VERSION "dbc-export 1 2025.20.8"

NS_ :

BS_:

BU_: APP BMS CC CMP CMPD CP DAS DI DIF DIR EPBL EPBR EVSE FC GTW HCML HCMR HVP ICR PCS PM PMF PMR PTC SCCM SCM SCS SDCR TAS UMC VC VCFRONT VCLEFT VCRIGHT VCSEC

BO_ 1523 UI_odo: 3 GTW
 SG_ UI_odometer : 0|24@1+ (0.1,0) [0|1677721.4] "km" Vector__XXX

BO_ 948 UI_peripheralPowerRequests: 1 GTW
 SG_ UI_usbFrontHubPowerStateRequest : 0|2@1+ (1,0) [1|3] "" Vector__XXX

BO_ 955 UI_power: 2 GTW
 SG_ UI_powerExpected : 0|8@1+ (1,0) [0|255] "kW" Vector__XXX
 SG_ UI_powerIdeal : 8|8@1+ (1,0) [0|255] "kW" Vector__XXX

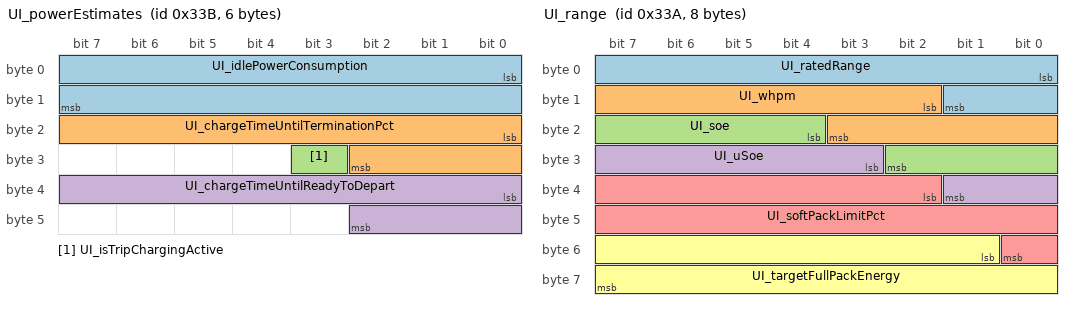
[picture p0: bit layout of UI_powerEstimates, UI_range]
BO_ 827 UI_powerEstimates: 6 GTW
 SG_ UI_idlePowerConsumption : 0|16@1+ (0.001,0) [0|50] "kW" Vector__XXX
 SG_ UI_chargeTimeUntilTerminationPct : 16|11@1+ (1,0) [0|2046] "min" Vector__XXX
 SG_ UI_isTripChargingActive : 27|1@1+ (1,0) [0|1] "" Vector__XXX
 SG_ UI_chargeTimeUntilReadyToDepart : 32|11@1+ (1,0) [0|2046] "min" Vector__XXX

BO_ 661 UI_powerRationalityConfig: 8 GTW
 SG_ UI_powerRationalityConfigIndex M : 56|8@1+ (1,0) [0|255] "" Vector__XXX
 SG_ UI_vcleftCfgRationalityThreshold m0 : 0|4@1+ (1,0) [1|15] "" Vector__XXX
 SG_ UI_vcleftCfgRationalityTime0 m0 : 4|4@1+ (1,0) [1|15] "" Vector__XXX
 SG_ UI_vcleftCfgRationalityThre_0001 m0 : 8|4@1+ (1,0) [1|15] "" Vector__XXX
 SG_ UI_vcleftCfgRationalityTime1 m0 : 12|4@1+ (1,0) [1|15] "" Vector__XXX
 SG_ UI_vcleftCfgRationalityStaticA m1 : 0|16@1+ (50,0) [0|3276700] "-" Vector__XXX
 SG_ UI_vcleftCfgRationalityStaticB m1 : 16|16@1- (1,0) [-32768|32767] "-" Vector__XXX
 SG_ UI_vcleftCfgRationalityStaticC m1 : 32|16@1- (50,0) [-1638400|1638350] "-" Vector__XXX
 SG_ UI_vcleftCfgRationalityDynamicA m2 : 0|16@1+ (50,0) [0|3276700] "-" Vector__XXX
 SG_ UI_vcleftCfgRationalityDynamicB m2 : 16|16@1- (1,0) [-32768|32767] "-" Vector__XXX
 SG_ UI_vcleftCfgRationalityDynamicC m2 : 32|16@1- (50,0) [-1638400|1638350] "-" Vector__XXX
 SG_ UI_vcrightCfgRationalityThreshol m3 : 0|4@1+ (1,0) [1|15] "" Vector__XXX
 SG_ UI_vcrightCfgRationalityTime0 m3 : 4|4@1+ (1,0) [1|15] "" Vector__XXX
 SG_ UI_vcrightCfgRationalityThr_0001 m3 : 8|4@1+ (1,0) [1|15] "" Vector__XXX
 SG_ UI_vcrightCfgRationalityTime1 m3 : 12|4@1+ (1,0) [1|15] "" Vector__XXX
 SG_ UI_vcrightCfgRationalityStaticA m4 : 0|16@1+ (50,0) [0|3276700] "-" Vector__XXX
 SG_ UI_vcrightCfgRationalityStaticB m4 : 16|16@1- (1,0) [-32768|32767] "-" Vector__XXX
 SG_ UI_vcrightCfgRationalityStaticC m4 : 32|16@1- (50,0) [-1638400|1638350] "-" Vector__XXX
 SG_ UI_vcrightCfgRationalityDynamicA m5 : 0|16@1+ (50,0) [0|3276700] "-" Vector__XXX
 SG_ UI_vcrightCfgRationalityDynamicB m5 : 16|16@1- (1,0) [-32768|32767] "-" Vector__XXX
 SG_ UI_vcrightCfgRationalityDynamicC m5 : 32|16@1- (50,0) [-1638400|1638350] "-" Vector__XXX
 SG_ UI_vcleftCfgCutoffThreshold0 m6 : 0|4@1+ (1,0) [1|15] "" Vector__XXX
 SG_ UI_vcleftCfgCutoffTime0 m6 : 4|4@1+ (1,0) [1|15] "" Vector__XXX
 SG_ UI_vcleftCfgCutoffThreshold1 m6 : 8|4@1+ (1,0) [1|15] "" Vector__XXX
 SG_ UI_vcleftCfgCutoffTime1 m6 : 12|4@1+ (1,0) [1|15] "" Vector__XXX
 SG_ UI_vcleftCfgCutoffStaticA m7 : 0|16@1+ (50,0) [0|3276700] "-" Vector__XXX
 SG_ UI_vcleftCfgCutoffStaticB m7 : 16|16@1- (1,0) [-32768|32767] "-" Vector__XXX
 SG_ UI_vcleftCfgCutoffStaticC m7 : 32|16@1- (50,0) [-1638400|1638350] "-" Vector__XXX
 SG_ UI_vcleftCfgCutoffDynamicA m8 : 0|16@1+ (50,0) [0|3276700] "-" Vector__XXX
 SG_ UI_vcleftCfgCutoffDynamicB m8 : 16|16@1- (1,0) [-32768|32767] "-" Vector__XXX
 SG_ UI_vcleftCfgCutoffDynamicC m8 : 32|16@1- (50,0) [-1638400|1638350] "-" Vector__XXX
 SG_ UI_vcrightCfgCutoffThreshold0 m9 : 0|4@1+ (1,0) [1|15] "" Vector__XXX
 SG_ UI_vcrightCfgCutoffTime0 m9 : 4|4@1+ (1,0) [1|15] "" Vector__XXX
 SG_ UI_vcrightCfgCutoffThreshold1 m9 : 8|4@1+ (1,0) [1|15] "" Vector__XXX
 SG_ UI_vcrightCfgCutoffTime1 m9 : 12|4@1+ (1,0) [1|15] "" Vector__XXX
 SG_ UI_vcrightCfgCutoffStaticA m10 : 0|16@1+ (50,0) [0|3276700] "-" Vector__XXX
 SG_ UI_vcrightCfgCutoffStaticB m10 : 16|16@1- (1,0) [-32768|32767] "-" Vector__XXX
 SG_ UI_vcrightCfgCutoffStaticC m10 : 32|16@1- (50,0) [-1638400|1638350] "-" Vector__XXX
 SG_ UI_vcrightCfgCutoffDynamicA m11 : 0|16@1+ (50,0) [0|3276700] "-" Vector__XXX
 SG_ UI_vcrightCfgCutoffDynamicB m11 : 16|16@1- (1,0) [-32768|32767] "-" Vector__XXX
 SG_ UI_vcrightCfgCutoffDynamicC m11 : 32|16@1- (50,0) [-1638400|1638350] "-" Vector__XXX

BO_ 820 UI_powertrainControl: 8 GTW
 SG_ UI_systemPowerLimit : 0|5@1+ (20,20) [20|620] "kW" Vector__XXX
 SG_ UI_pedalMap : 5|2@1+ (1,0) [0|3] "" Vector__XXX
 SG_ UI_enableRegenBackfill : 7|1@1+ (1,0) [0|1] "" Vector__XXX
 SG_ UI_systemTorqueLimit : 8|6@1+ (150,1000) [1000|10300] "Nm" Vector__XXX
 SG_ UI_closureConfirmed : 14|2@1+ (1,0) [0|3] "" Vector__XXX
 SG_ UI_regenTorqueMax : 16|5@1+ (5,0) [0|100] "%" Vector__XXX
 SG_ UI_limitMode : 21|2@1+ (1,0) [0|3] "" Vector__XXX
 SG_ UI_factoryCustomerDrivingModeReq : 23|1@1+ (1,0) [0|1] "" Vector__XXX
 SG_ UI_motorOnMode : 24|2@1+ (1,0) [0|3] "" Vector__XXX
 SG_ UI_wasteMode : 26|2@1+ (1,0) [0|3] "" Vector__XXX
 SG_ UI_wasteModeRegenLimit : 28|2@1+ (1,0) [0|3] "" Vector__XXX
 SG_ UI_stoppingMode : 30|2@1+ (1,0) [0|3] "" Vector__XXX
 SG_ UI_DIAppSliderDebug : 32|2@1+ (1,0) [0|3] "" Vector__XXX
 SG_ UI_speedLimit : 34|12@1+ (0.1,0) [0|335] "kph" Vector__XXX
 SG_ UI_enableSmartShift : 46|2@1+ (1,0) [0|3] "" Vector__XXX
 SG_ UI_navVehParallelToRdCanContinue : 49|2@1+ (1,0) [1|3] "" Vector__XXX
 SG_ UI_powertrainControlCounter : 52|4@1+ (1,0) [0|15] "" Vector__XXX
 SG_ UI_powertrainControlChecksum : 56|8@1+ (1,0) [0|255] "" Vector__XXX

BO_ 826 UI_range: 8 GTW
 SG_ UI_ratedRange : 0|10@1+ (1,0) [0|1023] "mi" Vector__XXX
 SG_ UI_whpm : 10|10@1+ (1,0) [0|1023] "" Vector__XXX
 SG_ UI_soe : 20|7@1+ (1,0) [0|127] "%" Vector__XXX
 SG_ UI_uSoe : 27|7@1+ (1,0) [0|127] "%" Vector__XXX
 SG_ UI_softPackLimitPct : 34|15@1+ (0.003051851,0) [0|100.000001717] "%" Vector__XXX
 SG_ UI_targetFullPackEnergy : 49|15@1+ (0.006103702,0) [0|200.000003434] "kWh" Vector__XXX

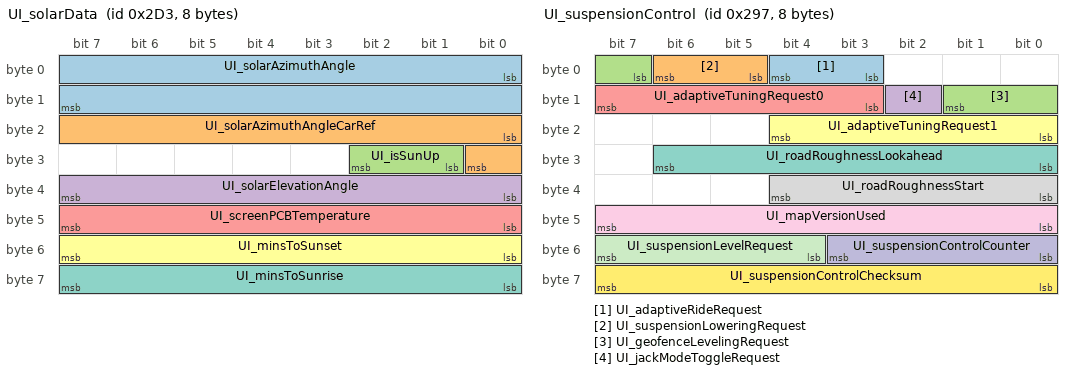
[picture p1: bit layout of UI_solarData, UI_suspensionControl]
BO_ 723 UI_solarData: 8 GTW
 SG_ UI_solarAzimuthAngle : 0|16@1- (1,0) [-32768|32767] "degrees" Vector__XXX
 SG_ UI_solarAzimuthAngleCarRef : 16|9@1- (1,0) [-256|254] "degrees" Vector__XXX
 SG_ UI_isSunUp : 25|2@1+ (1,0) [0|2] "" Vector__XXX
 SG_ UI_solarElevationAngle : 32|8@1- (1,0) [-128|126] "degrees" Vector__XXX
 SG_ UI_screenPCBTemperature : 40|8@1- (0.5,40) [-20|100] "degC" Vector__XXX
 SG_ UI_minsToSunset : 48|8@1+ (10,0) [0|2550] "min" Vector__XXX
 SG_ UI_minsToSunrise : 56|8@1+ (10,0) [0|2550] "min" Vector__XXX

BO_ 851 UI_status: 8 GTW
 SG_ UI_touchActive : 0|1@1+ (1,0) [0|1] "" Vector__XXX
 SG_ UI_audioActive : 1|1@1+ (1,0) [0|1] "" Vector__XXX
 SG_ UI_bluetoothActive : 2|1@1+ (1,0) [0|1] "" Vector__XXX
 SG_ UI_cellActive : 3|1@1+ (1,0) [0|1] "" Vector__XXX
 SG_ UI_displayReady : 4|1@1+ (1,0) [0|1] "" Vector__XXX
 SG_ UI_displayOn : 5|1@1+ (1,0) [0|1] "" Vector__XXX
 SG_ UI_wifiActive : 6|1@1+ (1,0) [0|1] "" Vector__XXX
 SG_ UI_wifiConnected : 7|1@1+ (1,0) [0|1] "" Vector__XXX
 SG_ UI_systemActive : 8|1@1+ (1,0) [0|1] "" Vector__XXX
 SG_ UI_readyForDrive : 9|1@1+ (1,0) [0|1] "" Vector__XXX
 SG_ UI_cellConnected : 10|1@1+ (1,0) [0|1] "" Vector__XXX
 SG_ UI_vpnActive : 11|1@1+ (1,0) [0|1] "" Vector__XXX
 SG_ UI_autopilotTrial : 12|2@1+ (1,0) [0|3] "" Vector__XXX
 SG_ UI_factoryReset : 14|2@1+ (1,0) [1|3] "" Vector__XXX
 SG_ UI_gpsActive : 16|1@1+ (1,0) [0|1] "" Vector__XXX
 SG_ UI_screenshotActive : 17|1@1+ (1,0) [0|1] "" Vector__XXX
 SG_ UI_radioActive : 18|1@1+ (1,0) [0|1] "" Vector__XXX
 SG_ UI_cellNetworkTechnology : 19|4@1+ (1,0) [0|14] "" Vector__XXX
 SG_ UI_cellReceiverPower : 24|8@1+ (1,-128) [-128|127] "dB" Vector__XXX
 SG_ UI_falseTouchCounter : 32|8@1+ (1,0) [0|255] "1" Vector__XXX
 SG_ UI_developmentCar : 40|1@1+ (1,0) [0|1] "" Vector__XXX
 SG_ UI_cameraActive : 41|1@1+ (1,0) [0|1] "" Vector__XXX
 SG_ UI_cellSignalBars : 42|3@1+ (1,0) [0|6] "" Vector__XXX
 SG_ UI_trailerModeTelltale : 45|2@1+ (1,0) [0|3] "" Vector__XXX
 SG_ UI_pcbTemperature : 48|8@1- (1,40) [-20|100] "degC" Vector__XXX
 SG_ UI_cpuTemperature : 56|8@1- (1,40) [-20|100] "degC" Vector__XXX

BO_ 991 UI_status2: 8 GTW
 SG_ UI_mobileAppStepCount : 0|16@1+ (1,0) [0|65535] "" Vector__XXX
 SG_ UI_userRequestSnapshot : 16|1@1+ (1,0) [0|1] "" Vector__XXX
 SG_ UI_touchDetected : 17|1@1+ (1,0) [0|1] "" Vector__XXX
 SG_ UI_validDeviceForEUSummon : 18|1@1+ (1,0) [0|1] "" Vector__XXX
 SG_ UI_locatedAtHome : 19|1@1+ (1,0) [0|1] "" Vector__XXX
 SG_ UI_locatedAtWork : 20|1@1+ (1,0) [0|1] "" Vector__XXX
 SG_ UI_locatedAtFavorite : 21|1@1+ (1,0) [0|1] "" Vector__XXX
 SG_ UI_displayInDarkMode : 22|1@1+ (1,0) [0|1] "" Vector__XXX
 SG_ UI_userActivity : 23|1@1+ (1,0) [0|1] "" Vector__XXX
 SG_ UI_activeTouchPoints : 24|8@1+ (1,0) [0|255] "1" Vector__XXX
 SG_ UI_linkState : 32|2@1+ (1,0) [0|3] "" Vector__XXX
 SG_ UI_sentryModeState : 34|3@1+ (1,0) [0|7] "" Vector__XXX
 SG_ UI_autopilotSentryRequest : 37|1@1+ (1,0) [0|1] "" Vector__XXX
 SG_ UI_mobileAppConnected : 38|1@1+ (1,0) [0|1] "" Vector__XXX
 SG_ UI_autoshiftDRState : 40|3@1+ (1,0) [0|7] "" Vector__XXX
 SG_ UI_wifiBtModuleType : 43|3@1+ (1,0) [0|7] "" Vector__XXX
 SG_ UI_sohHealthStatus : 46|2@1+ (1,0) [0|3] "" Vector__XXX
 SG_ UI_selfParkState : 48|8@1+ (1,0) [0|254] "" Vector__XXX
 SG_ UI_summonDeviceIndex : 56|2@1+ (1,0) [0|3] "" Vector__XXX
 SG_ UI_sentryModeCameraDetection : 58|1@1+ (1,0) [0|1] "" Vector__XXX
 SG_ UI_wakeOnIPActive : 59|1@1+ (1,0) [0|1] "" Vector__XXX

BO_ 663 UI_suspensionControl: 8 GTW
 SG_ UI_adaptiveRideRequest : 3|2@1+ (1,0) [0|3] "" Vector__XXX
 SG_ UI_suspensionLoweringRequest : 5|2@1+ (1,0) [0|2] "" Vector__XXX
 SG_ UI_geofenceLevelingRequest : 7|3@1+ (1,0) [0|7] "" Vector__XXX
 SG_ UI_jackModeToggleRequest : 10|1@1+ (1,0) [0|1] "" Vector__XXX
 SG_ UI_adaptiveTuningRequest0 : 11|5@1- (0.1,0) [-1.6|1.5] "-" Vector__XXX
 SG_ UI_adaptiveTuningRequest1 : 16|5@1- (0.1,0) [-1.6|1.5] "-" Vector__XXX
 SG_ UI_roadRoughnessLookahead : 24|7@1+ (0.01,0) [0|1.26] "%" Vector__XXX
 SG_ UI_roadRoughnessStart : 32|5@1+ (10,0) [0|300] "m" Vector__XXX
 SG_ UI_mapVersionUsed : 40|8@1+ (1,0) [0|254] "-" Vector__XXX
 SG_ UI_suspensionControlCounter : 48|4@1+ (1,0) [0|15] "" Vector__XXX
 SG_ UI_suspensionLevelRequest : 52|4@1+ (1,0) [0|15] "" Vector__XXX
 SG_ UI_suspensionControlChecksum : 56|8@1+ (1,0) [0|255] "" Vector__XXX

BO_ 956 UI_tpmsRCPsetting: 4 GTW
 SG_ UI_setRCPFront : 16|8@1+ (0.025,0) [0|6.375] "bar" Vector__XXX
 SG_ UI_setRCPRear : 24|8@1+ (0.025,0) [0|6.375] "bar" Vector__XXX

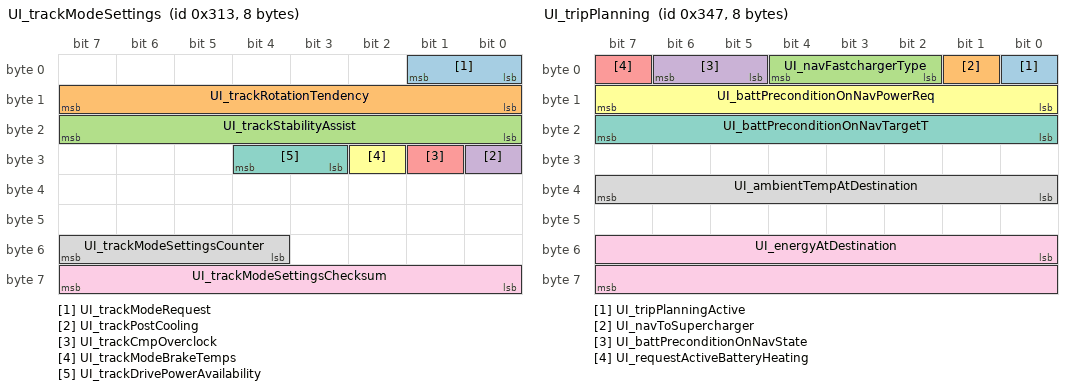
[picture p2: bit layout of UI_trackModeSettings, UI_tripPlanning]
BO_ 787 UI_trackModeSettings: 8 GTW
 SG_ UI_trackModeRequest : 0|2@1+ (1,0) [0|3] "" Vector__XXX
 SG_ UI_trackRotationTendency : 8|8@1+ (0.5,0) [0|127.5] "%" Vector__XXX
 SG_ UI_trackStabilityAssist : 16|8@1+ (0.5,0) [0|127.5] "%" Vector__XXX
 SG_ UI_trackPostCooling : 24|1@1+ (1,0) [0|1] "" Vector__XXX
 SG_ UI_trackCmpOverclock : 25|1@1+ (1,0) [0|1] "" Vector__XXX
 SG_ UI_trackModeBrakeTemps : 26|1@1+ (1,0) [0|1] "" Vector__XXX
 SG_ UI_trackDrivePowerAvailability : 27|2@1+ (1,0) [0|3] "" Vector__XXX
 SG_ UI_trackModeSettingsCounter : 52|4@1+ (1,0) [0|15] "" Vector__XXX
 SG_ UI_trackModeSettingsChecksum : 56|8@1+ (1,0) [0|255] "" Vector__XXX

BO_ 839 UI_tripPlanning: 8 GTW
 SG_ UI_tripPlanningActive : 0|1@1+ (1,0) [0|1] "" Vector__XXX
 SG_ UI_navToSupercharger : 1|1@1+ (1,0) [0|1] "" Vector__XXX
 SG_ UI_navFastchargerType : 2|3@1+ (1,0) [0|7] "" Vector__XXX
 SG_ UI_battPreconditionOnNavState : 5|2@1+ (1,0) [0|3] "" Vector__XXX
 SG_ UI_requestActiveBatteryHeating : 7|1@1+ (1,0) [0|1] "" Vector__XXX
 SG_ UI_battPreconditionOnNavPowerReq : 8|8@1- (125,0) [-16000|15750] "W" Vector__XXX
 SG_ UI_battPreconditionOnNavTargetT : 16|8@1+ (0.25,0) [0|63.5] "degC" Vector__XXX
 SG_ UI_ambientTempAtDestination : 32|8@1- (0.5,0) [-64|63.5] "degC" Vector__XXX
 SG_ UI_energyAtDestination : 48|16@1- (0.01,0) [-327.67|327.67] "kWh" Vector__XXX

BO_ 627 UI_vehicleControl: 8 GTW
 SG_ UI_powerStateRequest : 0|2@1+ (1,0) [0|3] "" Vector__XXX
 SG_ UI_childDoorLockOnRight : 2|1@1+ (1,0) [0|1] "" Vector__XXX
 SG_ UI_frontFogSwitch : 3|1@1+ (1,0) [0|1] "" Vector__XXX
 SG_ UI_summonActive : 4|1@1+ (1,0) [0|1] "" Vector__XXX
 SG_ UI_frunkRequest : 5|1@1+ (1,0) [0|1] "" Vector__XXX
 SG_ UI_wiperMode : 6|2@1+ (1,0) [1|3] "" Vector__XXX
 SG_ UI_steeringBacklightEnabled : 8|1@1+ (1,0) [0|1] "" Vector__XXX
 SG_ UI_steeringButtonMode : 9|3@1+ (1,0) [0|7] "" Vector__XXX
 SG_ UI_walkUpUnlock : 12|1@1+ (1,0) [0|1] "" Vector__XXX
 SG_ UI_walkAwayLock : 13|1@1+ (1,0) [0|1] "" Vector__XXX
 SG_ UI_unlockOnPark : 14|1@1+ (1,0) [0|1] "" Vector__XXX
 SG_ UI_globalUnlockOn : 15|1@1+ (1,0) [0|1] "" Vector__XXX
 SG_ UI_childDoorLockOnLeft : 16|1@1+ (1,0) [0|1] "" Vector__XXX
 SG_ UI_lockRequest : 17|3@1+ (1,0) [0|6] "" Vector__XXX
 SG_ UI_alarmEnabled : 20|1@1+ (1,0) [0|1] "" Vector__XXX
 SG_ UI_intrusionSensorOn : 21|1@1+ (1,0) [0|1] "" Vector__XXX
 SG_ UI_stop12vSupport : 22|1@1+ (1,0) [0|1] "" Vector__XXX
 SG_ UI_rearFogSwitch : 23|1@1+ (1,0) [0|1] "" Vector__XXX
 SG_ UI_mirrorFoldRequest : 24|2@1+ (1,0) [0|2] "" Vector__XXX
 SG_ UI_mirrorHeatRequest : 26|1@1+ (1,0) [0|1] "" Vector__XXX
 SG_ UI_remoteStartRequest : 27|3@1+ (1,0) [0|7] "" Vector__XXX
 SG_ UI_seeYouHomeLightingOn : 30|1@1+ (1,0) [0|1] "" Vector__XXX
 SG_ UI_powerOff : 31|1@1+ (1,0) [0|1] "" Vector__XXX
 SG_ UI_displayBrightnessLevel : 32|8@1+ (0.5,0) [0|127] "%" Vector__XXX
 SG_ UI_ambientLightingEnabled : 40|1@1+ (1,0) [0|1] "" Vector__XXX
 SG_ UI_autoHighBeamEnabled : 41|1@1+ (1,0) [0|1] "" Vector__XXX
 SG_ UI_frontLeftSeatHeatReq : 42|2@1+ (1,0) [0|3] "" Vector__XXX
 SG_ UI_frontRightSeatHeatReq : 44|2@1+ (1,0) [0|3] "" Vector__XXX
 SG_ UI_rearLeftSeatHeatReq : 46|2@1+ (1,0) [0|3] "" Vector__XXX
 SG_ UI_rearCenterSeatHeatReq : 48|2@1+ (1,0) [0|3] "" Vector__XXX
 SG_ UI_rearRightSeatHeatReq : 50|2@1+ (1,0) [0|3] "" Vector__XXX
 SG_ UI_autoFoldMirrorsOn : 52|1@1+ (1,0) [0|1] "" Vector__XXX
 SG_ UI_mirrorDipOnReverse : 53|1@1+ (1,0) [0|1] "" Vector__XXX
 SG_ UI_remoteClosureRequest : 54|2@1+ (1,0) [0|2] "" Vector__XXX
 SG_ UI_wiperRequest : 56|3@1+ (1,0) [1|7] "" Vector__XXX
 SG_ UI_domeLightSwitch : 59|2@1+ (1,0) [0|3] "" Vector__XXX
 SG_ UI_honkHorn : 61|1@1+ (1,0) [0|1] "" Vector__XXX
 SG_ UI_driveStateRequest : 62|1@1+ (1,0) [0|1] "" Vector__XXX
 SG_ UI_rearWindowLockout : 63|1@1+ (1,0) [0|1] "" Vector__XXX

BO_ 947 UI_vehicleControl2: 8 GTW
 SG_ UI_gloveboxRequest : 0|1@1+ (1,0) [0|1] "" Vector__XXX
 SG_ UI_trunkRequest : 1|1@1+ (1,0) [0|1] "" Vector__XXX
 SG_ UI_UMCUpdateInhibit : 2|1@1+ (1,0) [0|1] "" Vector__XXX
 SG_ UI_WCUpdateInhibit : 3|1@1+ (1,0) [0|1] "" Vector__XXX
 SG_ UI_soundHornOnLock : 4|1@1+ (1,0) [0|1] "" Vector__XXX
 SG_ UI_locksPanelActive : 5|1@1+ (1,0) [0|1] "" Vector__XXX
 SG_ UI_PINToDriveEnabled : 6|1@1+ (1,0) [0|1] "" Vector__XXX
 SG_ UI_PINToDrivePassed : 7|1@1+ (1,0) [0|1] "" Vector__XXX
 SG_ UI_disableMirrorAutoDim : 8|1@1+ (1,0) [0|1] "" Vector__XXX
 SG_ UI_lightSwitch : 9|3@1+ (1,0) [0|7] "" Vector__XXX
 SG_ UI_readyToAddKey : 12|1@1+ (1,0) [0|1] "" Vector__XXX
 SG_ UI_alarmTriggerRequest : 13|1@1+ (1,0) [0|1] "" Vector__XXX
 SG_ UI_VCSECFeature1 : 14|1@1+ (1,0) [0|1] "" Vector__XXX
 SG_ UI_VCLEFTFeature1 : 15|1@1+ (1,0) [0|1] "" Vector__XXX
 SG_ UI_summonState : 16|2@1+ (1,0) [1|3] "" Vector__XXX
 SG_ UI_displayOnForUser : 18|1@1+ (1,0) [0|1] "" Vector__XXX
 SG_ UI_freeRollModeRequest : 19|1@1+ (1,0) [0|1] "" Vector__XXX
 SG_ UI_BLEPushNotificationRequest : 20|1@1+ (1,0) [0|1] "" Vector__XXX
 SG_ UI_pairKeyQRCodeDisplaying : 21|1@1+ (1,0) [0|1] "" Vector__XXX
 SG_ UI_keepAutopilotAwake : 22|1@1+ (1,0) [0|1] "" Vector__XXX
 SG_ UI_batteryPreconditioningRequest : 23|1@1+ (1,0) [0|1] "" Vector__XXX
 SG_ UI_coastDownMode : 24|1@1+ (1,0) [0|1] "" Vector__XXX
 SG_ UI_autopilotPowerStateRequest : 25|2@1+ (1,0) [0|3] "" Vector__XXX
 SG_ UI_shorted12VCellTestMode : 27|2@1+ (1,0) [0|3] "" Vector__XXX
 SG_ UI_autoRollWindowsOnLockEnable : 29|1@1+ (1,0) [0|1] "" Vector__XXX
 SG_ UI_virtualPitchSensorOverrideOKF : 30|1@1+ (1,0) [0|1] "" Vector__XXX
 SG_ UI_conditionalLoggingEnabledVCSE : 31|1@1+ (1,0) [0|1] "" Vector__XXX
 SG_ UI_WC3UpdateInhibit : 32|1@1+ (1,0) [0|1] "" Vector__XXX
 SG_ UI_steeringWheelHeatReq : 33|1@1+ (1,0) [0|1] "" Vector__XXX
 SG_ UI_disableHorn : 34|1@1+ (1,0) [0|1] "" Vector__XXX
 SG_ UI_frontLeftSeatFanReq : 37|2@1+ (1,0) [0|3] "" Vector__XXX
 SG_ UI_frontRightSeatAutoClimateReq : 39|1@1+ (1,0) [0|1] "" Vector__XXX
 SG_ UI_frontRightSeatFanReq : 40|2@1+ (1,0) [0|3] "" Vector__XXX
 SG_ UI_sleepFeature1 : 51|1@1+ (1,0) [0|1] "" Vector__XXX
 SG_ UI_dcr12VThreshold : 52|4@1+ (1,0) [0|15] "" Vector__XXX
 SG_ UI_frontLeftSeatAutoClimateReq : 56|1@1+ (1,0) [0|1] "" Vector__XXX
 SG_ UI_wiperHeaterReq : 57|1@1+ (1,0) [0|1] "" Vector__XXX
 SG_ UI_tireSeason : 59|1@1+ (1,0) [0|1] "" Vector__XXX
 SG_ UI_saveTireConfigReq : 60|1@1+ (1,0) [0|1] "" Vector__XXX
 SG_ UI_silentAlarm : 61|1@1+ (1,0) [0|1] "" Vector__XXX
 SG_ UI_sleepFeature2 : 63|1@1+ (1,0) [0|1] "" Vector__XXX

BO_ 660 UI_vehicleControl3: 8 GTW
 SG_ UI_lightFlashRequest : 0|2@1+ (1,0) [0|3] "" Vector__XXX
 SG_ UI_keylessDrivingEnabled : 2|1@1+ (1,0) [0|1] "" Vector__XXX
 SG_ UI_phoneCallActive : 3|1@1+ (1,0) [0|1] "" Vector__XXX
 SG_ UI_drivingSideVEH : 4|2@1+ (1,0) [0|3] "" Vector__XXX
 SG_ UI_keyPairResponse : 6|2@1+ (1,0) [0|3] "" Vector__XXX
 SG_ UI_lightShowClosuresEnabled : 8|1@1+ (1,0) [0|1] "" Vector__XXX
 SG_ UI_steeringWheelHeatAutoReq : 9|1@1+ (1,0) [0|1] "" Vector__XXX
 SG_ UI_steeringWheelHeatLevelReq : 10|2@1+ (1,0) [0|3] "" Vector__XXX
 SG_ UI_headlightPulseRequest : 12|1@1+ (1,0) [0|1] "" Vector__XXX
 SG_ UI_VCSECFeature2 : 13|1@1+ (1,0) [0|1] "" Vector__XXX
 SG_ UI_VCSECFeature3 : 14|1@1+ (1,0) [0|1] "" Vector__XXX
 SG_ UI_VCSECFeature4 : 15|1@1+ (1,0) [0|1] "" Vector__XXX
 SG_ UI_VCSECFeature5 : 16|1@1+ (1,0) [0|1] "" Vector__XXX
 SG_ UI_shortHornRequest : 17|1@1+ (1,0) [0|1] "" Vector__XXX
 SG_ UI_packTempLoggingRequest : 18|1@1+ (1,0) [0|1] "" Vector__XXX
 SG_ UI_UMC3UpdateInhibit : 22|1@1+ (1,0) [0|1] "" Vector__XXX
 SG_ UI_handsFreeTrunk : 23|1@1+ (1,0) [0|1] "" Vector__XXX
 SG_ UI_displayRedShiftActive : 24|1@1+ (1,0) [0|1] "" Vector__XXX
 SG_ UI_handsFreeFrunk : 25|1@1+ (1,0) [0|1] "" Vector__XXX
 SG_ UI_fasciaCameraWashRequest : 26|1@1+ (1,0) [0|1] "" Vector__XXX
 SG_ UI_autoClosuresExcludeHome : 27|1@1+ (1,0) [0|1] "" Vector__XXX
 SG_ UI_leftRearSeatAdjustmentRequest : 28|3@1+ (1,0) [0|7] "" Vector__XXX
 SG_ UI_rightRearSeatAdjustmentReques : 32|3@1+ (1,0) [0|7] "" Vector__XXX
 SG_ UI_blindSpotIndicatorLightReques : 35|1@1+ (1,0) [0|1] "" Vector__XXX
 SG_ UI_etcBluetoothControl : 36|2@1+ (1,0) [0|3] "" Vector__XXX
 SG_ UI_keepOnAccessoryPortsReq : 38|1@1+ (1,0) [0|1] "" Vector__XXX
 SG_ UI_fasciaCameraShown : 39|1@1+ (1,0) [0|1] "" Vector__XXX
 SG_ UI_rearSeatChildLock : 40|2@1+ (1,0) [0|3] "" Vector__XXX
 SG_ UI_windowPercentageRequest : 42|6@1- (5,0) [-100|100] "%" Vector__XXX
 SG_ UI_windowRequestedFL : 48|1@1+ (1,0) [0|1] "" Vector__XXX
 SG_ UI_windowRequestedFR : 49|1@1+ (1,0) [0|1] "" Vector__XXX
 SG_ UI_windowRequestedRL : 50|1@1+ (1,0) [0|1] "" Vector__XXX
 SG_ UI_windowRequestedRR : 51|1@1+ (1,0) [0|1] "" Vector__XXX
 SG_ UI_windowRequest : 52|3@1+ (1,0) [0|7] "" Vector__XXX
 SG_ UI_closeTrunkRequest : 55|1@1+ (1,0) [0|1] "" Vector__XXX
 SG_ UI_childPresenceDetectionDisable : 56|1@1+ (1,0) [0|1] "" Vector__XXX
 SG_ UI_derivedLoadshedFeature : 59|1@1+ (1,0) [0|1] "" Vector__XXX
 SG_ UI_rearSeatFoldConfirmed : 60|1@1+ (1,0) [0|1] "" Vector__XXX
 SG_ UI_leftRearSeatRequestFromRearDi : 61|1@1+ (1,0) [0|1] "" Vector__XXX
 SG_ UI_selfParkStandingBy : 62|1@1+ (1,0) [0|1] "" Vector__XXX
 SG_ UI_rightRearSeatRequestFromRearD : 63|1@1+ (1,0) [0|1] "" Vector__XXX

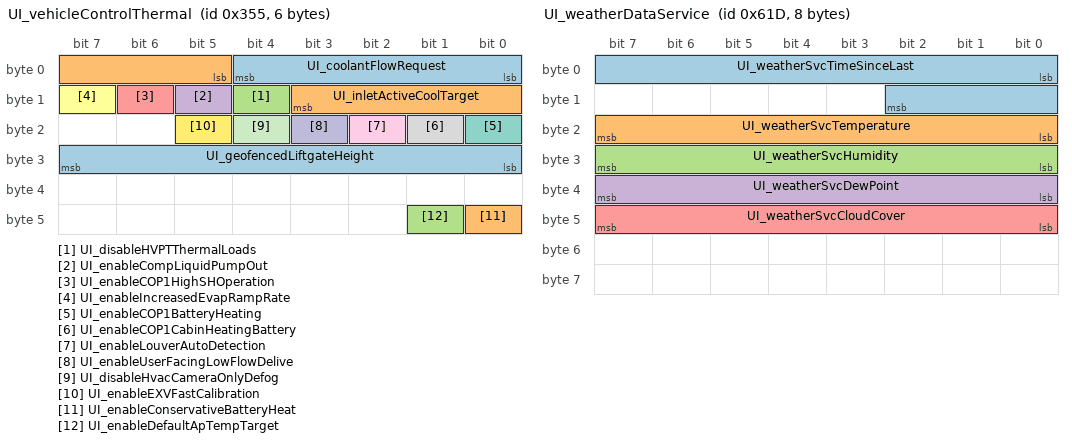
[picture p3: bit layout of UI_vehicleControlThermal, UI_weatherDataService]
BO_ 853 UI_vehicleControlThermal: 6 GTW
 SG_ UI_coolantFlowRequest : 0|5@1+ (1,0) [0|25] "LPM" Vector__XXX
 SG_ UI_inletActiveCoolTarget : 5|7@1+ (1,0) [0|127] "degC" Vector__XXX
 SG_ UI_disableHVPTThermalLoads : 12|1@1+ (1,0) [0|1] "" Vector__XXX
 SG_ UI_enableCompLiquidPumpOut : 13|1@1+ (1,0) [0|1] "" Vector__XXX
 SG_ UI_enableCOP1HighSHOperation : 14|1@1+ (1,0) [0|1] "" Vector__XXX
 SG_ UI_enableIncreasedEvapRampRate : 15|1@1+ (1,0) [0|1] "" Vector__XXX
 SG_ UI_enableCOP1BatteryHeating : 16|1@1+ (1,0) [0|1] "" Vector__XXX
 SG_ UI_enableCOP1CabinHeatingBattery : 17|1@1+ (1,0) [0|1] "" Vector__XXX
 SG_ UI_enableLouverAutoDetection : 18|1@1+ (1,0) [0|1] "" Vector__XXX
 SG_ UI_enableUserFacingLowFlowDelive : 19|1@1+ (1,0) [0|1] "" Vector__XXX
 SG_ UI_disableHvacCameraOnlyDefog : 20|1@1+ (1,0) [0|1] "" Vector__XXX
 SG_ UI_enableEXVFastCalibration : 21|1@1+ (1,0) [0|1] "" Vector__XXX
 SG_ UI_geofencedLiftgateHeight : 24|8@1+ (1,0) [0|254] "cm" Vector__XXX
 SG_ UI_enableConservativeBatteryHeat : 40|1@1+ (1,0) [0|1] "" Vector__XXX
 SG_ UI_enableDefaultApTempTarget : 41|1@1+ (1,0) [0|1] "" Vector__XXX

BO_ 644 UI_vehicleModes: 8 GTW
 SG_ UI_factoryMode : 0|1@1+ (1,0) [0|1] "" Vector__XXX
 SG_ UI_transportMode : 1|1@1+ (1,0) [0|1] "" Vector__XXX
 SG_ UI_showroomMode : 2|1@1+ (1,0) [0|1] "" Vector__XXX
 SG_ UI_serviceMode : 3|1@1+ (1,0) [0|1] "" Vector__XXX
 SG_ UI_isDelivered : 4|1@1+ (1,0) [0|1] "" Vector__XXX
 SG_ UI_hasEverBeenDelivered : 5|1@1+ (1,0) [0|1] "" Vector__XXX
 SG_ UI_homelinkV2Command0 : 8|8@1+ (1,0) [0|255] "" Vector__XXX
 SG_ UI_homelinkV2Command1 : 16|8@1+ (1,0) [0|255] "" Vector__XXX
 SG_ UI_homelinkV2Command2 : 24|8@1+ (1,0) [0|255] "" Vector__XXX
 SG_ UI_carWashMode : 32|1@1+ (1,0) [0|1] "" Vector__XXX
 SG_ UI_valetMode : 33|1@1+ (1,0) [0|1] "" Vector__XXX
 SG_ UI_gameMode : 34|1@1+ (1,0) [0|1] "" Vector__XXX
 SG_ UI_diagnosticsAllowed : 35|1@1+ (1,0) [0|1] "" Vector__XXX
 SG_ UI_serviceModePlus : 36|1@1+ (1,0) [0|1] "" Vector__XXX
 SG_ UI_premiumAmpPowerOff : 37|1@1+ (1,0) [0|1] "" Vector__XXX
 SG_ UI_signedCmdHardLocked : 38|1@1+ (1,0) [0|1] "" Vector__XXX
 SG_ UI_signedCmdServiceMode : 39|1@1+ (1,0) [0|1] "" Vector__XXX
 SG_ UI_closureEasterEggStatus : 40|2@1+ (1,0) [0|3] "" Vector__XXX
 SG_ UI_lightShowType : 42|3@1+ (1,0) [0|7] "" Vector__XXX
 SG_ UI_sohTestRequest : 45|1@1+ (1,0) [0|1] "" Vector__XXX
 SG_ UI_vehicleModesCounter : 52|4@1+ (1,0) [0|15] "" Vector__XXX
 SG_ UI_vehicleModesChecksum : 56|8@1+ (1,0) [0|255] "" Vector__XXX

BO_ 595 UI_ventPanelControlRequest: 8 GTW
 SG_ UI_ventPanelControlRequestIndex M : 0|1@1+ (1,0) [0|1] "" Vector__XXX
 SG_ UI_ventPanelLeftPositionX m0 : 8|8@1+ (0.5,0) [0|100] "%" Vector__XXX
 SG_ UI_ventPanelLeftPositionY m0 : 16|8@1+ (0.5,0) [0|100] "%" Vector__XXX
 SG_ UI_ventPanelLeftLateralSplit m0 : 24|8@1+ (0.5,0) [0|100] "%" Vector__XXX
 SG_ UI_ventPanelRightPositionX m0 : 32|8@1+ (0.5,0) [0|100] "%" Vector__XXX
 SG_ UI_ventPanelRightPositionY m0 : 40|8@1+ (0.5,0) [0|100] "%" Vector__XXX
 SG_ UI_ventPanelRightLateralSplit m0 : 48|8@1+ (0.5,0) [0|100] "%" Vector__XXX
 SG_ UI_ventPanelLeftLateralMode m0 : 56|2@1+ (1,0) [0|3] "" Vector__XXX
 SG_ UI_ventPanelRightLateralMode m0 : 58|2@1+ (1,0) [0|3] "" Vector__XXX
 SG_ UI_hvacReqActiveVents m0 : 60|2@1+ (1,0) [0|3] "" Vector__XXX
 SG_ UI_vent2RLeftPositionX m1 : 8|8@1+ (0.5,0) [0|100] "%" Vector__XXX
 SG_ UI_vent2RLeftPositionY m1 : 16|8@1+ (0.5,0) [0|100] "%" Vector__XXX
 SG_ UI_vent2RRightPositionX m1 : 24|8@1+ (0.5,0) [0|100] "%" Vector__XXX
 SG_ UI_vent2RRightPositionY m1 : 32|8@1+ (0.5,0) [0|100] "%" Vector__XXX

BO_ 1565 UI_weatherDataService: 8 GTW
 SG_ UI_weatherSvcTimeSinceLast : 0|11@1+ (1,0) [0|2046] "minutes" Vector__XXX
 SG_ UI_weatherSvcTemperature : 16|8@1- (0.5,0) [-64|63] "degC" Vector__XXX
 SG_ UI_weatherSvcHumidity : 24|8@1+ (0.5,0) [0|127] "%" Vector__XXX
 SG_ UI_weatherSvcDewPoint : 32|8@1+ (0.5,0) [0|127] "degC" Vector__XXX
 SG_ UI_weatherSvcCloudCover : 40|8@1+ (0.5,0) [0|127] "%" Vector__XXX

BO_ 1533 UMC_alertLog: 8 UMC
 SG_ UMC_alertID M : 0|15@1+ (1,0) [0|32767] "" Vector__XXX
 SG_ UMC_alertType : 15|1@1+ (1,0) [0|1] "" Vector__XXX
 SG_ UMC_a001_groundImpedance m1 : 32|32@1+ (1,0) [0|4294967295] "Ohm" Vector__XXX
 SG_ UMC_a002_ccidRmsCurrent m2 : 16|12@1+ (0.001,0) [0|4.095] "A" Vector__XXX
 SG_ UMC_a002_ccidRmsCurrentAvg m2 : 28|12@1+ (0.001,0) [0|4.095] "A" Vector__XXX
 SG_ UMC_a002_ccidFaultReason m2 : 50|4@1+ (1,0) [1|15] "" Vector__XXX
 SG_ UMC_a002_ccidFaultBucket m2 : 54|4@1+ (1,0) [0|15] "" Vector__XXX
 SG_ UMC_a003_faultType m3 : 16|8@1+ (1,0) [0|255] "" Vector__XXX
 SG_ UMC_a003_ccidSelfTestDuty m3 : 24|16@1+ (0.0001,50) [50|56.5535] "A" Vector__XXX
 SG_ UMC_a003_ccidSelfTestCurrent m3 : 40|16@1+ (0.0001,0) [0|6.5535] "A" Vector__XXX
 SG_ UMC_a004_lineVoltage m4 : 16|16@1+ (1,0) [0|65535] "Vrms" Vector__XXX
 SG_ UMC_a004_inputVoltage m4 : 32|16@1+ (0.01,0) [0|655.35] "V" Vector__XXX
 SG_ UMC_a004_inputNeutralVoltage m4 : 48|16@1+ (0.01,0) [0|655.35] "V" Vector__XXX
 SG_ UMC_a005_lineVoltage m5 : 16|16@1+ (1,0) [0|65535] "Vrms" Vector__XXX
 SG_ UMC_a005_inputVoltage m5 : 32|16@1+ (0.01,0) [0|655.35] "V" Vector__XXX
 SG_ UMC_a005_inputNeutralVoltage m5 : 48|16@1+ (0.01,0) [0|655.35] "V" Vector__XXX
 SG_ UMC_a006_outputVoltage m6 : 16|16@1+ (1,0) [0|65535] "Vrms" Vector__XXX
 SG_ UMC_a006_faultType m6 : 32|4@1+ (1,0) [0|15] "" Vector__XXX
 SG_ UMC_a006_umcReceptacleVoltage m6 : 36|12@1+ (0.1,0) [0|409.5] "V" Vector__XXX
 SG_ UMC_a006_handleVoltage m6 : 48|12@1+ (0.1,0) [0|409.5] "V" Vector__XXX
 SG_ UMC_a006_line1StuckClosed m6 : 60|1@1+ (1,0) [0|1] "" Vector__XXX
 SG_ UMC_a006_line2StuckClosed m6 : 61|1@1+ (1,0) [0|1] "" Vector__XXX
 SG_ UMC_a007_pcbaTemp m7 : 16|16@1+ (1,0) [0|65535] "degC" Vector__XXX
 SG_ UMC_a008_wallPlugTemp m8 : 16|16@1+ (1,0) [0|65535] "degC" Vector__XXX
 SG_ UMC_a008_SA_region m8 : 32|4@1+ (1,0) [0|15] "" Vector__XXX
 SG_ UMC_a008_SA_current m8 : 40|8@1+ (1,0) [0|255] "A" Vector__XXX
 SG_ UMC_a009_vehConnTemp m9 : 16|16@1+ (1,0) [0|65535] "degC" Vector__XXX
 SG_ UMC_a010_inputTerminalsTemp m10 : 16|16@1+ (1,0) [0|65535] "degC" Vector__XXX
 SG_ UMC_a012_pilotHigh m12 : 16|12@1- (0.01,0) [-20.48|20.47] "V" Vector__XXX
 SG_ UMC_a012_pilotLow m12 : 28|12@1- (0.01,0) [-20.48|20.47] "V" Vector__XXX
 SG_ UMC_a013_SA_region m13 : 16|4@1+ (1,0) [0|15] "" Vector__XXX
 SG_ UMC_a013_SA_current m13 : 24|8@1+ (1,0) [0|255] "A" Vector__XXX
 SG_ UMC_a015_SA_region m15 : 16|4@1+ (1,0) [0|15] "" Vector__XXX
 SG_ UMC_a015_SA_current m15 : 24|8@1+ (1,0) [0|255] "A" Vector__XXX
 SG_ UMC_a016_pcbaTemp m16 : 16|16@1+ (1,0) [0|65535] "degC" Vector__XXX
 SG_ UMC_a017_wallPlugTemp m17 : 16|16@1+ (1,0) [0|65535] "degC" Vector__XXX
 SG_ UMC_a017_SA_region m17 : 32|4@1+ (1,0) [0|15] "" Vector__XXX
 SG_ UMC_a017_SA_current m17 : 40|8@1+ (1,0) [0|255] "A" Vector__XXX
 SG_ UMC_a018_vehConnTemp m18 : 16|16@1+ (1,0) [0|65535] "degC" Vector__XXX
 SG_ UMC_a019_inputTerminalsTemp m19 : 16|16@1+ (1,0) [0|65535] "degC" Vector__XXX
 SG_ UMC_a024_groundImpedance m24 : 32|32@1+ (1,0) [0|4294967295] "Ohm" Vector__XXX
 SG_ UMC_a040_groundImpedance m40 : 32|32@1+ (1,0) [0|4294967295] "Ohm" Vector__XXX

BO_ 824 UMC_alertMatrix1: 8 UMC
 SG_ UMC_a001_gndMonIntrptLineSide : 0|1@1+ (1,0) [0|1] "" Vector__XXX
 SG_ UMC_a002_GFCITripped : 1|1@1+ (1,0) [0|1] "" Vector__XXX
 SG_ UMC_a003_GFCISelfTestFault : 2|1@1+ (1,0) [0|1] "" Vector__XXX
 SG_ UMC_a004_inputOverVoltage : 3|1@1+ (1,0) [0|1] "" Vector__XXX
 SG_ UMC_a005_inputUnderVoltage : 4|1@1+ (1,0) [0|1] "" Vector__XXX
 SG_ UMC_a006_contactorWelded : 5|1@1+ (1,0) [0|1] "" Vector__XXX
 SG_ UMC_a007_pcbaOT : 6|1@1+ (1,0) [0|1] "" Vector__XXX
 SG_ UMC_a008_wallPlugOT : 7|1@1+ (1,0) [0|1] "" Vector__XXX
 SG_ UMC_a009_vehConnOT : 8|1@1+ (1,0) [0|1] "" Vector__XXX
 SG_ UMC_a010_inputOT : 9|1@1+ (1,0) [0|1] "" Vector__XXX
 SG_ UMC_a011_proxDisconnected : 10|1@1+ (1,0) [0|1] "" Vector__XXX
 SG_ UMC_a012_pilotFault : 11|1@1+ (1,0) [0|1] "" Vector__XXX
 SG_ UMC_a013_SA_Temperature : 12|1@1+ (1,0) [0|1] "" Vector__XXX
 SG_ UMC_a014_SA_Genealogy : 13|1@1+ (1,0) [0|1] "" Vector__XXX
 SG_ UMC_a015_SA_Connection : 14|1@1+ (1,0) [0|1] "" Vector__XXX
 SG_ UMC_a016_pcbaOTFoldback : 15|1@1+ (1,0) [0|1] "" Vector__XXX
 SG_ UMC_a017_wallPlugOTFoldback : 16|1@1+ (1,0) [0|1] "" Vector__XXX
 SG_ UMC_a018_vehConnOTFoldback : 17|1@1+ (1,0) [0|1] "" Vector__XXX
 SG_ UMC_a019_inputOTFoldback : 18|1@1+ (1,0) [0|1] "" Vector__XXX
 SG_ UMC_a020_applicationCRC : 19|1@1+ (1,0) [0|1] "" Vector__XXX
 SG_ UMC_a021_dataBus : 20|1@1+ (1,0) [0|1] "" Vector__XXX
 SG_ UMC_a022_criticalRAM : 21|1@1+ (1,0) [0|1] "" Vector__XXX
 SG_ UMC_a023_adcSelfTest : 22|1@1+ (1,0) [0|1] "" Vector__XXX
 SG_ UMC_a024_gndResistanceHigh : 23|1@1+ (1,0) [0|1] "" Vector__XXX
 SG_ UMC_a025_cntrOpenExpectedClose : 24|1@1+ (1,0) [0|1] "" Vector__XXX
 SG_ UMC_a026_vRefOutOfRange : 25|1@1+ (1,0) [0|1] "" Vector__XXX
 SG_ UMC_a027_watchdogExpired : 26|1@1+ (1,0) [0|1] "" Vector__XXX
 SG_ UMC_a028_processorBooted : 27|1@1+ (1,0) [0|1] "" Vector__XXX
 SG_ UMC_a029_acPowerLoss : 28|1@1+ (1,0) [0|1] "" Vector__XXX
 SG_ UMC_a030_acLostPllLock : 29|1@1+ (1,0) [0|1] "" Vector__XXX
 SG_ UMC_a031_relayCoilVIrrational : 30|1@1+ (1,0) [0|1] "" Vector__XXX
 SG_ UMC_a032_chcVitalsRequestFailure : 31|1@1+ (1,0) [0|1] "" Vector__XXX
 SG_ UMC_a033_chcUpdateFault : 32|1@1+ (1,0) [0|1] "" Vector__XXX
 SG_ UMC_a034_v2lSAUnsupported : 33|1@1+ (1,0) [0|1] "" Vector__XXX
 SG_ UMC_a035_v2lHVACDetected : 34|1@1+ (1,0) [0|1] "" Vector__XXX
 SG_ UMC_a037_GFCICalibration : 36|1@1+ (1,0) [0|1] "" Vector__XXX
 SG_ UMC_a038_chcVitalsFault : 37|1@1+ (1,0) [0|1] "" Vector__XXX
 SG_ UMC_a039_inputOverCurrent : 38|1@1+ (1,0) [0|1] "" Vector__XXX
 SG_ UMC_a040_gndDisconnected : 39|1@1+ (1,0) [0|1] "" Vector__XXX

BO_ 1285 UMC_smartAdapterInfo: 8 UMC
 SG_ SA_infoIndex M : 0|8@1+ (1,0) [0|255] "" Vector__XXX
 SG_ SA_genealogyVersion m0 : 8|8@1+ (1,0) [0|255] "" Vector__XXX
 SG_ SA_genealogyCrc m0 : 16|32@1+ (1,0) [0|4294967295] "" Vector__XXX
 SG_ SA_region m0 : 48|4@1+ (1,0) [0|15] "" Vector__XXX
 SG_ SA_OverTempThreshold m0 : 56|8@1+ (1,0) [0|255] "" Vector__XXX
 SG_ SA_partNumInt m31 : 8|32@1+ (1,0) [0|4294967295] "" Vector__XXX
 SG_ SA_partNumRev m31 : 40|8@1+ (1,0) [0|255] "" Vector__XXX
 SG_ SA_currentLimit m31 : 48|8@1+ (1,0) [0|255] "" Vector__XXX
 SG_ SA_l1Voltage m31 : 56|8@1+ (1,0) [0|255] "" Vector__XXX

BO_ 609 VCFRONT_12VBatteryStatus: 8 VCFRONT
 SG_ VCFRONT_12VBatteryStatusIndex M : 0|3@1+ (1,0) [0|7] "" Vector__XXX
 SG_ VCFRONT_good12VforUpdate : 46|1@1+ (1,0) [0|1] "" Vector__XXX
 SG_ VCFRONT_LVLoadRequest : 47|1@1+ (1,0) [0|1] "" Vector__XXX
 SG_ VCFRONT_12VBatteryStatusCounter : 52|4@1+ (1,0) [0|15] "" Vector__XXX
 SG_ VCFRONT_12VBatteryStatusChecksum : 56|8@1+ (1,0) [0|255] "" Vector__XXX
 SG_ VCFRONT_batterySupportRequest m1 : 3|1@1+ (1,0) [0|1] "" Vector__XXX
 SG_ VCFRONT_batterySMState m1 : 4|4@1+ (1,0) [0|15] "" Vector__XXX
 SG_ VCFRONT_eFuseRecoveryStateDBG m1 : 8|3@1+ (1,0) [0|7] "" Vector__XXX
 SG_ VCFRONT_batteryLINScheduleDBG m1 : 11|3@1+ (1,0) [0|6] "" Vector__XXX
 SG_ VCFRONT_resistanceEstimationTest m1 : 14|2@1+ (1,0) [0|3] "" Vector__XXX
 SG_ VCFRONT_IBSCurrent m1 : 16|16@1- (0.005,0) [-163.84|163.835] "A" Vector__XXX
 SG_ VCFRONT_IBSVoltage m1 : 32|14@1+ (0.005443676,0) [0|65.535] "V" Vector__XXX
 SG_ VCFRONT_reverseBatteryFault m1 : 48|1@1+ (1,0) [0|1] "" Vector__XXX
 SG_ VCFRONT_LVBatterySupported m1 : 49|1@1+ (1,0) [0|1] "" Vector__XXX
 SG_ VCFRONT_LVBatteryCannotSupportVe m1 : 50|1@1+ (1,0) [0|1] "" Vector__XXX
 SG_ VCFRONT_goodTemp12VforUpdate m1 : 51|1@1+ (1,0) [0|1] "" Vector__XXX
 SG_ VCFRONT_12VBatteryTargetVoltage m2 : 3|13@1+ (0.01,0) [0|65.535] "V" Vector__XXX
 SG_ VCFRONT_IBSTemperature m2 : 16|11@1+ (0.1,-24) [-24|124] "degC" Vector__XXX
 SG_ VCFRONT_currentSensorMismatchLea m2 : 27|7@1+ (2,0) [0|254] "PCT" Vector__XXX
 SG_ VCFRONT_LVBatteryEnergyRemaining m2 : 37|7@1+ (1,0) [0|127] "%" Vector__XXX
 SG_ VCFRONT_LVBatteryStatusForDrive m2 : 44|2@1+ (1,0) [0|3] "" Vector__XXX
 SG_ VCFRONT_LVBatteryType m2 : 48|3@1+ (1,0) [0|7] "" Vector__XXX
 SG_ VCFRONT_resistanceEstimationNeed m2 : 51|1@1+ (1,0) [0|1] "" Vector__XXX
 SG_ VCFRONT_IBSVoltageFiltered m3 : 3|14@1+ (0.005443676,0) [0|65.535] "V" Vector__XXX
 SG_ VCFRONT_LVBMS_LVBusVoltageSource m3 : 17|2@1+ (1,0) [0|3] "" Vector__XXX
 SG_ VCFRONT_LVBMS_LVPackCurrentSourc m3 : 19|2@1+ (1,0) [0|3] "" Vector__XXX
 SG_ VCFRONT_LVBatterySupportRqrdTrig m3 : 24|14@1+ (1,0) [0|16383] "" Vector__XXX
 SG_ VCFRONT_goodForPCSPowerCycleLeak m3 : 40|5@1+ (0.0005,0) [0|0.0155] "Ah" Vector__XXX
 SG_ VCFRONT_LVBusControlsFutile m3 : 45|1@1+ (1,0) [0|1] "" Vector__XXX
 SG_ VCFRONT_resistanceEstimatio_0001 m3 : 48|1@1+ (1,0) [0|1] "" Vector__XXX
 SG_ VCFRONT_resistanceEstimatio_0002 m3 : 49|1@1+ (1,0) [0|1] "" Vector__XXX
 SG_ VCFRONT_goodLVChargeForUpdate m3 : 50|1@1+ (1,0) [0|1] "" Vector__XXX
 SG_ VCFRONT_opportunisticDCRTestNeed m3 : 51|1@1+ (1,0) [0|1] "" Vector__XXX
 SG_ VCFRONT_voltageProfile m4 : 3|2@1+ (1,0) [0|3] "" Vector__XXX
 SG_ VCFRONT_IBSAmpHours m4 : 5|14@1- (0.005,0) [-40.96|40.955] "Ah" Vector__XXX
 SG_ VCFRONT_IBSVoltageRawDBG m4 : 19|14@1+ (0.005443676,0) [0|65.535] "V" Vector__XXX
 SG_ VCFRONT_LVBatteryLINCommsDetecte m4 : 33|1@1+ (1,0) [0|1] "" Vector__XXX
 SG_ VCFRONT_voltageSensorMismatchLea m4 : 34|7@1+ (2,0) [0|254] "PCT" Vector__XXX
 SG_ VCFRONT_LVBatteryFctryLimOverrid m4 : 50|1@1+ (1,0) [0|1] "" Vector__XXX
 SG_ VCFRONT_LVBatterySPICommsDetecte m4 : 51|1@1+ (1,0) [0|1] "" Vector__XXX
 SG_ VCFRONT_targetCurrent m5 : 3|11@1+ (0.125,-127) [0|120] "A" Vector__XXX
 SG_ VCFRONT_PCSMia m5 : 14|1@1+ (1,0) [0|1] "" Vector__XXX
 SG_ VCFRONT_chargeNeeded m5 : 15|1@1+ (1,0) [0|1] "" Vector__XXX
 SG_ VCFRONT_voltageControlLoopIntegr m5 : 16|14@1+ (0.006,0) [0|65.535] "V" Vector__XXX
 SG_ VCFRONT_currentControlLoopIntegr m5 : 30|14@1+ (0.006,0) [0|65.535] "V" Vector__XXX

BO_ 1847 VCFRONT_LVBMS_info: 7 VCFRONT
 SG_ VCFRONT_LVBMS_InfoIndex M : 0|8@1+ (1,0) [0|255] "" Vector__XXX
 SG_ VCFRONT_LVBMS_PcbaId m0 : 8|16@1+ (1,0) [0|65535] "" Vector__XXX
 SG_ VCFRONT_LVBMS_AssemblyId m0 : 24|16@1+ (1,0) [0|65535] "" Vector__XXX
 SG_ VCFRONT_LVBMS_SubUsageId m0 : 40|16@1+ (1,0) [0|65534] "" Vector__XXX
 SG_ VCFRONT_LVBMS_UsageId m1 : 8|16@1+ (1,0) [0|65535] "" Vector__XXX
 SG_ VCFRONT_LVBMS_AppCRC m1 : 24|32@1+ (1,0) [0|4294967295] "" Vector__XXX
 SG_ VCFRONT_LVBMS_FWBuildType m3 : 8|8@1+ (1,0) [0|255] "" Vector__XXX

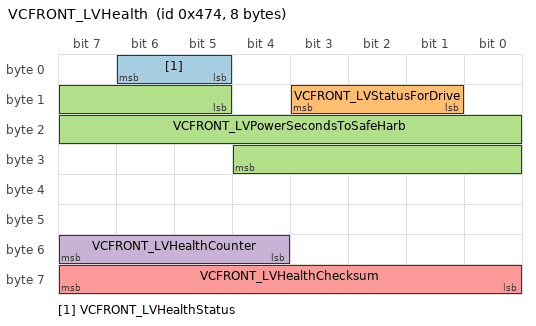
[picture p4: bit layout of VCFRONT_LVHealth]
BO_ 1140 VCFRONT_LVHealth: 8 VCFRONT
 SG_ VCFRONT_LVHealthStatus : 5|2@1+ (1,0) [0|3] "" Vector__XXX
 SG_ VCFRONT_LVStatusForDrive : 9|3@1+ (1,0) [0|7] "" Vector__XXX
 SG_ VCFRONT_LVPowerSecondsToSafeHarb : 13|16@1+ (1,0) [0|65535] "" Vector__XXX
 SG_ VCFRONT_LVHealthCounter : 52|4@1+ (1,0) [0|15] "" Vector__XXX
 SG_ VCFRONT_LVHealthChecksum : 56|8@1+ (1,0) [0|255] "" Vector__XXX

BO_ 1173 VCFRONT_LVHealthDebug: 6 VCFRONT
 SG_ VCFRONT_LVHealthDebugIndex M : 0|4@1+ (1,0) [0|15] "" Vector__XXX
 SG_ VCFRONT_LVHEALTH_placeholder m0 : 8|1@1+ (1,0) [0|1] "" Vector__XXX
 SG_ VCFRONT_LVHEALTH_activeDecelEner m0 : 9|1@1+ (1,0) [0|1] "" Vector__XXX
 SG_ VCFRONT_LVHEALTH_criticalPullove m0 : 10|1@1+ (1,0) [0|1] "" Vector__XXX
 SG_ VCFRONT_LVHEALTH_revBattEFuseOff m0 : 11|1@1+ (1,0) [0|1] "" Vector__XXX
 SG_ VCFRONT_LVHEALTH_LVBMBEFuseOpen m0 : 12|1@1+ (1,0) [0|1] "" Vector__XXX
 SG_ VCFRONT_LVHEALTH_lvBatteryCommsM m0 : 13|1@1+ (1,0) [0|1] "" Vector__XXX
 SG_ VCFRONT_LVHEALTH_pcsEFuseOff m0 : 14|1@1+ (1,0) [0|1] "" Vector__XXX
 SG_ VCFRONT_LVHEALTH_pcsNotActive m0 : 15|1@1+ (1,0) [0|1] "" Vector__XXX
 SG_ VCFRONT_LVHEALTH_pcsMIA m0 : 16|1@1+ (1,0) [0|1] "" Vector__XXX
 SG_ VCFRONT_LVHEALTH_IBSMIA m0 : 17|1@1+ (1,0) [0|1] "" Vector__XXX
 SG_ VCFRONT_LVHEALTH_LVBatteryElecDi m0 : 18|1@1+ (1,0) [0|1] "" Vector__XXX
 SG_ VCFRONT_LVHEALTH_LVBatteryE_0001 m0 : 19|1@1+ (1,0) [0|1] "" Vector__XXX
 SG_ VCFRONT_LVHEALTH_pcsOpenCircuit m0 : 20|1@1+ (1,0) [0|1] "" Vector__XXX
 SG_ VCFRONT_LVHEALTH_activeDecelPowe m0 : 21|1@1+ (1,0) [0|1] "" Vector__XXX
 SG_ VCFRONT_LVHEALTH_lvBatteryCapabi m0 : 22|1@1+ (1,0) [0|1] "" Vector__XXX
 SG_ VCFRONT_LVHEALTH_lvBatteryConfig m0 : 23|1@1+ (1,0) [0|1] "" Vector__XXX
 SG_ VCFRONT_LVHEALTH_lvBatteryImpeda m0 : 24|1@1+ (1,0) [0|1] "" Vector__XXX

BO_ 545 VCFRONT_LVPowerState: 8 VCFRONT
 SG_ VCFRONT_LVPowerStateIndex M : 0|5@1+ (1,0) [0|31] "" Vector__XXX
 SG_ VCFRONT_vehiclePowerState : 5|2@1+ (1,0) [0|3] "" Vector__XXX
 SG_ VCFRONT_inAccessoryPlus : 50|1@1+ (1,0) [0|1] "" Vector__XXX
 SG_ VCFRONT_LVShuttingDown : 51|1@1+ (1,0) [0|1] "" Vector__XXX
 SG_ VCFRONT_LVPowerStateCounter : 52|4@1+ (1,0) [0|15] "" Vector__XXX
 SG_ VCFRONT_LVPowerStateChecksum : 56|8@1+ (1,0) [0|255] "" Vector__XXX
 SG_ VCFRONT_cpLVRequest m1 : 8|2@1+ (1,0) [0|3] "" Vector__XXX
 SG_ VCFRONT_epasLVState m1 : 10|2@1+ (1,0) [0|3] "" Vector__XXX
 SG_ VCFRONT_hvcLVRequest m1 : 12|2@1+ (1,0) [0|3] "" Vector__XXX
 SG_ VCFRONT_tasLVState m1 : 14|2@1+ (1,0) [0|3] "" Vector__XXX
 SG_ VCFRONT_pcsLVState m1 : 16|2@1+ (1,0) [0|3] "" Vector__XXX
 SG_ VCFRONT_CMPDLVState m1 : 18|2@1+ (1,0) [0|3] "" Vector__XXX
 SG_ VCFRONT_hcmlLVState m1 : 20|2@1+ (1,0) [0|3] "" Vector__XXX
 SG_ VCFRONT_hcmrLVState m1 : 22|2@1+ (1,0) [0|3] "" Vector__XXX
 SG_ VCFRONT_MCUAudioLVState m1 : 24|2@1+ (1,0) [0|3] "" Vector__XXX
 SG_ VCFRONT_espValveLVState m1 : 26|2@1+ (1,0) [0|3] "" Vector__XXX
 SG_ VCFRONT_MCUGraphicsLVState m1 : 28|2@1+ (1,0) [0|3] "" Vector__XXX
 SG_ VC_dcdcSupportRequest m1 : 30|1@1+ (1,0) [0|1] "" Vector__XXX
 SG_ VC_hvStateRequest m1 : 31|3@1+ (1,0) [0|7] "" Vector__XXX
 SG_ VC_persistAccPowerRequestOverrid m1 : 39|1@1+ (1,0) [0|1] "" Vector__XXX
 SG_ VC_accPortPowerRequest m1 : 40|1@1+ (1,0) [0|1] "" Vector__XXX
 SG_ VC_persistAccPortPowerState m1 : 41|3@1+ (1,0) [0|7] "" Vector__XXX

BO_ 700 VCFRONT_LVThermalMotors10Hz: 8 VCFRONT
 SG_ VCFRONT_LVThermalMotorsIndex M : 0|4@1+ (1,0) [0|15] "" Vector__XXX
 SG_ VCFRONT_radiatorFanState m0 : 4|3@1+ (1,0) [0|7] "" Vector__XXX
 SG_ VCFRONT_radiatorFanTorque m0 : 8|10@1+ (0.006,-1.5) [-1.5|4.5] "Nm" Vector__XXX
 SG_ VCFRONT_radiatorFanIDc m0 : 24|7@1+ (0.5,0) [0|63] "A" Vector__XXX
 SG_ VCFRONT_mlxLINCurrentSchedule m0 : 32|2@1+ (1,0) [0|3] "" Vector__XXX
 SG_ VCFRONT_pumpPowertrainState m3 : 4|3@1+ (1,0) [0|7] "" Vector__XXX
 SG_ VCFRONT_pumpPowertrainTorque m3 : 8|10@1+ (0.006,-1.5) [-1.5|4.5] "Nm" Vector__XXX
 SG_ VCFRONT_pumpPowertrainIDc m3 : 24|7@1+ (0.5,0) [0|63] "A" Vector__XXX
 SG_ VCFRONT_pumpBatteryState m6 : 4|3@1+ (1,0) [0|7] "" Vector__XXX
 SG_ VCFRONT_pumpBatteryTorque m6 : 8|10@1+ (0.006,-1.5) [-1.5|4.5] "Nm" Vector__XXX
 SG_ VCFRONT_pumpBatteryIDc m6 : 24|7@1+ (0.5,0) [0|63] "A" Vector__XXX

BO_ 1332 VCFRONT_alertLog: 8 VCFRONT
 SG_ VCFRONT_alertID M : 0|10@1+ (1,0) [0|1023] "" Vector__XXX
 SG_ VCFRONT_alertState : 15|1@1+ (1,0) [0|1] "" Vector__XXX
 SG_ VCFRONT_a001_InternalWatchdog m1 : 16|1@1+ (1,0) [0|1] "" Vector__XXX
 SG_ VCFRONT_a002_CPUUndervoltage m2 : 16|1@1+ (1,0) [0|1] "" Vector__XXX
 SG_ VCFRONT_a002_PowerOnReset m2 : 17|1@1+ (1,0) [0|1] "" Vector__XXX
 SG_ VCFRONT_a004_APPWatchdogFaultOrM m4 : 16|1@1+ (1,0) [0|1] "" Vector__XXX
 SG_ VCFRONT_a004_DASHighLowBeamDecis m4 : 17|1@1+ (1,0) [0|1] "" Vector__XXX
 SG_ VCFRONT_a004_DASAdaptiveHighBeam m4 : 18|1@1+ (1,0) [0|1] "" Vector__XXX
 SG_ VCFRONT_a004_DASMatrixColumnMsgM m4 : 19|1@1+ (1,0) [0|1] "" Vector__XXX
 SG_ VCFRONT_a004_DASBendAngleMsgMIA m4 : 20|1@1+ (1,0) [0|1] "" Vector__XXX
 SG_ VCFRONT_a004_EPAS3PNotInSpecOrMI m4 : 21|1@1+ (1,0) [0|1] "" Vector__XXX
 SG_ VCFRONT_a008_APPWatchdogFaultOrM m8 : 16|1@1+ (1,0) [0|1] "" Vector__XXX
 SG_ VCFRONT_a008_DASHighLowBeamDecis m8 : 17|1@1+ (1,0) [0|1] "" Vector__XXX
 SG_ VCFRONT_a008_DASAdaptiveHighBeam m8 : 18|1@1+ (1,0) [0|1] "" Vector__XXX
 SG_ VCFRONT_a008_DASMatrixColumnMsgM m8 : 19|1@1+ (1,0) [0|1] "" Vector__XXX
 SG_ VCFRONT_a008_DASBendAngleMsgMIA m8 : 20|1@1+ (1,0) [0|1] "" Vector__XXX
 SG_ VCFRONT_a008_EPAS3PNotInSpecOrMI m8 : 21|1@1+ (1,0) [0|1] "" Vector__XXX
 SG_ VCFRONT_a010_UnderVoltageDetecte m10 : 16|1@1+ (1,0) [0|1] "" Vector__XXX
 SG_ VCFRONT_a010_UnderVoltageTimeout m10 : 17|1@1+ (1,0) [0|1] "" Vector__XXX
 SG_ VCFRONT_a015_NVMMMemOverflow m15 : 16|1@1+ (1,0) [0|1] "" Vector__XXX
 SG_ VCFRONT_a015_NVMMFilesystemError m15 : 17|1@1+ (1,0) [0|1] "" Vector__XXX
 SG_ VCFRONT_a015_NVMMRecordIDError m15 : 18|1@1+ (1,0) [0|1] "" Vector__XXX
 SG_ VCFRONT_a057_VEH_cpControl m57 : 16|1@1+ (1,0) [0|1] "" Vector__XXX
 SG_ VCFRONT_a059_voltageDrop m59 : 16|12@1+ (0.005443676,0) [0|22.29185322] "V" Vector__XXX
 SG_ VCFRONT_a059_resistanceEstimate m59 : 28|12@1+ (0.00244,0) [0|9.9918] "Ohms" Vector__XXX
 SG_ VCFRONT_a059_current m59 : 40|12@1+ (0.05,0) [0|204.75] "A" Vector__XXX
 SG_ VCFRONT_a063_switchChannel m63 : 16|8@1+ (1,0) [0|255] "" Vector__XXX
 SG_ VCFRONT_a063_switchType m63 : 24|8@1+ (1,0) [0|255] "" Vector__XXX
 SG_ VCFRONT_a063_ADCVoltage m63 : 32|8@1+ (0.025,0) [0|6.375] "V" Vector__XXX
 SG_ VCFRONT_a063_disconnected m63 : 40|1@1+ (1,0) [0|1] "" Vector__XXX
 SG_ VCFRONT_a063_indeterminate m63 : 41|1@1+ (1,0) [0|1] "" Vector__XXX
 SG_ VCFRONT_a063_stuckActive m63 : 42|1@1+ (1,0) [0|1] "" Vector__XXX
 SG_ VCFRONT_a063_faulted m63 : 43|1@1+ (1,0) [0|1] "" Vector__XXX
 SG_ VCFRONT_a082_RIPC_epbPrivateStat m82 : 16|1@1+ (1,0) [0|1] "" Vector__XXX
 SG_ VCFRONT_a082_RIPC_remoteHSD m82 : 17|1@1+ (1,0) [0|1] "" Vector__XXX
 SG_ VCFRONT_a082_RIPC_railStatus m82 : 18|1@1+ (1,0) [0|1] "" Vector__XXX
 SG_ VCFRONT_a082_RIPC_remoteMux m82 : 19|1@1+ (1,0) [0|1] "" Vector__XXX
 SG_ VCFRONT_a083_LIPC_epbPrivateStat m83 : 16|1@1+ (1,0) [0|1] "" Vector__XXX
 SG_ VCFRONT_a083_LIPC_remoteHSD m83 : 17|1@1+ (1,0) [0|1] "" Vector__XXX
 SG_ VCFRONT_a083_LIPC_railStatus m83 : 18|1@1+ (1,0) [0|1] "" Vector__XXX
 SG_ VCFRONT_a083_LIPC_HSDFaults m83 : 19|1@1+ (1,0) [0|1] "" Vector__XXX
 SG_ VCFRONT_a084_CH_StatusC m84 : 16|1@1+ (1,0) [0|1] "" Vector__XXX
 SG_ VCFRONT_a085_PARTY_buttonStatus m85 : 16|1@1+ (1,0) [0|1] "" Vector__XXX
 SG_ VCFRONT_a086_VEH_LVBMS_statusHig m86 : 16|1@1+ (1,0) [0|1] "" Vector__XXX
 SG_ VCFRONT_a086_VEH_LVBMS_statusLow m86 : 17|1@1+ (1,0) [0|1] "" Vector__XXX
 SG_ VCFRONT_a086_VEH_status m86 : 18|1@1+ (1,0) [0|1] "" Vector__XXX
 SG_ VCFRONT_a086_VEH_12VBatteryStatu m86 : 19|1@1+ (1,0) [0|1] "" Vector__XXX
 SG_ VCFRONT_a086_VEH_LVPowerState m86 : 20|1@1+ (1,0) [0|1] "" Vector__XXX
 SG_ VCFRONT_a086_VEH_lightStatus m86 : 21|1@1+ (1,0) [0|1] "" Vector__XXX
 SG_ VCFRONT_a086_VEH_systemStatus m86 : 22|1@1+ (1,0) [0|1] "" Vector__XXX
 SG_ VCFRONT_a086_VEH_thermalStatus m86 : 23|1@1+ (1,0) [0|1] "" Vector__XXX
 SG_ VCFRONT_a086_VEH_vehNm m86 : 24|1@1+ (1,0) [0|1] "" Vector__XXX
 SG_ VCFRONT_a087_VEH_temperature m87 : 16|1@1+ (1,0) [0|1] "" Vector__XXX
 SG_ VCFRONT_a087_VEH_thermalControl m87 : 17|1@1+ (1,0) [0|1] "" Vector__XXX
 SG_ VCFRONT_a087_VEH_torque m87 : 18|1@1+ (1,0) [0|1] "" Vector__XXX
 SG_ VCFRONT_a087_VEH_status m87 : 19|1@1+ (1,0) [0|1] "" Vector__XXX
 SG_ VCFRONT_a087_PARTY_torque m87 : 20|1@1+ (1,0) [0|1] "" Vector__XXX
 SG_ VCFRONT_a087_PARTY_status m87 : 21|1@1+ (1,0) [0|1] "" Vector__XXX
 SG_ VCFRONT_a087_PARTY_temperature m87 : 22|1@1+ (1,0) [0|1] "" Vector__XXX
 SG_ VCFRONT_a087_PARTY_thermalContro m87 : 23|1@1+ (1,0) [0|1] "" Vector__XXX
 SG_ VCFRONT_a088_VEH_temperature m88 : 16|1@1+ (1,0) [0|1] "" Vector__XXX
 SG_ VCFRONT_a088_VEH_thermalControl m88 : 17|1@1+ (1,0) [0|1] "" Vector__XXX
 SG_ VCFRONT_a088_VEH_torque m88 : 18|1@1+ (1,0) [0|1] "" Vector__XXX
 SG_ VCFRONT_a088_VEH_status m88 : 19|1@1+ (1,0) [0|1] "" Vector__XXX
 SG_ VCFRONT_a088_PARTY_torque m88 : 20|1@1+ (1,0) [0|1] "" Vector__XXX
 SG_ VCFRONT_a088_PARTY_status m88 : 21|1@1+ (1,0) [0|1] "" Vector__XXX
 SG_ VCFRONT_a088_PARTY_temperature m88 : 22|1@1+ (1,0) [0|1] "" Vector__XXX
 SG_ VCFRONT_a088_PARTY_thermalContro m88 : 23|1@1+ (1,0) [0|1] "" Vector__XXX
 SG_ VCFRONT_a089_PARTY_party1 m89 : 16|1@1+ (1,0) [0|1] "" Vector__XXX
 SG_ VCFRONT_a089_PARTY_status m89 : 17|1@1+ (1,0) [0|1] "" Vector__XXX
 SG_ VCFRONT_a089_VEH_status m89 : 18|1@1+ (1,0) [0|1] "" Vector__XXX
 SG_ VCFRONT_a089_BDY_party1 m89 : 19|1@1+ (1,0) [0|1] "" Vector__XXX
 SG_ VCFRONT_a089_BDY_status m89 : 20|1@1+ (1,0) [0|1] "" Vector__XXX
 SG_ VCFRONT_a089_CH_status m89 : 21|1@1+ (1,0) [0|1] "" Vector__XXX
 SG_ VCFRONT_a089_CH_party1 m89 : 22|1@1+ (1,0) [0|1] "" Vector__XXX
 SG_ VCFRONT_a089_CH_party3 m89 : 23|1@1+ (1,0) [0|1] "" Vector__XXX
 SG_ VCFRONT_a089_VEH_party1 m89 : 24|1@1+ (1,0) [0|1] "" Vector__XXX
 SG_ VCFRONT_a089_VEH_party3 m89 : 25|1@1+ (1,0) [0|1] "" Vector__XXX
 SG_ VCFRONT_a091_VEH_faultsAndExtras m91 : 16|1@1+ (1,0) [0|1] "" Vector__XXX
 SG_ VCFRONT_a091_VEH_info m91 : 17|1@1+ (1,0) [0|1] "" Vector__XXX
 SG_ VCFRONT_a091_VEH_state m91 : 18|1@1+ (1,0) [0|1] "" Vector__XXX

BO_TX_BU_ 1523 : GTW;
BO_TX_BU_ 948 : GTW;
BO_TX_BU_ 955 : GTW;
BO_TX_BU_ 827 : GTW;
BO_TX_BU_ 661 : GTW;
BO_TX_BU_ 820 : GTW;
BO_TX_BU_ 826 : GTW;
BO_TX_BU_ 723 : GTW;
BO_TX_BU_ 851 : GTW;
BO_TX_BU_ 991 : GTW;
BO_TX_BU_ 663 : GTW;
BO_TX_BU_ 956 : GTW;
BO_TX_BU_ 787 : GTW;
BO_TX_BU_ 839 : GTW;
BO_TX_BU_ 627 : GTW;
BO_TX_BU_ 947 : GTW;
BO_TX_BU_ 660 : GTW;
BO_TX_BU_ 853 : GTW;
BO_TX_BU_ 644 : GTW;
BO_TX_BU_ 595 : GTW;
BO_TX_BU_ 1565 : GTW;
BO_TX_BU_ 1533 : UMC;
BO_TX_BU_ 824 : UMC;
BO_TX_BU_ 1285 : UMC;
BO_TX_BU_ 609 : VCFRONT;
BO_TX_BU_ 1847 : VCFRONT;
BO_TX_BU_ 1140 : VCFRONT;
BO_TX_BU_ 1173 : VCFRONT;
BO_TX_BU_ 545 : VCFRONT;
BO_TX_BU_ 700 : VCFRONT;
BO_TX_BU_ 1332 : VCFRONT;
CM_ BO_ 1523 "Touchscreen user interface computer message: odo; forwarded onto this bus by the gateway";
CM_ SG_ 1523 UI_odometer "Odometer; raw 16777215 = signal not available (SNA)";
CM_ BO_ 948 "Touchscreen user interface computer message: peripheral power requests; forwarded onto this bus by the gateway";
CM_ SG_ 948 UI_usbFrontHubPowerStateRequest "Reports the Universal Serial Bus (USB) Hub power request.; raw 0 = signal not available (SNA)";
CM_ BO_ 955 "Touchscreen user interface computer message: power; forwarded onto this bus by the gateway";
CM_ SG_ 955 UI_powerExpected "Touchscreen user interface computer: power expected";
CM_ SG_ 955 UI_powerIdeal "Touchscreen user interface computer: power ideal";
CM_ BO_ 827 "Touchscreen user interface computer message: power estimates; forwarded onto this bus by the gateway";
CM_ SG_ 827 UI_idlePowerConsumption "Power consumption when idle";
CM_ SG_ 827 UI_chargeTimeUntilTerminationPct "Charge time minutes until reached uSoe target; raw 2047 = signal not available (SNA)";
CM_ SG_ 827 UI_isTripChargingActive "Touchscreen user interface computer: is trip charging active";
CM_ SG_ 827 UI_chargeTimeUntilReadyToDepart "Charge time minutes until enough energy to depart for rest of trip; raw 2047 = signal not available (SNA)";
CM_ BO_ 661 "Touchscreen user interface computer message: power rationality config; forwarded onto this bus by the gateway";
CM_ SG_ 661 UI_powerRationalityConfigIndex "Touchscreen user interface computer: power rationality config index";
CM_ SG_ 661 UI_vcleftCfgRationalityThreshold "Touchscreen user interface computer: vcleft cfg rationality threshold0; raw 0 = signal not available (SNA)";
CM_ SG_ 661 UI_vcleftCfgRationalityTime0 "Touchscreen user interface computer: vcleft cfg rationality time0; raw 0 = signal not available (SNA)";
CM_ SG_ 661 UI_vcleftCfgRationalityThre_0001 "Touchscreen user interface computer: vcleft cfg rationality threshold1; raw 0 = signal not available (SNA)";
CM_ SG_ 661 UI_vcleftCfgRationalityTime1 "Touchscreen user interface computer: vcleft cfg rationality time1; raw 0 = signal not available (SNA)";
CM_ SG_ 661 UI_vcleftCfgRationalityStaticA "Touchscreen user interface computer: vcleft cfg rationality static a; raw 65535 = signal not available (SNA)";
CM_ SG_ 661 UI_vcleftCfgRationalityStaticB "Touchscreen user interface computer: vcleft cfg rationality static b; raw 32768 = signal not available (SNA)";
CM_ SG_ 661 UI_vcleftCfgRationalityStaticC "Touchscreen user interface computer: vcleft cfg rationality static c; raw 32768 = signal not available (SNA)";
CM_ SG_ 661 UI_vcleftCfgRationalityDynamicA "Touchscreen user interface computer: vcleft cfg rationality dynamic a; raw 65535 = signal not available (SNA)";
CM_ SG_ 661 UI_vcleftCfgRationalityDynamicB "Touchscreen user interface computer: vcleft cfg rationality dynamic b; raw 32768 = signal not available (SNA)";
CM_ SG_ 661 UI_vcleftCfgRationalityDynamicC "Touchscreen user interface computer: vcleft cfg rationality dynamic c; raw 32768 = signal not available (SNA)";
CM_ SG_ 661 UI_vcrightCfgRationalityThreshol "Touchscreen user interface computer: vcright cfg rationality threshold0; raw 0 = signal not available (SNA)";
CM_ SG_ 661 UI_vcrightCfgRationalityTime0 "Touchscreen user interface computer: vcright cfg rationality time0; raw 0 = signal not available (SNA)";
CM_ SG_ 661 UI_vcrightCfgRationalityThr_0001 "Touchscreen user interface computer: vcright cfg rationality threshold1; raw 0 = signal not available (SNA)";
CM_ SG_ 661 UI_vcrightCfgRationalityTime1 "Touchscreen user interface computer: vcright cfg rationality time1; raw 0 = signal not available (SNA)";
CM_ SG_ 661 UI_vcrightCfgRationalityStaticA "Touchscreen user interface computer: vcright cfg rationality static a; raw 65535 = signal not available (SNA)";
CM_ SG_ 661 UI_vcrightCfgRationalityStaticB "Touchscreen user interface computer: vcright cfg rationality static b; raw 32768 = signal not available (SNA)";
CM_ SG_ 661 UI_vcrightCfgRationalityStaticC "Touchscreen user interface computer: vcright cfg rationality static c; raw 32768 = signal not available (SNA)";
CM_ SG_ 661 UI_vcrightCfgRationalityDynamicA "Touchscreen user interface computer: vcright cfg rationality dynamic a; raw 65535 = signal not available (SNA)";
CM_ SG_ 661 UI_vcrightCfgRationalityDynamicB "Touchscreen user interface computer: vcright cfg rationality dynamic b; raw 32768 = signal not available (SNA)";
CM_ SG_ 661 UI_vcrightCfgRationalityDynamicC "Touchscreen user interface computer: vcright cfg rationality dynamic c; raw 32768 = signal not available (SNA)";
CM_ SG_ 661 UI_vcleftCfgCutoffThreshold0 "Touchscreen user interface computer: vcleft cfg cutoff threshold0; raw 0 = signal not available (SNA)";
CM_ SG_ 661 UI_vcleftCfgCutoffTime0 "Touchscreen user interface computer: vcleft cfg cutoff time0; raw 0 = signal not available (SNA)";
CM_ SG_ 661 UI_vcleftCfgCutoffThreshold1 "Touchscreen user interface computer: vcleft cfg cutoff threshold1; raw 0 = signal not available (SNA)";
CM_ SG_ 661 UI_vcleftCfgCutoffTime1 "Touchscreen user interface computer: vcleft cfg cutoff time1; raw 0 = signal not available (SNA)";
CM_ SG_ 661 UI_vcleftCfgCutoffStaticA "Touchscreen user interface computer: vcleft cfg cutoff static a; raw 65535 = signal not available (SNA)";
CM_ SG_ 661 UI_vcleftCfgCutoffStaticB "Touchscreen user interface computer: vcleft cfg cutoff static b; raw 32768 = signal not available (SNA)";
CM_ SG_ 661 UI_vcleftCfgCutoffStaticC "Touchscreen user interface computer: vcleft cfg cutoff static c; raw 32768 = signal not available (SNA)";
CM_ SG_ 661 UI_vcleftCfgCutoffDynamicA "Touchscreen user interface computer: vcleft cfg cutoff dynamic a; raw 65535 = signal not available (SNA)";
CM_ SG_ 661 UI_vcleftCfgCutoffDynamicB "Touchscreen user interface computer: vcleft cfg cutoff dynamic b; raw 32768 = signal not available (SNA)";
CM_ SG_ 661 UI_vcleftCfgCutoffDynamicC "Touchscreen user interface computer: vcleft cfg cutoff dynamic c; raw 32768 = signal not available (SNA)";
CM_ SG_ 661 UI_vcrightCfgCutoffThreshold0 "Touchscreen user interface computer: vcright cfg cutoff threshold0; raw 0 = signal not available (SNA)";
CM_ SG_ 661 UI_vcrightCfgCutoffTime0 "Touchscreen user interface computer: vcright cfg cutoff time0; raw 0 = signal not available (SNA)";
CM_ SG_ 661 UI_vcrightCfgCutoffThreshold1 "Touchscreen user interface computer: vcright cfg cutoff threshold1; raw 0 = signal not available (SNA)";
CM_ SG_ 661 UI_vcrightCfgCutoffTime1 "Touchscreen user interface computer: vcright cfg cutoff time1; raw 0 = signal not available (SNA)";
CM_ SG_ 661 UI_vcrightCfgCutoffStaticA "Touchscreen user interface computer: vcright cfg cutoff static a; raw 65535 = signal not available (SNA)";
CM_ SG_ 661 UI_vcrightCfgCutoffStaticB "Touchscreen user interface computer: vcright cfg cutoff static b; raw 32768 = signal not available (SNA)";
CM_ SG_ 661 UI_vcrightCfgCutoffStaticC "Touchscreen user interface computer: vcright cfg cutoff static c; raw 32768 = signal not available (SNA)";
CM_ SG_ 661 UI_vcrightCfgCutoffDynamicA "Touchscreen user interface computer: vcright cfg cutoff dynamic a; raw 65535 = signal not available (SNA)";
CM_ SG_ 661 UI_vcrightCfgCutoffDynamicB "Touchscreen user interface computer: vcright cfg cutoff dynamic b; raw 32768 = signal not available (SNA)";
CM_ SG_ 661 UI_vcrightCfgCutoffDynamicC "Touchscreen user interface computer: vcright cfg cutoff dynamic c; raw 32768 = signal not available (SNA)";
CM_ BO_ 820 "Touchscreen user interface computer message: powertrain control; forwarded onto this bus by the gateway";
CM_ SG_ 820 UI_systemPowerLimit "Touchscreen user interface computer: system power limit; raw 31 = signal not available (SNA)";
CM_ SG_ 820 UI_pedalMap "Switch between various platform specific pedal maps";
CM_ SG_ 820 UI_enableRegenBackfill "Indicates if regenerative braking backfill has been enabled by the driver";
CM_ SG_ 820 UI_systemTorqueLimit "Touchscreen user interface computer: system torque limit; raw 63 = signal not available (SNA)";
CM_ SG_ 820 UI_closureConfirmed "Touchscreen user interface computer: closure confirmed";
CM_ SG_ 820 UI_regenTorqueMax "Maximum regen torque from UI - reports different value when in track mode";
CM_ SG_ 820 UI_limitMode "Commands limited drive inverter capabilities based on special vehicle modes";
CM_ SG_ 820 UI_factoryCustomerDrivingModeReq "Touchscreen user interface computer: factory customer driving mode request";
CM_ SG_ 820 UI_motorOnMode "Request from the UI to selectively enable or disable a drive unit (dev-only)";
CM_ SG_ 820 UI_wasteMode "Touchscreen user interface computer: waste mode";
CM_ SG_ 820 UI_wasteModeRegenLimit "Touchscreen user interface computer: waste mode regen limit";
CM_ SG_ 820 UI_stoppingMode "Low-speed behavior when no pedal is pressed (stopping/rolling/creeping)";
CM_ SG_ 820 UI_DIAppSliderDebug "Touchscreen user interface computer: DI app slider debug";
CM_ SG_ 820 UI_speedLimit "Maximum allowed speed enforced at vehicle level.; raw 511 = signal not available (SNA)";
CM_ SG_ 820 UI_enableSmartShift "Stalkless convenience feature that allows unparking with only a firm press of brake pedal";
CM_ SG_ 820 UI_navVehParallelToRdCanContinue "Whether the vehicle is parallel parked on a public road; raw 0 = signal not available (SNA)";
CM_ SG_ 820 UI_powertrainControlCounter "Touchscreen user interface computer: powertrain control counter";
CM_ SG_ 820 UI_powertrainControlChecksum "Touchscreen user interface computer: powertrain control checksum";
CM_ BO_ 826 "Touchscreen user interface computer message: range; forwarded onto this bus by the gateway";
CM_ SG_ 826 UI_ratedRange "Rated range in miles";
CM_ SG_ 826 UI_whpm "Touchscreen user interface computer: whpm";
CM_ SG_ 826 UI_soe "State of energy";
CM_ SG_ 826 UI_uSoe "Usable state of energy";
CM_ SG_ 826 UI_softPackLimitPct "Touchscreen user interface computer: soft pack limit pct";
CM_ SG_ 826 UI_targetFullPackEnergy "Touchscreen user interface computer: target full pack energy";
CM_ BO_ 723 "Touchscreen user interface computer message: solar data; forwarded onto this bus by the gateway";
CM_ SG_ 723 UI_solarAzimuthAngle "Touchscreen user interface computer: solar azimuth angle; raw 32768 = signal not available (SNA)";
CM_ SG_ 723 UI_solarAzimuthAngleCarRef "Touchscreen user interface computer: solar azimuth angle car ref; raw 255 = signal not available (SNA)";
CM_ SG_ 723 UI_isSunUp "is sun up; raw 3 = signal not available (SNA)";
CM_ SG_ 723 UI_solarElevationAngle "Solar Elevation Angle; raw 127 = signal not available (SNA)";
CM_ SG_ 723 UI_screenPCBTemperature "Temperature of display PCB";
CM_ SG_ 723 UI_minsToSunset "time until to sunset";
CM_ SG_ 723 UI_minsToSunrise "time until to sunrise";
CM_ BO_ 851 "Touchscreen user interface computer message: status; forwarded onto this bus by the gateway";
CM_ SG_ 851 UI_touchActive "No touchscreen errors";
CM_ SG_ 851 UI_audioActive "Audio system is ready.";
CM_ SG_ 851 UI_bluetoothActive "Touchscreen user interface computer: bluetooth active";
CM_ SG_ 851 UI_cellActive "Cell is powered";
CM_ SG_ 851 UI_displayReady "UI is ready (GUI_allReady) and display is ok (GUI_displayHardwareOK)";
CM_ SG_ 851 UI_displayOn "UI display on/off status";
CM_ SG_ 851 UI_wifiActive "WiFi active.";
CM_ SG_ 851 UI_wifiConnected "WiFi Connected.";
CM_ SG_ 851 UI_systemActive "Touchscreen user interface computer: system active";
CM_ SG_ 851 UI_readyForDrive "Ready for drive (UI ready or self park request)";
CM_ SG_ 851 UI_cellConnected "Detects if the cell is connected to a network.";
CM_ SG_ 851 UI_vpnActive "VPN connected.";
CM_ SG_ 851 UI_autopilotTrial "Touchscreen user interface computer: autopilot trial";
CM_ SG_ 851 UI_factoryReset "UI request for factory reset; raw 0 = signal not available (SNA)";
CM_ SG_ 851 UI_gpsActive "GPS has valid fix";
CM_ SG_ 851 UI_screenshotActive "Touchscreen user interface computer: screenshot active";
CM_ SG_ 851 UI_radioActive "Touchscreen user interface computer: radio active";
CM_ SG_ 851 UI_cellNetworkTechnology "Describes the type of cellular network to which the car computer is connected: GPRS_2G(114Kbps) < EGDE_2G(368Kbps) < 3G(3Mbps) < HSDPA_3G(14Mbps) < HSPAplus_4Gg(168Mbps) < 4G_LTE(299Mbps); raw 15 = signal not available (SNA)";
CM_ SG_ 851 UI_cellReceiverPower "Touchscreen user interface computer: cell receiver power";
CM_ SG_ 851 UI_falseTouchCounter "Count false touches after display is off.";
CM_ SG_ 851 UI_developmentCar "Touchscreen user interface computer: development car";
CM_ SG_ 851 UI_cameraActive "Touchscreen user interface computer: camera active";
CM_ SG_ 851 UI_cellSignalBars "Number of cellular signal bars displayed on the UI, derived from cellSignalStrength; raw 7 = signal not available (SNA)";
CM_ SG_ 851 UI_trailerModeTelltale "Color of the trailer mode telltale";
CM_ SG_ 851 UI_pcbTemperature "PCB digital temp sensor reading in DegC";
CM_ SG_ 851 UI_cpuTemperature "Apollo Lake SOC temperature in DegC";
CM_ BO_ 991 "Touchscreen user interface computer message: status2; forwarded onto this bus by the gateway";
CM_ SG_ 991 UI_mobileAppStepCount "Touchscreen user interface computer: mobile app step count";
CM_ SG_ 991 UI_userRequestSnapshot "Touchscreen user interface computer: user request snapshot";
CM_ SG_ 991 UI_touchDetected "Touchscreen user interface computer: touch detected";
CM_ SG_ 991 UI_validDeviceForEUSummon "Touchscreen user interface computer: valid device for EU summon";
CM_ SG_ 991 UI_locatedAtHome "Touchscreen user interface computer: located at home";
CM_ SG_ 991 UI_locatedAtWork "Touchscreen user interface computer: located at work";
CM_ SG_ 991 UI_locatedAtFavorite "Touchscreen user interface computer: located at favorite";
CM_ SG_ 991 UI_displayInDarkMode "Touchscreen user interface computer: display in dark mode";
CM_ SG_ 991 UI_userActivity "Indicates user interaction with the center display";
CM_ SG_ 991 UI_activeTouchPoints "Quantity of active touch points on the Center Display";
CM_ SG_ 991 UI_linkState "Connectivity link state";
CM_ SG_ 991 UI_sentryModeState "Touchscreen user interface computer: sentry mode state; raw 6 = signal not available (SNA)";
CM_ SG_ 991 UI_autopilotSentryRequest "whether AP sentry mode should be enabled";
CM_ SG_ 991 UI_mobileAppConnected "Reports if Web Real-Time Communication (WebRTC) connection is connected while summon screen is open on the mobile app.";
CM_ SG_ 991 UI_autoshiftDRState "Reports the User Interface (UI) autoshift Drive/Reverse state.";
CM_ SG_ 991 UI_wifiBtModuleType "Reports the type of Wi-Fi and Bluetooth (BT) module.";
CM_ SG_ 991 UI_sohHealthStatus "Touchscreen user interface computer: soh health status";
CM_ SG_ 991 UI_selfParkState "Reports the auto park state changes.; raw 255 = signal not available (SNA)";
CM_ SG_ 991 UI_summonDeviceIndex "Reports which device is being used to control summon.";
CM_ SG_ 991 UI_sentryModeCameraDetection "Touchscreen user interface computer: sentry mode camera detection";
CM_ SG_ 991 UI_wakeOnIPActive "Touchscreen user interface computer: wake on IP active";
CM_ BO_ 663 "Touchscreen user interface computer message: suspension control; forwarded onto this bus by the gateway";
CM_ SG_ 663 UI_adaptiveRideRequest "UI customer adaptive ride request for air suspension.";
CM_ SG_ 663 UI_suspensionLoweringRequest "Touchscreen user interface computer: suspension lowering request; raw 3 = signal not available (SNA)";
CM_ SG_ 663 UI_geofenceLevelingRequest "Geofence level request from customer; raw 5 = signal not available (SNA)";
CM_ SG_ 663 UI_jackModeToggleRequest "Touchscreen user interface computer: jack mode toggle request";
CM_ SG_ 663 UI_adaptiveTuningRequest0 "Touchscreen user interface computer: adaptive tuning request0";
CM_ SG_ 663 UI_adaptiveTuningRequest1 "Touchscreen user interface computer: adaptive tuning request1";
CM_ SG_ 663 UI_roadRoughnessLookahead "Touchscreen user interface computer: road roughness lookahead; raw 127 = signal not available (SNA)";
CM_ SG_ 663 UI_roadRoughnessStart "Touchscreen user interface computer: road roughness start; raw 31 = signal not available (SNA)";
CM_ SG_ 663 UI_mapVersionUsed "Touchscreen user interface computer: map version used; raw 255 = signal not available (SNA)";
CM_ SG_ 663 UI_suspensionControlCounter "Touchscreen user interface computer: suspension control counter";
CM_ SG_ 663 UI_suspensionLevelRequest "Touchscreen user interface computer: suspension level request";
CM_ SG_ 663 UI_suspensionControlChecksum "Touchscreen user interface computer: suspension control checksum";
CM_ BO_ 956 "Touchscreen user interface computer message: tpms RC psetting; forwarded onto this bus by the gateway";
CM_ SG_ 956 UI_setRCPFront "Touchscreen user interface computer: set RCP front";
CM_ SG_ 956 UI_setRCPRear "Touchscreen user interface computer: set RCP rear";
CM_ BO_ 787 "Touchscreen user interface computer message: track mode settings; forwarded onto this bus by the gateway";
CM_ SG_ 787 UI_trackModeRequest "User selected track mode";
CM_ SG_ 787 UI_trackRotationTendency "Touchscreen user interface computer: track rotation tendency";
CM_ SG_ 787 UI_trackStabilityAssist "Touchscreen user interface computer: track stability assist";
CM_ SG_ 787 UI_trackPostCooling "Touchscreen user interface computer: track post cooling";
CM_ SG_ 787 UI_trackCmpOverclock "Touchscreen user interface computer: track cmp overclock";
CM_ SG_ 787 UI_trackModeBrakeTemps "Touchscreen user interface computer: track mode brake temps";
CM_ SG_ 787 UI_trackDrivePowerAvailability "Reports power deployment strategy for Track Mode. Ranges from endurance limit to maximum power.";
CM_ SG_ 787 UI_trackModeSettingsCounter "Touchscreen user interface computer: track mode settings counter";
CM_ SG_ 787 UI_trackModeSettingsChecksum "Touchscreen user interface computer: track mode settings checksum";
CM_ BO_ 839 "Touchscreen user interface computer message: trip planning; forwarded onto this bus by the gateway";
CM_ SG_ 839 UI_tripPlanningActive "Indicates that there is active route in navigation with a valid energy at destination prediction.";
CM_ SG_ 839 UI_navToSupercharger "Navigation destination is a supercharger";
CM_ SG_ 839 UI_navFastchargerType "when navigation is turned on, this enum identifies the type of fastcharger the car is navigating to based on the rated power from sc_locations";
CM_ SG_ 839 UI_battPreconditionOnNavState "Indicates to battery and thermal systems whether the battery should be actively heated, passively heated, actively cooled, or passively cooled";
CM_ SG_ 839 UI_requestActiveBatteryHeating "Flag to request BMS enable active battery heating";
CM_ SG_ 839 UI_battPreconditionOnNavPowerReq "The preconditioning power that Trip Planner is requesting from the thermal system to use for battery preconditioning (cooling or heating).; raw 127 = signal not available (SNA)";
CM_ SG_ 839 UI_battPreconditionOnNavTargetT "The pack temperature that Trip Planner is targeting upon arriving to a fast charger.; raw 255 = signal not available (SNA)";
CM_ SG_ 839 UI_ambientTempAtDestination "Touchscreen user interface computer: ambient temp at destination; raw 128 = signal not available (SNA)";
CM_ SG_ 839 UI_energyAtDestination "expected energy at destination in kWh for current navigation route; raw 32768 = signal not available (SNA)";
CM_ BO_ 627 "Touchscreen user interface computer message: vehicle control; forwarded onto this bus by the gateway";
CM_ SG_ 627 UI_powerStateRequest "Request accessory power";
CM_ SG_ 627 UI_childDoorLockOnRight "UI child door lock request status.";
CM_ SG_ 627 UI_frontFogSwitch "Request for front fog lights to be on";
CM_ SG_ 627 UI_summonActive "Summon is active";
CM_ SG_ 627 UI_frunkRequest "Request open frunk";
CM_ SG_ 627 UI_wiperMode "Wiper mode state; raw 0 = signal not available (SNA)";
CM_ SG_ 627 UI_steeringBacklightEnabled "Touchscreen user interface computer: steering backlight enabled";
CM_ SG_ 627 UI_steeringButtonMode "Steering wheel control mode";
CM_ SG_ 627 UI_walkUpUnlock "Walk up unlock request (datavalue defaults to false)";
CM_ SG_ 627 UI_walkAwayLock "Walk away door lock setting.";
CM_ SG_ 627 UI_unlockOnPark "Unlock on park setting";
CM_ SG_ 627 UI_globalUnlockOn "Global Unlock Setting";
CM_ SG_ 627 UI_childDoorLockOnLeft "UI child door lock request status.";
CM_ SG_ 627 UI_lockRequest "Lock or unlock request; raw 7 = signal not available (SNA)";
CM_ SG_ 627 UI_alarmEnabled "UI customer level request to enable alarm.";
CM_ SG_ 627 UI_intrusionSensorOn "Touchscreen user interface computer: intrusion sensor on";
CM_ SG_ 627 UI_stop12vSupport "UI request to stop rails as 12v support";
CM_ SG_ 627 UI_rearFogSwitch "Request for rear fog lights to be on";
CM_ SG_ 627 UI_mirrorFoldRequest "Fold the mirrors; raw 3 = signal not available (SNA)";
CM_ SG_ 627 UI_mirrorHeatRequest "Customer usage of mirror heater and rear defrost";
CM_ SG_ 627 UI_remoteStartRequest "remote start or self park request; raw 4 = signal not available (SNA)";
CM_ SG_ 627 UI_seeYouHomeLightingOn "Headlights after exit";
CM_ SG_ 627 UI_powerOff "power off rails request.";
CM_ SG_ 627 UI_displayBrightnessLevel "UI brightness; raw 255 = signal not available (SNA)";
CM_ SG_ 627 UI_ambientLightingEnabled "Touchscreen user interface computer: ambient lighting enabled";
CM_ SG_ 627 UI_autoHighBeamEnabled "Enable Automatic High/Low Beams";
CM_ SG_ 627 UI_frontLeftSeatHeatReq "Request for front left seat heat";
CM_ SG_ 627 UI_frontRightSeatHeatReq "Request for front left seat heat";
CM_ SG_ 627 UI_rearLeftSeatHeatReq "UI request for second row left seat heater";
CM_ SG_ 627 UI_rearCenterSeatHeatReq "UI request for second row middle seat heater";
CM_ SG_ 627 UI_rearRightSeatHeatReq "UI request for second row right seat heater";
CM_ SG_ 627 UI_autoFoldMirrorsOn "Enable Automatic Mirror Fold/Unfold";
CM_ SG_ 627 UI_mirrorDipOnReverse "Enable Mirror Dip On Reverse";
CM_ SG_ 627 UI_remoteClosureRequest "remote actuate trunk; raw 3 = signal not available (SNA)";
CM_ SG_ 627 UI_wiperRequest "Wiper speed; raw 0 = signal not available (SNA)";
CM_ SG_ 627 UI_domeLightSwitch "Dome light switch";
CM_ SG_ 627 UI_honkHorn "Touchscreen user interface computer: honk horn";
CM_ SG_ 627 UI_driveStateRequest "Touchscreen user interface computer: drive state request";
CM_ SG_ 627 UI_rearWindowLockout "Touchscreen user interface computer: rear window lockout";
CM_ BO_ 947 "Touchscreen user interface computer message: vehicle control2; forwarded onto this bus by the gateway";
CM_ SG_ 947 UI_gloveboxRequest "UI request to open the glovebox";
CM_ SG_ 947 UI_trunkRequest "Rear trunk request";
CM_ SG_ 947 UI_UMCUpdateInhibit "Touchscreen user interface computer: UMC update inhibit";
CM_ SG_ 947 UI_WCUpdateInhibit "Touchscreen user interface computer: WC update inhibit";
CM_ SG_ 947 UI_soundHornOnLock "Touchscreen user interface computer: sound horn on lock";
CM_ SG_ 947 UI_locksPanelActive "Touchscreen user interface computer: locks panel active";
CM_ SG_ 947 UI_PINToDriveEnabled "UI customer level request to pin to drive enabled.";
CM_ SG_ 947 UI_PINToDrivePassed "UI customer level request to enable drive with pin passed.";
CM_ SG_ 947 UI_disableMirrorAutoDim "Request to disable side and rear-view mirror auto dim";
CM_ SG_ 947 UI_lightSwitch "Headlight mode; raw 4 = signal not available (SNA)";
CM_ SG_ 947 UI_readyToAddKey "Ready to add key";
CM_ SG_ 947 UI_alarmTriggerRequest "Alarm activation request from UI";
CM_ SG_ 947 UI_VCSECFeature1 "Touchscreen user interface computer: VCSEC feature1";
CM_ SG_ 947 UI_VCLEFTFeature1 "Touchscreen user interface computer: VCLEFT feature1";
CM_ SG_ 947 UI_summonState "Touchscreen user interface computer: summon state; raw 0 = signal not available (SNA)";
CM_ SG_ 947 UI_displayOnForUser "User is present";
CM_ SG_ 947 UI_freeRollModeRequest "Touchscreen user interface computer: free roll mode request";
CM_ SG_ 947 UI_BLEPushNotificationRequest "Reports that the User Interface (UI) wants to talk to a phone and Vehicle Controller Security (VCSEC) should let all connected phones know.";
CM_ SG_ 947 UI_pairKeyQRCodeDisplaying "Touchscreen user interface computer: pair key QR code displaying";
CM_ SG_ 947 UI_keepAutopilotAwake "Reports the request for Vehicle Controller (VC) to keep autopilot awake.";
CM_ SG_ 947 UI_batteryPreconditioningRequest "Requests battery preconditioning.";
CM_ SG_ 947 UI_coastDownMode "Touchscreen user interface computer: coast down mode";
CM_ SG_ 947 UI_autopilotPowerStateRequest "Requests different power states from autopilot ECU depending on feature usage.";
CM_ SG_ 947 UI_shorted12VCellTestMode "Touchscreen user interface computer: shorted12 v cell test mode";
CM_ SG_ 947 UI_autoRollWindowsOnLockEnable "UI customer level request to enable auto-roll windows on lock";
CM_ SG_ 947 UI_virtualPitchSensorOverrideOKF "Touchscreen user interface computer: virtual pitch sensor override OK for aim";
CM_ SG_ 947 UI_conditionalLoggingEnabledVCSE "Touchscreen user interface computer: conditional logging enabled VCSEC";
CM_ SG_ 947 UI_WC3UpdateInhibit "Touchscreen user interface computer: WC3 update inhibit";
CM_ SG_ 947 UI_steeringWheelHeatReq "Request to enable steering wheel heater";
CM_ SG_ 947 UI_disableHorn "Request to disable horn";
CM_ SG_ 947 UI_frontLeftSeatFanReq "Request for front left seat ventilation";
CM_ SG_ 947 UI_frontRightSeatAutoClimateReq "UI setting to enable auto seat heating and cooling for front right seat";
CM_ SG_ 947 UI_frontRightSeatFanReq "Request for front left seat ventilation";
CM_ SG_ 947 UI_sleepFeature1 "Touchscreen user interface computer: sleep feature1";
CM_ SG_ 947 UI_dcr12VThreshold "Touchscreen user interface computer: dcr12 v threshold";
CM_ SG_ 947 UI_frontLeftSeatAutoClimateReq "UI setting to enable auto seat heating and cooling for front left seat";
CM_ SG_ 947 UI_wiperHeaterReq "UI request to enable the wiper heater";
CM_ SG_ 947 UI_tireSeason "Touchscreen user interface computer: tire season";
CM_ SG_ 947 UI_saveTireConfigReq "Touchscreen user interface computer: save tire config req";
CM_ SG_ 947 UI_silentAlarm "Signal indicating alarms should be silenced";
CM_ SG_ 947 UI_sleepFeature2 "Touchscreen user interface computer: sleep feature2";
CM_ BO_ 660 "Touchscreen user interface computer message: vehicle control3; forwarded onto this bus by the gateway";
CM_ SG_ 660 UI_lightFlashRequest "UI flash lights request";
CM_ SG_ 660 UI_keylessDrivingEnabled "Touchscreen user interface computer: keyless driving enabled";
CM_ SG_ 660 UI_phoneCallActive "On phone call via Bluetooth if active";
CM_ SG_ 660 UI_drivingSideVEH "Touchscreen user interface computer: driving side VEH";
CM_ SG_ 660 UI_keyPairResponse "Touchscreen user interface computer: key pair response";
CM_ SG_ 660 UI_lightShowClosuresEnabled "Closure movements enabled during light show";
CM_ SG_ 660 UI_steeringWheelHeatAutoReq "UI setting to request auto steering wheel heat";
CM_ SG_ 660 UI_steeringWheelHeatLevelReq "Request for steering wheel heat";
CM_ SG_ 660 UI_headlightPulseRequest "Request headlights to pulse";
CM_ SG_ 660 UI_VCSECFeature2 "Touchscreen user interface computer: VCSEC feature2";
CM_ SG_ 660 UI_VCSECFeature3 "Touchscreen user interface computer: VCSEC feature3";
CM_ SG_ 660 UI_VCSECFeature4 "Touchscreen user interface computer: VCSEC feature4";
CM_ SG_ 660 UI_VCSECFeature5 "Touchscreen user interface computer: VCSEC feature5";
CM_ SG_ 660 UI_shortHornRequest "Touchscreen user interface computer: short horn request";
CM_ SG_ 660 UI_packTempLoggingRequest "Touchscreen user interface computer: pack temp logging request";
CM_ SG_ 660 UI_UMC3UpdateInhibit "Touchscreen user interface computer: UMC3 update inhibit";
CM_ SG_ 660 UI_handsFreeTrunk "Touchscreen user interface computer: hands free trunk";
CM_ SG_ 660 UI_displayRedShiftActive "UI's reduce blue light setting is active";
CM_ SG_ 660 UI_handsFreeFrunk "Touchscreen user interface computer: hands free frunk";
CM_ SG_ 660 UI_fasciaCameraWashRequest "User request to activate fascia camera wash";
CM_ SG_ 660 UI_autoClosuresExcludeHome "Touchscreen user interface computer: auto closures exclude home";
CM_ SG_ 660 UI_leftRearSeatAdjustmentRequest "Reports request from UI to actuate the left rear seat";
CM_ SG_ 660 UI_rightRearSeatAdjustmentReques "Reports request from UI to actuate the right rear seat";
CM_ SG_ 660 UI_blindSpotIndicatorLightReques "Request for blind spot indicator light";
CM_ SG_ 660 UI_etcBluetoothControl "Touchscreen user interface computer: etc bluetooth control";
CM_ SG_ 660 UI_keepOnAccessoryPortsReq "User setting to keep 12V outlets, USB ports, and phone chargers powered in CONDITIONING";
CM_ SG_ 660 UI_fasciaCameraShown "Whether the UI is currently showing the fascia camera view";
CM_ SG_ 660 UI_rearSeatChildLock "Reports the state of second row seat fold flat child lock from the UI";
CM_ SG_ 660 UI_windowPercentageRequest "Reports the window percentage value when window request is WINDOW_REQUEST_GOTO_PERCENT.";
CM_ SG_ 660 UI_windowRequestedFL "Reports that the front left window is requested.";
CM_ SG_ 660 UI_windowRequestedFR "Reports that the front right window is requested.";
CM_ SG_ 660 UI_windowRequestedRL "Reports that the rear left window is requested.";
CM_ SG_ 660 UI_windowRequestedRR "Reports that the rear right window is requested.";
CM_ SG_ 660 UI_windowRequest "Window operation request from the mobile app.";
CM_ SG_ 660 UI_closeTrunkRequest "Explicity request for the rear trunk to close";
CM_ SG_ 660 UI_childPresenceDetectionDisable "User request to disable child presence detection behaviors until the next drive cycle";
CM_ SG_ 660 UI_derivedLoadshedFeature "Reports whether vehicle controllers should enable derived loadshed feature.";
CM_ SG_ 660 UI_rearSeatFoldConfirmed "Touchscreen user interface computer: rear seat fold confirmed";
CM_ SG_ 660 UI_leftRearSeatRequestFromRearDi "Touchscreen user interface computer: left rear seat request from rear display";
CM_ SG_ 660 UI_selfParkStandingBy "Reports that summon is in standby.";
CM_ SG_ 660 UI_rightRearSeatRequestFromRearD "Touchscreen user interface computer: right rear seat request from rear display";
CM_ BO_ 853 "Touchscreen user interface computer message: vehicle control thermal; forwarded onto this bus by the gateway";
CM_ SG_ 853 UI_coolantFlowRequest "request for coolant flow to MCU in LPM";
CM_ SG_ 853 UI_inletActiveCoolTarget "request for coolant temperature at Car Computer inlet";
CM_ SG_ 853 UI_disableHVPTThermalLoads "Request thermal system to disable active battery heating";
CM_ SG_ 853 UI_enableCompLiquidPumpOut "Touchscreen user interface computer: enable comp liquid pump out";
CM_ SG_ 853 UI_enableCOP1HighSHOperation "Touchscreen user interface computer: enable COP1 high SH operation";
CM_ SG_ 853 UI_enableIncreasedEvapRampRate "Touchscreen user interface computer: enable increased evap ramp rate";
CM_ SG_ 853 UI_enableCOP1BatteryHeating "Touchscreen user interface computer: enable COP1 battery heating";
CM_ SG_ 853 UI_enableCOP1CabinHeatingBattery "Touchscreen user interface computer: enable COP1 cabin heating battery heating";
CM_ SG_ 853 UI_enableLouverAutoDetection "Touchscreen user interface computer: enable louver auto detection";
CM_ SG_ 853 UI_enableUserFacingLowFlowDelive "Touchscreen user interface computer: enable user facing low flow delivery alert";
CM_ SG_ 853 UI_disableHvacCameraOnlyDefog "Touchscreen user interface computer: disable hvac camera only defog";
CM_ SG_ 853 UI_enableEXVFastCalibration "Touchscreen user interface computer: enable EXV fast calibration";
CM_ SG_ 853 UI_geofencedLiftgateHeight "Touchscreen user interface computer: geofenced liftgate height; raw 255 = signal not available (SNA)";
CM_ SG_ 853 UI_enableConservativeBatteryHeat "Touchscreen user interface computer: enable conservative battery heating";
CM_ SG_ 853 UI_enableDefaultApTempTarget "Touchscreen user interface computer: enable default ap temp target";
CM_ BO_ 644 "Touchscreen user interface computer message: vehicle modes; forwarded onto this bus by the gateway";
CM_ SG_ 644 UI_factoryMode "Touchscreen user interface computer: factory mode";
CM_ SG_ 644 UI_transportMode "Reports UI Transport mode. Distinct from GTW transport mode.";
CM_ SG_ 644 UI_showroomMode "Reports UI showroom mode.";
CM_ SG_ 644 UI_serviceMode "Service diagnostics mode active";
CM_ SG_ 644 UI_isDelivered "Touchscreen user interface computer: is delivered";
CM_ SG_ 644 UI_hasEverBeenDelivered "Touchscreen user interface computer: has ever been delivered";
CM_ SG_ 644 UI_homelinkV2Command0 "Touchscreen user interface computer: homelink V2 command0";
CM_ SG_ 644 UI_homelinkV2Command1 "Touchscreen user interface computer: homelink V2 command1";
CM_ SG_ 644 UI_homelinkV2Command2 "Touchscreen user interface computer: homelink V2 command2";
CM_ SG_ 644 UI_carWashMode "Car Wash Mode";
CM_ SG_ 644 UI_valetMode "Touchscreen user interface computer: valet mode";
CM_ SG_ 644 UI_gameMode "Game mode";
CM_ SG_ 644 UI_diagnosticsAllowed "Touchscreen user interface computer: diagnostics allowed";
CM_ SG_ 644 UI_serviceModePlus "Extended service diagnostics mode active";
CM_ SG_ 644 UI_premiumAmpPowerOff "Premium amplifier power off request";
CM_ SG_ 644 UI_signedCmdHardLocked "Touchscreen user interface computer: signed cmd hard locked";
CM_ SG_ 644 UI_signedCmdServiceMode "Signal reported by Touchscreen user interface computer";
CM_ SG_ 644 UI_closureEasterEggStatus "Touchscreen user interface computer: closure easter egg status";
CM_ SG_ 644 UI_lightShowType "Type of the light show to be run";
CM_ SG_ 644 UI_sohTestRequest "Touchscreen user interface computer: soh test request";
CM_ SG_ 644 UI_vehicleModesCounter "Touchscreen user interface computer: vehicle modes counter";
CM_ SG_ 644 UI_vehicleModesChecksum "Touchscreen user interface computer: vehicle modes checksum";
CM_ BO_ 595 "Touchscreen user interface computer message: vent panel control request; forwarded onto this bus by the gateway";
CM_ SG_ 595 UI_ventPanelControlRequestIndex "Touchscreen user interface computer: vent panel control request index";
CM_ SG_ 595 UI_ventPanelLeftPositionX "Airwave left X position.";
CM_ SG_ 595 UI_ventPanelLeftPositionY "Airwave left Y position.";
CM_ SG_ 595 UI_ventPanelLeftLateralSplit "Airwave left split amount.";
CM_ SG_ 595 UI_ventPanelRightPositionX "Airwave right X position.";
CM_ SG_ 595 UI_ventPanelRightPositionY "Airwave right Y position.";
CM_ SG_ 595 UI_ventPanelRightLateralSplit "Airwave right split amount.";
CM_ SG_ 595 UI_ventPanelLeftLateralMode "Airwave left focus or split.";
CM_ SG_ 595 UI_ventPanelRightLateralMode "Airwave right focus or split.";
CM_ SG_ 595 UI_hvacReqActiveVents "Active airwave sides - left/right/both";
CM_ SG_ 595 UI_vent2RLeftPositionX "Airwave left X position.";
CM_ SG_ 595 UI_vent2RLeftPositionY "Airwave left Y position.";
CM_ SG_ 595 UI_vent2RRightPositionX "Airwave left X position.";
CM_ SG_ 595 UI_vent2RRightPositionY "Airwave left Y position.";
CM_ BO_ 1565 "Touchscreen user interface computer message: weather data service; forwarded onto this bus by the gateway";
CM_ SG_ 1565 UI_weatherSvcTimeSinceLast "Touchscreen user interface computer: weather svc time since last; raw 2047 = signal not available (SNA)";
CM_ SG_ 1565 UI_weatherSvcTemperature "Touchscreen user interface computer: weather svc temperature; raw 127 = signal not available (SNA)";
CM_ SG_ 1565 UI_weatherSvcHumidity "Touchscreen user interface computer: weather svc humidity; raw 255 = signal not available (SNA)";
CM_ SG_ 1565 UI_weatherSvcDewPoint "Touchscreen user interface computer: weather svc dew point; raw 255 = signal not available (SNA)";
CM_ SG_ 1565 UI_weatherSvcCloudCover "Touchscreen user interface computer: weather svc cloud cover; raw 255 = signal not available (SNA)";
CM_ BO_ 1533 "UMC ECU message: alert log";
CM_ SG_ 1533 UMC_alertID "UMC ECU: alert ID";
CM_ SG_ 1533 UMC_alertType "UMC ECU: alert type";
CM_ SG_ 1533 UMC_a001_groundImpedance "UMC ECU: a001 ground impedance";
CM_ SG_ 1533 UMC_a002_ccidRmsCurrent "UMC ECU: a002 ccid rms current";
CM_ SG_ 1533 UMC_a002_ccidRmsCurrentAvg "UMC ECU: a002 ccid rms current avg";
CM_ SG_ 1533 UMC_a002_ccidFaultReason "UMC ECU: a002 ccid fault reason; raw 0 = signal not available (SNA)";
CM_ SG_ 1533 UMC_a002_ccidFaultBucket "UMC ECU: a002 ccid fault bucket";
CM_ SG_ 1533 UMC_a003_faultType "UMC ECU: a003 fault type";
CM_ SG_ 1533 UMC_a003_ccidSelfTestDuty "UMC ECU: a003 ccid self test duty";
CM_ SG_ 1533 UMC_a003_ccidSelfTestCurrent "UMC ECU: a003 ccid self test current";
CM_ SG_ 1533 UMC_a004_lineVoltage "UMC ECU: a004 line voltage";
CM_ SG_ 1533 UMC_a004_inputVoltage "UMC ECU: a004 input voltage";
CM_ SG_ 1533 UMC_a004_inputNeutralVoltage "UMC ECU: a004 input neutral voltage";
CM_ SG_ 1533 UMC_a005_lineVoltage "UMC ECU: a005 line voltage";
CM_ SG_ 1533 UMC_a005_inputVoltage "UMC ECU: a005 input voltage";
CM_ SG_ 1533 UMC_a005_inputNeutralVoltage "UMC ECU: a005 input neutral voltage";
CM_ SG_ 1533 UMC_a006_outputVoltage "UMC ECU: a006 output voltage";
CM_ SG_ 1533 UMC_a006_faultType "UMC ECU: a006 fault type";
CM_ SG_ 1533 UMC_a006_umcReceptacleVoltage "UMC ECU: a006 umc receptacle voltage";
CM_ SG_ 1533 UMC_a006_handleVoltage "UMC ECU: a006 handle voltage";
CM_ SG_ 1533 UMC_a006_line1StuckClosed "UMC ECU: a006 line1 stuck closed";
CM_ SG_ 1533 UMC_a006_line2StuckClosed "UMC ECU: a006 line2 stuck closed";
CM_ SG_ 1533 UMC_a007_pcbaTemp "UMC ECU: a007 pcba temp";
CM_ SG_ 1533 UMC_a008_wallPlugTemp "UMC ECU: a008 wall plug temp";
CM_ SG_ 1533 UMC_a008_SA_region "UMC ECU: a008 SA region";
CM_ SG_ 1533 UMC_a008_SA_current "UMC ECU: a008 SA current";
CM_ SG_ 1533 UMC_a009_vehConnTemp "UMC ECU: a009 veh conn temp";
CM_ SG_ 1533 UMC_a010_inputTerminalsTemp "UMC ECU: a010 input terminals temp";
CM_ SG_ 1533 UMC_a012_pilotHigh "UMC ECU: a012 pilot high";
CM_ SG_ 1533 UMC_a012_pilotLow "UMC ECU: a012 pilot low";
CM_ SG_ 1533 UMC_a013_SA_region "UMC ECU: a013 SA region";
CM_ SG_ 1533 UMC_a013_SA_current "UMC ECU: a013 SA current";
CM_ SG_ 1533 UMC_a015_SA_region "UMC ECU: a015 SA region";
CM_ SG_ 1533 UMC_a015_SA_current "UMC ECU: a015 SA current";
CM_ SG_ 1533 UMC_a016_pcbaTemp "UMC ECU: a016 pcba temp";
CM_ SG_ 1533 UMC_a017_wallPlugTemp "UMC ECU: a017 wall plug temp";
CM_ SG_ 1533 UMC_a017_SA_region "UMC ECU: a017 SA region";
CM_ SG_ 1533 UMC_a017_SA_current "UMC ECU: a017 SA current";
CM_ SG_ 1533 UMC_a018_vehConnTemp "UMC ECU: a018 veh conn temp";
CM_ SG_ 1533 UMC_a019_inputTerminalsTemp "UMC ECU: a019 input terminals temp";
CM_ SG_ 1533 UMC_a024_groundImpedance "UMC ECU: a024 ground impedance";
CM_ SG_ 1533 UMC_a040_groundImpedance "UMC ECU: a040 ground impedance";
CM_ BO_ 824 "UMC ECU message: alert matrix1";
CM_ SG_ 824 UMC_a001_gndMonIntrptLineSide "UMC ECU: a001 gnd mon intrpt line side";
CM_ SG_ 824 UMC_a002_GFCITripped "UMC ECU: a002 GFCI tripped";
CM_ SG_ 824 UMC_a003_GFCISelfTestFault "UMC ECU: a003 GFCI self test fault";
CM_ SG_ 824 UMC_a004_inputOverVoltage "UMC ECU: a004 input over voltage";
CM_ SG_ 824 UMC_a005_inputUnderVoltage "UMC ECU: a005 input under voltage";
CM_ SG_ 824 UMC_a006_contactorWelded "UMC ECU: a006 contactor welded";
CM_ SG_ 824 UMC_a007_pcbaOT "UMC ECU: a007 pcba OT";
CM_ SG_ 824 UMC_a008_wallPlugOT "UMC ECU: a008 wall plug OT";
CM_ SG_ 824 UMC_a009_vehConnOT "UMC ECU: a009 veh conn OT";
CM_ SG_ 824 UMC_a010_inputOT "UMC ECU: a010 input OT";
CM_ SG_ 824 UMC_a011_proxDisconnected "UMC ECU: a011 prox disconnected";
CM_ SG_ 824 UMC_a012_pilotFault "UMC ECU: a012 pilot fault";
CM_ SG_ 824 UMC_a013_SA_Temperature "UMC ECU: a013 SA temperature";
CM_ SG_ 824 UMC_a014_SA_Genealogy "UMC ECU: a014 SA genealogy";
CM_ SG_ 824 UMC_a015_SA_Connection "UMC ECU: a015 SA connection";
CM_ SG_ 824 UMC_a016_pcbaOTFoldback "UMC ECU: a016 pcba OT foldback";
CM_ SG_ 824 UMC_a017_wallPlugOTFoldback "UMC ECU: a017 wall plug OT foldback";
CM_ SG_ 824 UMC_a018_vehConnOTFoldback "UMC ECU: a018 veh conn OT foldback";
CM_ SG_ 824 UMC_a019_inputOTFoldback "UMC ECU: a019 input OT foldback";
CM_ SG_ 824 UMC_a020_applicationCRC "UMC ECU: a020 application CRC";
CM_ SG_ 824 UMC_a021_dataBus "UMC ECU: a021 data bus";
CM_ SG_ 824 UMC_a022_criticalRAM "UMC ECU: a022 critical RAM";
CM_ SG_ 824 UMC_a023_adcSelfTest "UMC ECU: a023 adc self test";
CM_ SG_ 824 UMC_a024_gndResistanceHigh "UMC ECU: a024 gnd resistance high";
CM_ SG_ 824 UMC_a025_cntrOpenExpectedClose "UMC ECU: a025 cntr open expected close";
CM_ SG_ 824 UMC_a026_vRefOutOfRange "UMC ECU: a026 v ref out of range";
CM_ SG_ 824 UMC_a027_watchdogExpired "UMC ECU: a027 watchdog expired";
CM_ SG_ 824 UMC_a028_processorBooted "UMC ECU: a028 processor booted";
CM_ SG_ 824 UMC_a029_acPowerLoss "UMC ECU: a029 ac power loss";
CM_ SG_ 824 UMC_a030_acLostPllLock "UMC ECU: a030 ac lost pll lock";
CM_ SG_ 824 UMC_a031_relayCoilVIrrational "UMC ECU: a031 relay coil v irrational";
CM_ SG_ 824 UMC_a032_chcVitalsRequestFailure "UMC ECU: a032 chc vitals request failure";
CM_ SG_ 824 UMC_a033_chcUpdateFault "UMC ECU: a033 chc update fault";
CM_ SG_ 824 UMC_a034_v2lSAUnsupported "UMC ECU: a034 v2l SA unsupported";
CM_ SG_ 824 UMC_a035_v2lHVACDetected "UMC ECU: a035 v2l HVAC detected";
CM_ SG_ 824 UMC_a037_GFCICalibration "UMC ECU: a037 GFCI calibration";
CM_ SG_ 824 UMC_a038_chcVitalsFault "UMC ECU: a038 chc vitals fault";
CM_ SG_ 824 UMC_a039_inputOverCurrent "UMC ECU: a039 input over current";
CM_ SG_ 824 UMC_a040_gndDisconnected "UMC ECU: a040 gnd disconnected";
CM_ BO_ 1285 "UMC ECU message: smart adapter info";
CM_ SG_ 1285 SA_infoIndex "UMC ECU: info index";
CM_ SG_ 1285 SA_genealogyVersion "UMC ECU: genealogy version";
CM_ SG_ 1285 SA_genealogyCrc "UMC ECU: genealogy crc";
CM_ SG_ 1285 SA_region "Reports the smart adapter region from Electrically Erasable Programmable Read-Only Memory (EEPROM).";
CM_ SG_ 1285 SA_OverTempThreshold "Reports the smart adapter overtemperature threshold from Electrically Erasable Programmable Read-Only Memory (EEPROM).";
CM_ SG_ 1285 SA_partNumInt "Reports the smart adapter part number integer representation.";
CM_ SG_ 1285 SA_partNumRev "Reports the smart adapter part number revision.";
CM_ SG_ 1285 SA_currentLimit "Reports the smart adapter current limit from Electrically Erasable Programmable Read-Only Memory (EEPROM).";
CM_ SG_ 1285 SA_l1Voltage "Reports the smart adapter nominal voltage request from Electrically Erasable Programmable Read-Only Memory (EEPROM).";
CM_ BO_ 609 "Front body controller message: 12 v battery status";
CM_ SG_ 609 VCFRONT_12VBatteryStatusIndex "Front body controller: 12 v battery status index";
CM_ SG_ 609 VCFRONT_good12VforUpdate "Indicates the Low Voltage (LV) battery health as it pertains to permitting an Over-The-Air (OTA) update.";
CM_ SG_ 609 VCFRONT_LVLoadRequest "Controls the loading of the Low Voltage (LV) battery for diagnostic purposes.";
CM_ SG_ 609 VCFRONT_12VBatteryStatusCounter "Front body controller: 12 v battery status counter";
CM_ SG_ 609 VCFRONT_12VBatteryStatusChecksum "Front body controller: 12 v battery status checksum";
CM_ SG_ 609 VCFRONT_batterySupportRequest "Reports the request to the Power Conversion System (PCS) to supply power to the Low Voltage (LV) battery.";
CM_ SG_ 609 VCFRONT_batterySMState "Reports the Low Voltage (LV) battery maintenance state machine state.";
CM_ SG_ 609 VCFRONT_eFuseRecoveryStateDBG "Reports the state of the Low Voltage (LV) battery eFuse recovery state machine.";
CM_ SG_ 609 VCFRONT_batteryLINScheduleDBG "Front body controller: battery LIN schedule DBG; raw 7 = signal not available (SNA)";
CM_ SG_ 609 VCFRONT_resistanceEstimationTest "Front body controller: resistance estimation test counter";
CM_ SG_ 609 VCFRONT_IBSCurrent "Electrical current into the 12V battery";
CM_ SG_ 609 VCFRONT_IBSVoltage "Voltage of the 12V battery; raw 4095 = signal not available (SNA)";
CM_ SG_ 609 VCFRONT_reverseBatteryFault "Indicates a fault on the reverse battery eFuse.";
CM_ SG_ 609 VCFRONT_LVBatterySupported "Indicates whether the Low Voltage (LV) battery is being supported.";
CM_ SG_ 609 VCFRONT_LVBatteryCannotSupportVe "Front body controller: LV battery cannot support vehicle";
CM_ SG_ 609 VCFRONT_goodTemp12VforUpdate "Front body controller: good temp12 vfor update";
CM_ SG_ 609 VCFRONT_12VBatteryTargetVoltage "Reports the target Low Voltage (LV) battery voltage.";
CM_ SG_ 609 VCFRONT_IBSTemperature "Front body controller: IBS temperature; raw 2047 = signal not available (SNA)";
CM_ SG_ 609 VCFRONT_currentSensorMismatchLea "Front body controller: current sensor mismatch leaky bkt pct DBG";
CM_ SG_ 609 VCFRONT_LVBatteryEnergyRemaining "Reports the percentage of energy remaining in the Low Voltage (LV) battery.";
CM_ SG_ 609 VCFRONT_LVBatteryStatusForDrive "Indicates the Low Voltage (LV) battery health status as it pertains to drive readiness. May trigger a Graceful Power Off (GPO) and block drive.";
CM_ SG_ 609 VCFRONT_LVBatteryType "Reports the type of Low Voltage (LV) battery that the firmware is configured for.";
CM_ SG_ 609 VCFRONT_resistanceEstimationNeed "Indication that the conditions which require a resistance estimation test to be performed have been met";
CM_ SG_ 609 VCFRONT_IBSVoltageFiltered "Measures the filtered voltage of the Low Voltage (LV) bus.; raw 16383 = signal not available (SNA)";
CM_ SG_ 609 VCFRONT_LVBMS_LVBusVoltageSource "Reports the source of the Low Voltage (LV) bus voltage used for the Low Voltage Battery Management System (LVBMS).";
CM_ SG_ 609 VCFRONT_LVBMS_LVPackCurrentSourc "Reports the source of the Low Voltage (LV) pack current used for LV battery charge regulation.";
CM_ SG_ 609 VCFRONT_LVBatterySupportRqrdTrig "Reports what caused the Low Voltage (LV) battery support required trigger when the vehicle wakes to charge.";
CM_ SG_ 609 VCFRONT_goodForPCSPowerCycleLeak "Front body controller: good for PCS power cycle leaky bkt DBG";
CM_ SG_ 609 VCFRONT_LVBusControlsFutile "Indicates that a required condition is not met for the Low Voltage (LV) bus controllers to operate properly.";
CM_ SG_ 609 VCFRONT_resistanceEstimatio_0001 "Front body controller: resistance estimation test valid";
CM_ SG_ 609 VCFRONT_resistanceEstimatio_0002 "Front body controller: resistance estimation tests expended";
CM_ SG_ 609 VCFRONT_goodLVChargeForUpdate "Indicates that the Low Voltage (LV) battery charge is sufficient to permit an Over-The-Air (OTA) update.";
CM_ SG_ 609 VCFRONT_opportunisticDCRTestNeed "Front body controller: opportunistic DCR test needed";
CM_ SG_ 609 VCFRONT_voltageProfile "Indicates which voltage profile is used to support the 12V battery";
CM_ SG_ 609 VCFRONT_IBSAmpHours "Measures the energy state of the Low Voltage (LV) battery in amp hours.";
CM_ SG_ 609 VCFRONT_IBSVoltageRawDBG "Front body controller: IBS voltage raw DBG; raw 16383 = signal not available (SNA)";
CM_ SG_ 609 VCFRONT_LVBatteryLINCommsDetecte "Front body controller: LV battery LIN comms detected DBG";
CM_ SG_ 609 VCFRONT_voltageSensorMismatchLea "Front body controller: voltage sensor mismatch leaky bkt pct DBG";
CM_ SG_ 609 VCFRONT_LVBatteryFctryLimOverrid "Front body controller: LV battery fctry lim override ok";
CM_ SG_ 609 VCFRONT_LVBatterySPICommsDetecte "Front body controller: LV battery SPI comms detected DBG";
CM_ SG_ 609 VCFRONT_targetCurrent "Reports the target current set by the Low Voltage Battery Management System (LVBMS).";
CM_ SG_ 609 VCFRONT_PCSMia "Indicates that the Power Conversion System (PCS) is not communicating on CAN.";
CM_ SG_ 609 VCFRONT_chargeNeeded "Indicates that the Low Voltage (LV) battery needs to be charged.";
CM_ SG_ 609 VCFRONT_voltageControlLoopIntegr "Front body controller: voltage control loop integration val";
CM_ SG_ 609 VCFRONT_currentControlLoopIntegr "Front body controller: current control loop integration val";
CM_ BO_ 1847 "Front body controller message: LVBMS info";
CM_ SG_ 1847 VCFRONT_LVBMS_InfoIndex "Front body controller: LVBMS info index";
CM_ SG_ 1847 VCFRONT_LVBMS_PcbaId "Front body controller: LVBMS pcba id";
CM_ SG_ 1847 VCFRONT_LVBMS_AssemblyId "Front body controller: LVBMS assembly id";
CM_ SG_ 1847 VCFRONT_LVBMS_SubUsageId "LVBMS Sub Usage ID; raw 65535 = signal not available (SNA)";
CM_ SG_ 1847 VCFRONT_LVBMS_UsageId "Front body controller: LVBMS usage id";
CM_ SG_ 1847 VCFRONT_LVBMS_AppCRC "LVBMS application cyclic redundancy check";
CM_ SG_ 1847 VCFRONT_LVBMS_FWBuildType "Front body controller: LVBMS FW build type";
CM_ BO_ 1140 "Front body controller message: LV health";
CM_ SG_ 1140 VCFRONT_LVHealthStatus "Health status of the LV system";
CM_ SG_ 1140 VCFRONT_LVStatusForDrive "Front body controller: LV status for drive";
CM_ SG_ 1140 VCFRONT_LVPowerSecondsToSafeHarb "Reports the amount of time (in seconds) the Low Voltage (LV) power system indicates the vehicle has to achieve safe harbor.";
CM_ SG_ 1140 VCFRONT_LVHealthCounter "Front body controller: LV health counter";
CM_ SG_ 1140 VCFRONT_LVHealthChecksum "Front body controller: LV health checksum";
CM_ BO_ 1173 "Front body controller message: LV health debug";
CM_ SG_ 1173 VCFRONT_LVHealthDebugIndex "Front body controller: LV health debug index";
CM_ SG_ 1173 VCFRONT_LVHEALTH_placeholder "Whether the LV health has determined that the <placeholder>";
CM_ SG_ 1173 VCFRONT_LVHEALTH_activeDecelEner "Whether the VCFRONT cannot confirm that the battery has sufficient energy to support an active decel scenario";
CM_ SG_ 1173 VCFRONT_LVHEALTH_criticalPullove "Whether the VCFRONT cannot confirm that the battery has sufficient energy to support a critical pullover scenario";
CM_ SG_ 1173 VCFRONT_LVHEALTH_revBattEFuseOff "Whether the LV health has determined that the LVBMB EFuse has opened";
CM_ SG_ 1173 VCFRONT_LVHEALTH_LVBMBEFuseOpen "Whether the LV health has determined that the LVBMB EFuse has opened";
CM_ SG_ 1173 VCFRONT_LVHEALTH_lvBatteryCommsM "Whether the LV health has determined that LV battery communications are missing";
CM_ SG_ 1173 VCFRONT_LVHEALTH_pcsEFuseOff "Whether VCFRONT has determined that the PCS eFuse is off or faulted when it's needed to be on";
CM_ SG_ 1173 VCFRONT_LVHEALTH_pcsNotActive "Whether the LV health has determined that the PCS is not actively providing LV support";
CM_ SG_ 1173 VCFRONT_LVHEALTH_pcsMIA "Whether the LV health has determined that messages are missing from PCS critical for determining health";
CM_ SG_ 1173 VCFRONT_LVHEALTH_IBSMIA "Whether the LV health has determined that the INA228 LV battery sensor signals are invalid or not yet configured";
CM_ SG_ 1173 VCFRONT_LVHEALTH_LVBatteryElecDi "Whether the VCFRONT has determined that the LV battery is electrically disconnected";
CM_ SG_ 1173 VCFRONT_LVHEALTH_LVBatteryE_0001 "Whether the VCFRONT has determined that the LV battery electrical connection status has been unknown for too long";
CM_ SG_ 1173 VCFRONT_LVHEALTH_pcsOpenCircuit "Whether VCFRONT has determined that the electrical connection between the PCS and VCFRONT is disconnected";
CM_ SG_ 1173 VCFRONT_LVHEALTH_activeDecelPowe "Whether the VCFRONT cannot confirm that the battery has sufficient power to support a active decel scenario";
CM_ SG_ 1173 VCFRONT_LVHEALTH_lvBatteryCapabi "Whether the LV health has determined that LV battery power/energy capability estimation accuracy is too low";
CM_ SG_ 1173 VCFRONT_LVHEALTH_lvBatteryConfig "Whether the LV health has determined that LV battery configuration is incorrect";
CM_ SG_ 1173 VCFRONT_LVHEALTH_lvBatteryImpeda "Whether the LV health has determined that LV battery impedance is too high";
CM_ BO_ 545 "Front body controller message: LV power state";
CM_ SG_ 545 VCFRONT_LVPowerStateIndex "Front body controller: LV power state index";
CM_ SG_ 545 VCFRONT_vehiclePowerState "Front body controller: vehicle power state";
CM_ SG_ 545 VCFRONT_inAccessoryPlus "Front body controller: in accessory plus";
CM_ SG_ 545 VCFRONT_LVShuttingDown "Front body controller: LV shutting down";
CM_ SG_ 545 VCFRONT_LVPowerStateCounter "Front body controller: LV power state counter";
CM_ SG_ 545 VCFRONT_LVPowerStateChecksum "Front body controller: LV power state checksum";
CM_ SG_ 545 VCFRONT_cpLVRequest "Front body controller: cp LV request";
CM_ SG_ 545 VCFRONT_epasLVState "Front body controller: epas LV state";
CM_ SG_ 545 VCFRONT_hvcLVRequest "Front body controller: hvc LV request";
CM_ SG_ 545 VCFRONT_tasLVState "Front body controller: tas LV state";
CM_ SG_ 545 VCFRONT_pcsLVState "Front body controller: pcs LV state";
CM_ SG_ 545 VCFRONT_CMPDLVState "Front body controller: CMPDLV state";
CM_ SG_ 545 VCFRONT_hcmlLVState "Front body controller: hcml LV state";
CM_ SG_ 545 VCFRONT_hcmrLVState "Front body controller: hcmr LV state";
CM_ SG_ 545 VCFRONT_MCUAudioLVState "Front body controller: MCU audio LV state";
CM_ SG_ 545 VCFRONT_espValveLVState "Front body controller: esp valve LV state";
CM_ SG_ 545 VCFRONT_MCUGraphicsLVState "Front body controller: MCU graphics LV state";
CM_ SG_ 545 VC_dcdcSupportRequest "Front body controller: dcdc support request";
CM_ SG_ 545 VC_hvStateRequest "Reports the request for the High Voltage (HV) system state.";
CM_ SG_ 545 VC_persistAccPowerRequestOverrid "Front body controller: persist acc power request overridden";
CM_ SG_ 545 VC_accPortPowerRequest "Front body controller: acc port power request";
CM_ SG_ 545 VC_persistAccPortPowerState "Front body controller: persist acc port power state";
CM_ BO_ 700 "Front body controller message: LV thermal motors10 hz";
CM_ SG_ 700 VCFRONT_LVThermalMotorsIndex "Front body controller: LV thermal motors index";
CM_ SG_ 700 VCFRONT_radiatorFanState "Radiator Fan motor controller state";
CM_ SG_ 700 VCFRONT_radiatorFanTorque "Radiator Fan motor torque; raw 1023 = signal not available (SNA)";
CM_ SG_ 700 VCFRONT_radiatorFanIDc "Radiator Fan DC current; raw 127 = signal not available (SNA)";
CM_ SG_ 700 VCFRONT_mlxLINCurrentSchedule "Currently set schedule for MLX LIN bus";
CM_ SG_ 700 VCFRONT_pumpPowertrainState "Powertrain Pump motor controller state";
CM_ SG_ 700 VCFRONT_pumpPowertrainTorque "Powertrain Pump motor torque; raw 1023 = signal not available (SNA)";
CM_ SG_ 700 VCFRONT_pumpPowertrainIDc "Powertrain Pump DC current; raw 127 = signal not available (SNA)";
CM_ SG_ 700 VCFRONT_pumpBatteryState "Battery Pump motor controller state";
CM_ SG_ 700 VCFRONT_pumpBatteryTorque "Battery Pump motor torque; raw 1023 = signal not available (SNA)";
CM_ SG_ 700 VCFRONT_pumpBatteryIDc "Battery Pump DC current; raw 127 = signal not available (SNA)";
CM_ BO_ 1332 "Front body controller message: alert log";
CM_ SG_ 1332 VCFRONT_alertID "Front body controller: alert ID";
CM_ SG_ 1332 VCFRONT_alertState "Front body controller: alert state";
CM_ SG_ 1332 VCFRONT_a001_InternalWatchdog "Front body controller: a001 internal watchdog";
CM_ SG_ 1332 VCFRONT_a002_CPUUndervoltage "Front body controller: a002 CPU undervoltage";
CM_ SG_ 1332 VCFRONT_a002_PowerOnReset "Front body controller: a002 power on reset";
CM_ SG_ 1332 VCFRONT_a004_APPWatchdogFaultOrM "Front body controller: a004 APP watchdog fault or MIA";
CM_ SG_ 1332 VCFRONT_a004_DASHighLowBeamDecis "Front body controller: a004 DAS high low beam decision SNA";
CM_ SG_ 1332 VCFRONT_a004_DASAdaptiveHighBeam "Front body controller: a004 DAS adaptive high beam fault";
CM_ SG_ 1332 VCFRONT_a004_DASMatrixColumnMsgM "Front body controller: a004 DAS matrix column msg MIA";
CM_ SG_ 1332 VCFRONT_a004_DASBendAngleMsgMIA "Front body controller: a004 DAS bend angle msg MIA";
CM_ SG_ 1332 VCFRONT_a004_EPAS3PNotInSpecOrMI "Front body controller: a004 EPAS3 p not in spec or MIA";
CM_ SG_ 1332 VCFRONT_a008_APPWatchdogFaultOrM "Front body controller: a008 APP watchdog fault or MIA";
CM_ SG_ 1332 VCFRONT_a008_DASHighLowBeamDecis "Front body controller: a008 DAS high low beam decision SNA";
CM_ SG_ 1332 VCFRONT_a008_DASAdaptiveHighBeam "Front body controller: a008 DAS adaptive high beam fault";
CM_ SG_ 1332 VCFRONT_a008_DASMatrixColumnMsgM "Front body controller: a008 DAS matrix column msg MIA";
CM_ SG_ 1332 VCFRONT_a008_DASBendAngleMsgMIA "Front body controller: a008 DAS bend angle msg MIA";
CM_ SG_ 1332 VCFRONT_a008_EPAS3PNotInSpecOrMI "Front body controller: a008 EPAS3 p not in spec or MIA";
CM_ SG_ 1332 VCFRONT_a010_UnderVoltageDetecte "Front body controller: a010 under voltage detected";
CM_ SG_ 1332 VCFRONT_a010_UnderVoltageTimeout "Front body controller: a010 under voltage timeout";
CM_ SG_ 1332 VCFRONT_a015_NVMMMemOverflow "Front body controller: a015 NVMM mem overflow";
CM_ SG_ 1332 VCFRONT_a015_NVMMFilesystemError "Front body controller: a015 NVMM filesystem error";
CM_ SG_ 1332 VCFRONT_a015_NVMMRecordIDError "Front body controller: a015 NVMM record ID error";
CM_ SG_ 1332 VCFRONT_a057_VEH_cpControl "Front body controller: a057 VEH cp control";
CM_ SG_ 1332 VCFRONT_a059_voltageDrop "Front body controller: a059 voltage drop";
CM_ SG_ 1332 VCFRONT_a059_resistanceEstimate "Front body controller: a059 resistance estimate";
CM_ SG_ 1332 VCFRONT_a059_current "Front body controller: a059 current";
CM_ SG_ 1332 VCFRONT_a063_switchChannel "Front body controller: a063 switch channel";
CM_ SG_ 1332 VCFRONT_a063_switchType "Front body controller: a063 switch type";
CM_ SG_ 1332 VCFRONT_a063_ADCVoltage "Front body controller: a063 ADC voltage";
CM_ SG_ 1332 VCFRONT_a063_disconnected "Front body controller: a063 disconnected";
CM_ SG_ 1332 VCFRONT_a063_indeterminate "Front body controller: a063 indeterminate";
CM_ SG_ 1332 VCFRONT_a063_stuckActive "Front body controller: a063 stuck active";
CM_ SG_ 1332 VCFRONT_a063_faulted "Front body controller: a063 faulted";
CM_ SG_ 1332 VCFRONT_a082_RIPC_epbPrivateStat "Front body controller: a082 RIPC epb private state";
CM_ SG_ 1332 VCFRONT_a082_RIPC_remoteHSD "Front body controller: a082 RIPC remote HSD";
CM_ SG_ 1332 VCFRONT_a082_RIPC_railStatus "Front body controller: a082 RIPC rail status";
CM_ SG_ 1332 VCFRONT_a082_RIPC_remoteMux "Front body controller: a082 RIPC remote mux";
CM_ SG_ 1332 VCFRONT_a083_LIPC_epbPrivateStat "Front body controller: a083 LIPC epb private state";
CM_ SG_ 1332 VCFRONT_a083_LIPC_remoteHSD "Front body controller: a083 LIPC remote HSD";
CM_ SG_ 1332 VCFRONT_a083_LIPC_railStatus "Front body controller: a083 LIPC rail status";
CM_ SG_ 1332 VCFRONT_a083_LIPC_HSDFaults "Front body controller: a083 LIPC HSD faults";
CM_ SG_ 1332 VCFRONT_a084_CH_StatusC "Front body controller: a084 CH status c";
CM_ SG_ 1332 VCFRONT_a085_PARTY_buttonStatus "Front body controller: a085 PARTY button status";
CM_ SG_ 1332 VCFRONT_a086_VEH_LVBMS_statusHig "Front body controller: a086 VEH LVBMS status high";
CM_ SG_ 1332 VCFRONT_a086_VEH_LVBMS_statusLow "Front body controller: a086 VEH LVBMS status low";
CM_ SG_ 1332 VCFRONT_a086_VEH_status "Front body controller: a086 VEH status";
CM_ SG_ 1332 VCFRONT_a086_VEH_12VBatteryStatu "Front body controller: a086 VEH 12 v battery status";
CM_ SG_ 1332 VCFRONT_a086_VEH_LVPowerState "Front body controller: a086 VEH LV power state";
CM_ SG_ 1332 VCFRONT_a086_VEH_lightStatus "Front body controller: a086 VEH light status";
CM_ SG_ 1332 VCFRONT_a086_VEH_systemStatus "Front body controller: a086 VEH system status";
CM_ SG_ 1332 VCFRONT_a086_VEH_thermalStatus "Front body controller: a086 VEH thermal status";
CM_ SG_ 1332 VCFRONT_a086_VEH_vehNm "Front body controller: a086 VEH veh nm";
CM_ SG_ 1332 VCFRONT_a087_VEH_temperature "Front body controller: a087 VEH temperature";
CM_ SG_ 1332 VCFRONT_a087_VEH_thermalControl "Front body controller: a087 VEH thermal control";
CM_ SG_ 1332 VCFRONT_a087_VEH_torque "Front body controller: a087 VEH torque";
CM_ SG_ 1332 VCFRONT_a087_VEH_status "Front body controller: a087 VEH status";
CM_ SG_ 1332 VCFRONT_a087_PARTY_torque "Front body controller: a087 PARTY torque";
CM_ SG_ 1332 VCFRONT_a087_PARTY_status "Front body controller: a087 PARTY status";
CM_ SG_ 1332 VCFRONT_a087_PARTY_temperature "Front body controller: a087 PARTY temperature";
CM_ SG_ 1332 VCFRONT_a087_PARTY_thermalContro "Front body controller: a087 PARTY thermal control";
CM_ SG_ 1332 VCFRONT_a088_VEH_temperature "Front body controller: a088 VEH temperature";
CM_ SG_ 1332 VCFRONT_a088_VEH_thermalControl "Front body controller: a088 VEH thermal control";
CM_ SG_ 1332 VCFRONT_a088_VEH_torque "Front body controller: a088 VEH torque";
CM_ SG_ 1332 VCFRONT_a088_VEH_status "Front body controller: a088 VEH status";
CM_ SG_ 1332 VCFRONT_a088_PARTY_torque "Front body controller: a088 PARTY torque";
CM_ SG_ 1332 VCFRONT_a088_PARTY_status "Front body controller: a088 PARTY status";
CM_ SG_ 1332 VCFRONT_a088_PARTY_temperature "Front body controller: a088 PARTY temperature";
CM_ SG_ 1332 VCFRONT_a088_PARTY_thermalContro "Front body controller: a088 PARTY thermal control";
CM_ SG_ 1332 VCFRONT_a089_PARTY_party1 "Front body controller: a089 PARTY party1";
CM_ SG_ 1332 VCFRONT_a089_PARTY_status "Front body controller: a089 PARTY status";
CM_ SG_ 1332 VCFRONT_a089_VEH_status "Front body controller: a089 VEH status";
CM_ SG_ 1332 VCFRONT_a089_BDY_party1 "Front body controller: a089 BDY party1";
CM_ SG_ 1332 VCFRONT_a089_BDY_status "Front body controller: a089 BDY status";
CM_ SG_ 1332 VCFRONT_a089_CH_status "Front body controller: a089 CH status";
CM_ SG_ 1332 VCFRONT_a089_CH_party1 "Front body controller: a089 CH party1";
CM_ SG_ 1332 VCFRONT_a089_CH_party3 "Front body controller: a089 CH party3";
CM_ SG_ 1332 VCFRONT_a089_VEH_party1 "Front body controller: a089 VEH party1";
CM_ SG_ 1332 VCFRONT_a089_VEH_party3 "Front body controller: a089 VEH party3";
CM_ SG_ 1332 VCFRONT_a091_VEH_faultsAndExtras "Front body controller: a091 VEH faults and extras";
CM_ SG_ 1332 VCFRONT_a091_VEH_info "Front body controller: a091 VEH info";
CM_ SG_ 1332 VCFRONT_a091_VEH_state "Front body controller: a091 VEH state";
BA_DEF_ BO_ "GenMsgCycleTime" INT 0 3600000;
BA_DEF_ BO_ "GenMsgSendType" ENUM "Cyclic","NotUsed","NotUsed","NotUsed","NotUsed","NotUsed","NotUsed","IfActive","NoMsgSendType","NotUsed";
BA_DEF_ BO_ "VFrameFormat" ENUM "StandardCAN","ExtendedCAN","reserved","J1939PG","reserved","reserved","reserved","reserved","reserved","reserved","reserved","reserved","reserved","reserved","StandardCAN_FD","ExtendedCAN_FD";
BA_DEF_ BO_ "CANFD_BRS" ENUM "0","1";
BA_DEF_ SG_ "GenSigSNA" STRING;
BA_DEF_ SG_ "SystemSignalLongSymbol" STRING;
BA_DEF_ SG_ "Confidence" ENUM "validated","plausible","layout-only","contradicted";
BA_DEF_DEF_ "GenMsgCycleTime" 0;
BA_DEF_DEF_ "GenMsgSendType" "NoMsgSendType";
BA_DEF_DEF_ "VFrameFormat" "StandardCAN";
BA_DEF_DEF_ "CANFD_BRS" "1";
BA_DEF_DEF_ "GenSigSNA" "";
BA_DEF_DEF_ "SystemSignalLongSymbol" "";
BA_DEF_DEF_ "Confidence" "layout-only";
BA_ "GenMsgCycleTime" BO_ 1523 1000;
BA_ "GenMsgSendType" BO_ 1523 0;
BA_ "GenMsgCycleTime" BO_ 948 500;
BA_ "GenMsgSendType" BO_ 948 0;
BA_ "GenMsgCycleTime" BO_ 955 1000;
BA_ "GenMsgSendType" BO_ 955 0;
BA_ "GenMsgCycleTime" BO_ 827 1000;
BA_ "GenMsgSendType" BO_ 827 0;
BA_ "GenMsgCycleTime" BO_ 661 5000;
BA_ "GenMsgSendType" BO_ 661 0;
BA_ "GenMsgCycleTime" BO_ 820 500;
BA_ "GenMsgSendType" BO_ 820 0;
BA_ "GenMsgCycleTime" BO_ 826 1000;
BA_ "GenMsgSendType" BO_ 826 0;
BA_ "GenMsgCycleTime" BO_ 723 1000;
BA_ "GenMsgSendType" BO_ 723 0;
BA_ "GenMsgCycleTime" BO_ 851 1000;
BA_ "GenMsgSendType" BO_ 851 0;
BA_ "GenMsgCycleTime" BO_ 991 500;
BA_ "GenMsgSendType" BO_ 991 0;
BA_ "GenMsgCycleTime" BO_ 663 500;
BA_ "GenMsgSendType" BO_ 663 0;
BA_ "GenMsgCycleTime" BO_ 956 1000;
BA_ "GenMsgSendType" BO_ 956 0;
BA_ "GenMsgCycleTime" BO_ 787 500;
BA_ "GenMsgSendType" BO_ 787 0;
BA_ "GenMsgCycleTime" BO_ 839 1000;
BA_ "GenMsgSendType" BO_ 839 0;
BA_ "GenMsgCycleTime" BO_ 627 500;
BA_ "GenMsgSendType" BO_ 627 0;
BA_ "GenMsgCycleTime" BO_ 947 500;
BA_ "GenMsgSendType" BO_ 947 0;
BA_ "GenMsgCycleTime" BO_ 660 500;
BA_ "GenMsgSendType" BO_ 660 0;
BA_ "GenMsgCycleTime" BO_ 853 1000;
BA_ "GenMsgSendType" BO_ 853 0;
BA_ "GenMsgCycleTime" BO_ 644 500;
BA_ "GenMsgSendType" BO_ 644 0;
BA_ "GenMsgCycleTime" BO_ 595 500;
BA_ "GenMsgSendType" BO_ 595 0;
BA_ "GenMsgCycleTime" BO_ 1565 500;
BA_ "GenMsgSendType" BO_ 1565 0;
BA_ "GenMsgCycleTime" BO_ 824 1000;
BA_ "GenMsgSendType" BO_ 824 0;
BA_ "GenMsgCycleTime" BO_ 1285 100;
BA_ "GenMsgSendType" BO_ 1285 0;
BA_ "GenMsgCycleTime" BO_ 609 16;
BA_ "GenMsgSendType" BO_ 609 0;
BA_ "GenMsgCycleTime" BO_ 1847 1000;
BA_ "GenMsgSendType" BO_ 1847 0;
BA_ "GenMsgCycleTime" BO_ 1140 100;
BA_ "GenMsgSendType" BO_ 1140 0;
BA_ "GenMsgCycleTime" BO_ 1173 1000;
BA_ "GenMsgSendType" BO_ 1173 0;
BA_ "GenMsgCycleTime" BO_ 545 50;
BA_ "GenMsgSendType" BO_ 545 0;
BA_ "GenMsgCycleTime" BO_ 700 8;
BA_ "GenMsgSendType" BO_ 700 0;
BA_ "Confidence" SG_ 1523 UI_odometer 0;
BA_ "GenSigSNA" SG_ 1523 UI_odometer "16777215";
BA_ "Confidence" SG_ 948 UI_usbFrontHubPowerStateRequest 0;
BA_ "GenSigSNA" SG_ 948 UI_usbFrontHubPowerStateRequest "0";
BA_ "Confidence" SG_ 955 UI_powerExpected 1;
BA_ "Confidence" SG_ 955 UI_powerIdeal 1;
BA_ "Confidence" SG_ 827 UI_idlePowerConsumption 0;
BA_ "Confidence" SG_ 827 UI_chargeTimeUntilTerminationPct 0;
BA_ "GenSigSNA" SG_ 827 UI_chargeTimeUntilTerminationPct "2047";
BA_ "Confidence" SG_ 827 UI_chargeTimeUntilReadyToDepart 0;
BA_ "GenSigSNA" SG_ 827 UI_chargeTimeUntilReadyToDepart "2047";
BA_ "Confidence" SG_ 661 UI_powerRationalityConfigIndex 1;
BA_ "Confidence" SG_ 661 UI_vcleftCfgRationalityThreshold 1;
BA_ "GenSigSNA" SG_ 661 UI_vcleftCfgRationalityThreshold "0";
BA_ "SystemSignalLongSymbol" SG_ 661 UI_vcleftCfgRationalityThreshold "UI_vcleftCfgRationalityThreshold0";
BA_ "Confidence" SG_ 661 UI_vcleftCfgRationalityTime0 1;
BA_ "GenSigSNA" SG_ 661 UI_vcleftCfgRationalityTime0 "0";
BA_ "Confidence" SG_ 661 UI_vcleftCfgRationalityThre_0001 1;
BA_ "GenSigSNA" SG_ 661 UI_vcleftCfgRationalityThre_0001 "0";
BA_ "SystemSignalLongSymbol" SG_ 661 UI_vcleftCfgRationalityThre_0001 "UI_vcleftCfgRationalityThreshold1";
BA_ "Confidence" SG_ 661 UI_vcleftCfgRationalityTime1 1;
BA_ "GenSigSNA" SG_ 661 UI_vcleftCfgRationalityTime1 "0";
BA_ "Confidence" SG_ 661 UI_vcleftCfgRationalityStaticA 1;
BA_ "GenSigSNA" SG_ 661 UI_vcleftCfgRationalityStaticA "65535";
BA_ "Confidence" SG_ 661 UI_vcleftCfgRationalityStaticB 1;
BA_ "GenSigSNA" SG_ 661 UI_vcleftCfgRationalityStaticB "32768";
BA_ "Confidence" SG_ 661 UI_vcleftCfgRationalityStaticC 1;
BA_ "GenSigSNA" SG_ 661 UI_vcleftCfgRationalityStaticC "32768";
BA_ "Confidence" SG_ 661 UI_vcleftCfgRationalityDynamicA 1;
BA_ "GenSigSNA" SG_ 661 UI_vcleftCfgRationalityDynamicA "65535";
BA_ "Confidence" SG_ 661 UI_vcleftCfgRationalityDynamicB 1;
BA_ "GenSigSNA" SG_ 661 UI_vcleftCfgRationalityDynamicB "32768";
BA_ "Confidence" SG_ 661 UI_vcleftCfgRationalityDynamicC 1;
BA_ "GenSigSNA" SG_ 661 UI_vcleftCfgRationalityDynamicC "32768";
BA_ "Confidence" SG_ 661 UI_vcrightCfgRationalityThreshol 1;
BA_ "GenSigSNA" SG_ 661 UI_vcrightCfgRationalityThreshol "0";
BA_ "SystemSignalLongSymbol" SG_ 661 UI_vcrightCfgRationalityThreshol "UI_vcrightCfgRationalityThreshold0";
BA_ "Confidence" SG_ 661 UI_vcrightCfgRationalityTime0 1;
BA_ "GenSigSNA" SG_ 661 UI_vcrightCfgRationalityTime0 "0";
BA_ "Confidence" SG_ 661 UI_vcrightCfgRationalityThr_0001 1;
BA_ "GenSigSNA" SG_ 661 UI_vcrightCfgRationalityThr_0001 "0";
BA_ "SystemSignalLongSymbol" SG_ 661 UI_vcrightCfgRationalityThr_0001 "UI_vcrightCfgRationalityThreshold1";
BA_ "Confidence" SG_ 661 UI_vcrightCfgRationalityTime1 1;
BA_ "GenSigSNA" SG_ 661 UI_vcrightCfgRationalityTime1 "0";
BA_ "Confidence" SG_ 661 UI_vcrightCfgRationalityStaticA 1;
BA_ "GenSigSNA" SG_ 661 UI_vcrightCfgRationalityStaticA "65535";
BA_ "Confidence" SG_ 661 UI_vcrightCfgRationalityStaticB 1;
BA_ "GenSigSNA" SG_ 661 UI_vcrightCfgRationalityStaticB "32768";
BA_ "Confidence" SG_ 661 UI_vcrightCfgRationalityStaticC 1;
BA_ "GenSigSNA" SG_ 661 UI_vcrightCfgRationalityStaticC "32768";
BA_ "Confidence" SG_ 661 UI_vcrightCfgRationalityDynamicA 1;
BA_ "GenSigSNA" SG_ 661 UI_vcrightCfgRationalityDynamicA "65535";
BA_ "Confidence" SG_ 661 UI_vcrightCfgRationalityDynamicB 1;
BA_ "GenSigSNA" SG_ 661 UI_vcrightCfgRationalityDynamicB "32768";
BA_ "Confidence" SG_ 661 UI_vcrightCfgRationalityDynamicC 1;
BA_ "GenSigSNA" SG_ 661 UI_vcrightCfgRationalityDynamicC "32768";
BA_ "Confidence" SG_ 661 UI_vcleftCfgCutoffThreshold0 1;
BA_ "GenSigSNA" SG_ 661 UI_vcleftCfgCutoffThreshold0 "0";
BA_ "Confidence" SG_ 661 UI_vcleftCfgCutoffTime0 1;
BA_ "GenSigSNA" SG_ 661 UI_vcleftCfgCutoffTime0 "0";
BA_ "Confidence" SG_ 661 UI_vcleftCfgCutoffThreshold1 1;
BA_ "GenSigSNA" SG_ 661 UI_vcleftCfgCutoffThreshold1 "0";
BA_ "Confidence" SG_ 661 UI_vcleftCfgCutoffTime1 1;
BA_ "GenSigSNA" SG_ 661 UI_vcleftCfgCutoffTime1 "0";
BA_ "Confidence" SG_ 661 UI_vcleftCfgCutoffStaticA 1;
BA_ "GenSigSNA" SG_ 661 UI_vcleftCfgCutoffStaticA "65535";
BA_ "Confidence" SG_ 661 UI_vcleftCfgCutoffStaticB 1;
BA_ "GenSigSNA" SG_ 661 UI_vcleftCfgCutoffStaticB "32768";
BA_ "Confidence" SG_ 661 UI_vcleftCfgCutoffStaticC 1;
BA_ "GenSigSNA" SG_ 661 UI_vcleftCfgCutoffStaticC "32768";
BA_ "Confidence" SG_ 661 UI_vcleftCfgCutoffDynamicA 1;
BA_ "GenSigSNA" SG_ 661 UI_vcleftCfgCutoffDynamicA "65535";
BA_ "Confidence" SG_ 661 UI_vcleftCfgCutoffDynamicB 1;
BA_ "GenSigSNA" SG_ 661 UI_vcleftCfgCutoffDynamicB "32768";
BA_ "Confidence" SG_ 661 UI_vcleftCfgCutoffDynamicC 1;
BA_ "GenSigSNA" SG_ 661 UI_vcleftCfgCutoffDynamicC "32768";
BA_ "Confidence" SG_ 661 UI_vcrightCfgCutoffThreshold0 1;
BA_ "GenSigSNA" SG_ 661 UI_vcrightCfgCutoffThreshold0 "0";
BA_ "Confidence" SG_ 661 UI_vcrightCfgCutoffTime0 1;
BA_ "GenSigSNA" SG_ 661 UI_vcrightCfgCutoffTime0 "0";
BA_ "Confidence" SG_ 661 UI_vcrightCfgCutoffThreshold1 1;
BA_ "GenSigSNA" SG_ 661 UI_vcrightCfgCutoffThreshold1 "0";
BA_ "Confidence" SG_ 661 UI_vcrightCfgCutoffTime1 1;
BA_ "GenSigSNA" SG_ 661 UI_vcrightCfgCutoffTime1 "0";
BA_ "Confidence" SG_ 661 UI_vcrightCfgCutoffStaticA 1;
BA_ "GenSigSNA" SG_ 661 UI_vcrightCfgCutoffStaticA "65535";
BA_ "Confidence" SG_ 661 UI_vcrightCfgCutoffStaticB 1;
BA_ "GenSigSNA" SG_ 661 UI_vcrightCfgCutoffStaticB "32768";
BA_ "Confidence" SG_ 661 UI_vcrightCfgCutoffStaticC 1;
BA_ "GenSigSNA" SG_ 661 UI_vcrightCfgCutoffStaticC "32768";
BA_ "Confidence" SG_ 661 UI_vcrightCfgCutoffDynamicA 1;
BA_ "GenSigSNA" SG_ 661 UI_vcrightCfgCutoffDynamicA "65535";
BA_ "Confidence" SG_ 661 UI_vcrightCfgCutoffDynamicB 1;
BA_ "GenSigSNA" SG_ 661 UI_vcrightCfgCutoffDynamicB "32768";
BA_ "Confidence" SG_ 661 UI_vcrightCfgCutoffDynamicC 1;
BA_ "GenSigSNA" SG_ 661 UI_vcrightCfgCutoffDynamicC "32768";
BA_ "Confidence" SG_ 820 UI_systemPowerLimit 1;
BA_ "GenSigSNA" SG_ 820 UI_systemPowerLimit "31";
BA_ "Confidence" SG_ 820 UI_pedalMap 0;
BA_ "Confidence" SG_ 820 UI_enableRegenBackfill 0;
BA_ "Confidence" SG_ 820 UI_systemTorqueLimit 1;
BA_ "GenSigSNA" SG_ 820 UI_systemTorqueLimit "63";
BA_ "Confidence" SG_ 820 UI_closureConfirmed 1;
BA_ "Confidence" SG_ 820 UI_regenTorqueMax 0;
BA_ "Confidence" SG_ 820 UI_limitMode 0;
BA_ "SystemSignalLongSymbol" SG_ 820 UI_factoryCustomerDrivingModeReq "UI_factoryCustomerDrivingModeRequest";
BA_ "Confidence" SG_ 820 UI_motorOnMode 0;
BA_ "Confidence" SG_ 820 UI_wasteMode 1;
BA_ "Confidence" SG_ 820 UI_wasteModeRegenLimit 1;
BA_ "Confidence" SG_ 820 UI_stoppingMode 1;
BA_ "Confidence" SG_ 820 UI_speedLimit 1;
BA_ "GenSigSNA" SG_ 820 UI_speedLimit "511";
BA_ "Confidence" SG_ 820 UI_enableSmartShift 1;
BA_ "Confidence" SG_ 820 UI_navVehParallelToRdCanContinue 1;
BA_ "GenSigSNA" SG_ 820 UI_navVehParallelToRdCanContinue "0";
BA_ "Confidence" SG_ 826 UI_ratedRange 0;
BA_ "Confidence" SG_ 826 UI_soe 0;
BA_ "Confidence" SG_ 826 UI_uSoe 0;
BA_ "Confidence" SG_ 826 UI_softPackLimitPct 1;
BA_ "Confidence" SG_ 826 UI_targetFullPackEnergy 1;
BA_ "Confidence" SG_ 723 UI_solarAzimuthAngle 1;
BA_ "GenSigSNA" SG_ 723 UI_solarAzimuthAngle "32768";
BA_ "Confidence" SG_ 723 UI_solarAzimuthAngleCarRef 1;
BA_ "GenSigSNA" SG_ 723 UI_solarAzimuthAngleCarRef "255";
BA_ "Confidence" SG_ 723 UI_isSunUp 0;
BA_ "GenSigSNA" SG_ 723 UI_isSunUp "3";
BA_ "Confidence" SG_ 723 UI_solarElevationAngle 0;
BA_ "GenSigSNA" SG_ 723 UI_solarElevationAngle "127";
BA_ "Confidence" SG_ 723 UI_screenPCBTemperature 0;
BA_ "Confidence" SG_ 723 UI_minsToSunset 0;
BA_ "Confidence" SG_ 723 UI_minsToSunrise 0;
BA_ "Confidence" SG_ 851 UI_touchActive 0;
BA_ "Confidence" SG_ 851 UI_audioActive 0;
BA_ "Confidence" SG_ 851 UI_cellActive 0;
BA_ "Confidence" SG_ 851 UI_displayReady 0;
BA_ "Confidence" SG_ 851 UI_displayOn 0;
BA_ "Confidence" SG_ 851 UI_wifiActive 0;
BA_ "Confidence" SG_ 851 UI_wifiConnected 0;
BA_ "Confidence" SG_ 851 UI_readyForDrive 0;
BA_ "Confidence" SG_ 851 UI_cellConnected 0;
BA_ "Confidence" SG_ 851 UI_vpnActive 0;
BA_ "Confidence" SG_ 851 UI_autopilotTrial 1;
BA_ "Confidence" SG_ 851 UI_factoryReset 0;
BA_ "GenSigSNA" SG_ 851 UI_factoryReset "0";
BA_ "Confidence" SG_ 851 UI_gpsActive 0;
BA_ "Confidence" SG_ 851 UI_cellNetworkTechnology 0;
BA_ "GenSigSNA" SG_ 851 UI_cellNetworkTechnology "15";
BA_ "Confidence" SG_ 851 UI_cellReceiverPower 1;
BA_ "Confidence" SG_ 851 UI_falseTouchCounter 0;
BA_ "Confidence" SG_ 851 UI_cellSignalBars 0;
BA_ "GenSigSNA" SG_ 851 UI_cellSignalBars "7";
BA_ "Confidence" SG_ 851 UI_trailerModeTelltale 0;
BA_ "Confidence" SG_ 851 UI_pcbTemperature 0;
BA_ "Confidence" SG_ 851 UI_cpuTemperature 0;
BA_ "Confidence" SG_ 991 UI_userActivity 0;
BA_ "Confidence" SG_ 991 UI_activeTouchPoints 0;
BA_ "Confidence" SG_ 991 UI_linkState 0;
BA_ "Confidence" SG_ 991 UI_sentryModeState 1;
BA_ "GenSigSNA" SG_ 991 UI_sentryModeState "6";
BA_ "Confidence" SG_ 991 UI_autopilotSentryRequest 0;
BA_ "Confidence" SG_ 991 UI_mobileAppConnected 0;
BA_ "Confidence" SG_ 991 UI_autoshiftDRState 0;
BA_ "Confidence" SG_ 991 UI_wifiBtModuleType 0;
BA_ "Confidence" SG_ 991 UI_sohHealthStatus 1;
BA_ "Confidence" SG_ 991 UI_selfParkState 0;
BA_ "GenSigSNA" SG_ 991 UI_selfParkState "255";
BA_ "Confidence" SG_ 991 UI_summonDeviceIndex 0;
BA_ "Confidence" SG_ 663 UI_adaptiveRideRequest 0;
BA_ "Confidence" SG_ 663 UI_suspensionLoweringRequest 1;
BA_ "GenSigSNA" SG_ 663 UI_suspensionLoweringRequest "3";
BA_ "Confidence" SG_ 663 UI_geofenceLevelingRequest 0;
BA_ "GenSigSNA" SG_ 663 UI_geofenceLevelingRequest "5";
BA_ "Confidence" SG_ 663 UI_jackModeToggleRequest 1;
BA_ "Confidence" SG_ 663 UI_adaptiveTuningRequest0 1;
BA_ "Confidence" SG_ 663 UI_adaptiveTuningRequest1 1;
BA_ "Confidence" SG_ 663 UI_roadRoughnessLookahead 1;
BA_ "GenSigSNA" SG_ 663 UI_roadRoughnessLookahead "127";
BA_ "Confidence" SG_ 663 UI_roadRoughnessStart 1;
BA_ "GenSigSNA" SG_ 663 UI_roadRoughnessStart "31";
BA_ "Confidence" SG_ 663 UI_mapVersionUsed 1;
BA_ "GenSigSNA" SG_ 663 UI_mapVersionUsed "255";
BA_ "Confidence" SG_ 663 UI_suspensionLevelRequest 1;
BA_ "Confidence" SG_ 956 UI_setRCPFront 1;
BA_ "Confidence" SG_ 956 UI_setRCPRear 1;
BA_ "Confidence" SG_ 787 UI_trackModeRequest 0;
BA_ "Confidence" SG_ 787 UI_trackRotationTendency 1;
BA_ "Confidence" SG_ 787 UI_trackStabilityAssist 1;
BA_ "Confidence" SG_ 787 UI_trackPostCooling 1;
BA_ "Confidence" SG_ 787 UI_trackCmpOverclock 1;
BA_ "Confidence" SG_ 787 UI_trackModeBrakeTemps 1;
BA_ "Confidence" SG_ 787 UI_trackDrivePowerAvailability 0;
BA_ "Confidence" SG_ 839 UI_tripPlanningActive 0;
BA_ "Confidence" SG_ 839 UI_navToSupercharger 0;
BA_ "Confidence" SG_ 839 UI_navFastchargerType 0;
BA_ "Confidence" SG_ 839 UI_battPreconditionOnNavState 0;
BA_ "Confidence" SG_ 839 UI_requestActiveBatteryHeating 0;
BA_ "Confidence" SG_ 839 UI_battPreconditionOnNavPowerReq 0;
BA_ "GenSigSNA" SG_ 839 UI_battPreconditionOnNavPowerReq "127";
BA_ "Confidence" SG_ 839 UI_battPreconditionOnNavTargetT 0;
BA_ "GenSigSNA" SG_ 839 UI_battPreconditionOnNavTargetT "255";
BA_ "Confidence" SG_ 839 UI_ambientTempAtDestination 1;
BA_ "GenSigSNA" SG_ 839 UI_ambientTempAtDestination "128";
BA_ "Confidence" SG_ 839 UI_energyAtDestination 0;
BA_ "GenSigSNA" SG_ 839 UI_energyAtDestination "32768";
BA_ "Confidence" SG_ 627 UI_powerStateRequest 0;
BA_ "Confidence" SG_ 627 UI_childDoorLockOnRight 0;
BA_ "Confidence" SG_ 627 UI_frontFogSwitch 0;
BA_ "Confidence" SG_ 627 UI_summonActive 0;
BA_ "Confidence" SG_ 627 UI_frunkRequest 0;
BA_ "Confidence" SG_ 627 UI_wiperMode 0;
BA_ "GenSigSNA" SG_ 627 UI_wiperMode "0";
BA_ "Confidence" SG_ 627 UI_steeringBacklightEnabled 1;
BA_ "Confidence" SG_ 627 UI_steeringButtonMode 0;
BA_ "Confidence" SG_ 627 UI_walkUpUnlock 0;
BA_ "Confidence" SG_ 627 UI_walkAwayLock 0;
BA_ "Confidence" SG_ 627 UI_unlockOnPark 0;
BA_ "Confidence" SG_ 627 UI_globalUnlockOn 0;
BA_ "Confidence" SG_ 627 UI_childDoorLockOnLeft 0;
BA_ "Confidence" SG_ 627 UI_lockRequest 0;
BA_ "GenSigSNA" SG_ 627 UI_lockRequest "7";
BA_ "Confidence" SG_ 627 UI_alarmEnabled 0;
BA_ "Confidence" SG_ 627 UI_stop12vSupport 0;
BA_ "Confidence" SG_ 627 UI_rearFogSwitch 0;
BA_ "Confidence" SG_ 627 UI_mirrorFoldRequest 0;
BA_ "GenSigSNA" SG_ 627 UI_mirrorFoldRequest "3";
BA_ "Confidence" SG_ 627 UI_mirrorHeatRequest 0;
BA_ "Confidence" SG_ 627 UI_remoteStartRequest 0;
BA_ "GenSigSNA" SG_ 627 UI_remoteStartRequest "4";
BA_ "Confidence" SG_ 627 UI_seeYouHomeLightingOn 0;
BA_ "Confidence" SG_ 627 UI_powerOff 0;
BA_ "Confidence" SG_ 627 UI_displayBrightnessLevel 0;
BA_ "GenSigSNA" SG_ 627 UI_displayBrightnessLevel "255";
BA_ "Confidence" SG_ 627 UI_autoHighBeamEnabled 0;
BA_ "Confidence" SG_ 627 UI_frontLeftSeatHeatReq 0;
BA_ "Confidence" SG_ 627 UI_frontRightSeatHeatReq 0;
BA_ "Confidence" SG_ 627 UI_rearLeftSeatHeatReq 0;
BA_ "Confidence" SG_ 627 UI_rearCenterSeatHeatReq 0;
BA_ "Confidence" SG_ 627 UI_rearRightSeatHeatReq 0;
BA_ "Confidence" SG_ 627 UI_autoFoldMirrorsOn 0;
BA_ "Confidence" SG_ 627 UI_mirrorDipOnReverse 0;
BA_ "Confidence" SG_ 627 UI_remoteClosureRequest 0;
BA_ "GenSigSNA" SG_ 627 UI_remoteClosureRequest "3";
BA_ "Confidence" SG_ 627 UI_wiperRequest 0;
BA_ "GenSigSNA" SG_ 627 UI_wiperRequest "0";
BA_ "Confidence" SG_ 627 UI_domeLightSwitch 0;
BA_ "Confidence" SG_ 627 UI_driveStateRequest 1;
BA_ "Confidence" SG_ 947 UI_gloveboxRequest 0;
BA_ "Confidence" SG_ 947 UI_trunkRequest 0;
BA_ "Confidence" SG_ 947 UI_PINToDriveEnabled 0;
BA_ "Confidence" SG_ 947 UI_PINToDrivePassed 0;
BA_ "Confidence" SG_ 947 UI_disableMirrorAutoDim 0;
BA_ "Confidence" SG_ 947 UI_lightSwitch 0;
BA_ "GenSigSNA" SG_ 947 UI_lightSwitch "4";
BA_ "Confidence" SG_ 947 UI_readyToAddKey 0;
BA_ "Confidence" SG_ 947 UI_alarmTriggerRequest 0;
BA_ "Confidence" SG_ 947 UI_summonState 1;
BA_ "GenSigSNA" SG_ 947 UI_summonState "0";
BA_ "Confidence" SG_ 947 UI_displayOnForUser 0;
BA_ "Confidence" SG_ 947 UI_BLEPushNotificationRequest 0;
BA_ "Confidence" SG_ 947 UI_keepAutopilotAwake 0;
BA_ "Confidence" SG_ 947 UI_batteryPreconditioningRequest 0;
BA_ "Confidence" SG_ 947 UI_autopilotPowerStateRequest 0;
BA_ "Confidence" SG_ 947 UI_shorted12VCellTestMode 1;
BA_ "Confidence" SG_ 947 UI_autoRollWindowsOnLockEnable 0;
BA_ "SystemSignalLongSymbol" SG_ 947 UI_virtualPitchSensorOverrideOKF "UI_virtualPitchSensorOverrideOKForAim";
BA_ "SystemSignalLongSymbol" SG_ 947 UI_conditionalLoggingEnabledVCSE "UI_conditionalLoggingEnabledVCSEC";
BA_ "Confidence" SG_ 947 UI_steeringWheelHeatReq 0;
BA_ "Confidence" SG_ 947 UI_disableHorn 0;
BA_ "Confidence" SG_ 947 UI_frontLeftSeatFanReq 0;
BA_ "Confidence" SG_ 947 UI_frontRightSeatAutoClimateReq 0;
BA_ "Confidence" SG_ 947 UI_frontRightSeatFanReq 0;
BA_ "Confidence" SG_ 947 UI_dcr12VThreshold 1;
BA_ "Confidence" SG_ 947 UI_frontLeftSeatAutoClimateReq 0;
BA_ "Confidence" SG_ 947 UI_wiperHeaterReq 0;
BA_ "Confidence" SG_ 947 UI_tireSeason 1;
BA_ "Confidence" SG_ 947 UI_saveTireConfigReq 1;
BA_ "Confidence" SG_ 947 UI_silentAlarm 0;
BA_ "Confidence" SG_ 660 UI_lightFlashRequest 0;
BA_ "Confidence" SG_ 660 UI_phoneCallActive 0;
BA_ "Confidence" SG_ 660 UI_drivingSideVEH 1;
BA_ "Confidence" SG_ 660 UI_keyPairResponse 1;
BA_ "Confidence" SG_ 660 UI_lightShowClosuresEnabled 0;
BA_ "Confidence" SG_ 660 UI_steeringWheelHeatAutoReq 0;
BA_ "Confidence" SG_ 660 UI_steeringWheelHeatLevelReq 0;
BA_ "Confidence" SG_ 660 UI_headlightPulseRequest 0;
BA_ "Confidence" SG_ 660 UI_packTempLoggingRequest 1;
BA_ "Confidence" SG_ 660 UI_displayRedShiftActive 0;
BA_ "Confidence" SG_ 660 UI_fasciaCameraWashRequest 0;
BA_ "Confidence" SG_ 660 UI_leftRearSeatAdjustmentRequest 0;
BA_ "Confidence" SG_ 660 UI_rightRearSeatAdjustmentReques 0;
BA_ "SystemSignalLongSymbol" SG_ 660 UI_rightRearSeatAdjustmentReques "UI_rightRearSeatAdjustmentRequest";
BA_ "Confidence" SG_ 660 UI_blindSpotIndicatorLightReques 0;
BA_ "SystemSignalLongSymbol" SG_ 660 UI_blindSpotIndicatorLightReques "UI_blindSpotIndicatorLightRequest";
BA_ "Confidence" SG_ 660 UI_etcBluetoothControl 1;
BA_ "Confidence" SG_ 660 UI_keepOnAccessoryPortsReq 0;
BA_ "Confidence" SG_ 660 UI_fasciaCameraShown 0;
BA_ "Confidence" SG_ 660 UI_rearSeatChildLock 0;
BA_ "Confidence" SG_ 660 UI_windowPercentageRequest 0;
BA_ "Confidence" SG_ 660 UI_windowRequestedFL 0;
BA_ "Confidence" SG_ 660 UI_windowRequestedFR 0;
BA_ "Confidence" SG_ 660 UI_windowRequestedRL 0;
BA_ "Confidence" SG_ 660 UI_windowRequestedRR 0;
BA_ "Confidence" SG_ 660 UI_windowRequest 0;
BA_ "Confidence" SG_ 660 UI_closeTrunkRequest 0;
BA_ "Confidence" SG_ 660 UI_childPresenceDetectionDisable 0;
BA_ "SystemSignalLongSymbol" SG_ 660 UI_childPresenceDetectionDisable "UI_childPresenceDetectionDisableRequest";
BA_ "Confidence" SG_ 660 UI_derivedLoadshedFeature 0;
BA_ "SystemSignalLongSymbol" SG_ 660 UI_leftRearSeatRequestFromRearDi "UI_leftRearSeatRequestFromRearDisplay";
BA_ "Confidence" SG_ 660 UI_selfParkStandingBy 0;
BA_ "SystemSignalLongSymbol" SG_ 660 UI_rightRearSeatRequestFromRearD "UI_rightRearSeatRequestFromRearDisplay";
BA_ "Confidence" SG_ 853 UI_coolantFlowRequest 0;
BA_ "Confidence" SG_ 853 UI_inletActiveCoolTarget 0;
BA_ "Confidence" SG_ 853 UI_disableHVPTThermalLoads 0;
BA_ "SystemSignalLongSymbol" SG_ 853 UI_enableCOP1CabinHeatingBattery "UI_enableCOP1CabinHeatingBatteryHeating";
BA_ "SystemSignalLongSymbol" SG_ 853 UI_enableUserFacingLowFlowDelive "UI_enableUserFacingLowFlowDeliveryAlert";
BA_ "Confidence" SG_ 853 UI_geofencedLiftgateHeight 1;
BA_ "GenSigSNA" SG_ 853 UI_geofencedLiftgateHeight "255";
BA_ "SystemSignalLongSymbol" SG_ 853 UI_enableConservativeBatteryHeat "UI_enableConservativeBatteryHeating";
BA_ "Confidence" SG_ 644 UI_factoryMode 1;
BA_ "Confidence" SG_ 644 UI_transportMode 0;
BA_ "Confidence" SG_ 644 UI_showroomMode 0;
BA_ "Confidence" SG_ 644 UI_serviceMode 0;
BA_ "Confidence" SG_ 644 UI_carWashMode 0;
BA_ "Confidence" SG_ 644 UI_gameMode 0;
BA_ "Confidence" SG_ 644 UI_diagnosticsAllowed 1;
BA_ "Confidence" SG_ 644 UI_serviceModePlus 0;
BA_ "Confidence" SG_ 644 UI_premiumAmpPowerOff 0;
BA_ "Confidence" SG_ 644 UI_signedCmdHardLocked 1;
BA_ "Confidence" SG_ 644 UI_signedCmdServiceMode 1;
BA_ "Confidence" SG_ 644 UI_closureEasterEggStatus 1;
BA_ "Confidence" SG_ 644 UI_lightShowType 0;
BA_ "Confidence" SG_ 595 UI_ventPanelControlRequestIndex 1;
BA_ "Confidence" SG_ 595 UI_ventPanelLeftPositionX 0;
BA_ "Confidence" SG_ 595 UI_ventPanelLeftPositionY 0;
BA_ "Confidence" SG_ 595 UI_ventPanelLeftLateralSplit 0;
BA_ "Confidence" SG_ 595 UI_ventPanelRightPositionX 0;
BA_ "Confidence" SG_ 595 UI_ventPanelRightPositionY 0;
BA_ "Confidence" SG_ 595 UI_ventPanelRightLateralSplit 0;
BA_ "Confidence" SG_ 595 UI_ventPanelLeftLateralMode 0;
BA_ "Confidence" SG_ 595 UI_ventPanelRightLateralMode 0;
BA_ "Confidence" SG_ 595 UI_hvacReqActiveVents 0;
BA_ "Confidence" SG_ 595 UI_vent2RLeftPositionX 0;
BA_ "Confidence" SG_ 595 UI_vent2RLeftPositionY 0;
BA_ "Confidence" SG_ 595 UI_vent2RRightPositionX 0;
BA_ "Confidence" SG_ 595 UI_vent2RRightPositionY 0;
BA_ "Confidence" SG_ 1565 UI_weatherSvcTimeSinceLast 1;
BA_ "GenSigSNA" SG_ 1565 UI_weatherSvcTimeSinceLast "2047";
BA_ "Confidence" SG_ 1565 UI_weatherSvcTemperature 1;
BA_ "GenSigSNA" SG_ 1565 UI_weatherSvcTemperature "127";
BA_ "Confidence" SG_ 1565 UI_weatherSvcHumidity 1;
BA_ "GenSigSNA" SG_ 1565 UI_weatherSvcHumidity "255";
BA_ "Confidence" SG_ 1565 UI_weatherSvcDewPoint 1;
BA_ "GenSigSNA" SG_ 1565 UI_weatherSvcDewPoint "255";
BA_ "Confidence" SG_ 1565 UI_weatherSvcCloudCover 1;
BA_ "GenSigSNA" SG_ 1565 UI_weatherSvcCloudCover "255";
BA_ "Confidence" SG_ 1533 UMC_alertID 1;
BA_ "Confidence" SG_ 1533 UMC_alertType 1;
BA_ "Confidence" SG_ 1533 UMC_a001_groundImpedance 1;
BA_ "Confidence" SG_ 1533 UMC_a002_ccidRmsCurrent 1;
BA_ "Confidence" SG_ 1533 UMC_a002_ccidRmsCurrentAvg 1;
BA_ "Confidence" SG_ 1533 UMC_a002_ccidFaultReason 1;
BA_ "GenSigSNA" SG_ 1533 UMC_a002_ccidFaultReason "0";
BA_ "Confidence" SG_ 1533 UMC_a003_faultType 1;
BA_ "Confidence" SG_ 1533 UMC_a003_ccidSelfTestDuty 1;
BA_ "Confidence" SG_ 1533 UMC_a003_ccidSelfTestCurrent 1;
BA_ "Confidence" SG_ 1533 UMC_a004_lineVoltage 1;
BA_ "Confidence" SG_ 1533 UMC_a004_inputVoltage 1;
BA_ "Confidence" SG_ 1533 UMC_a004_inputNeutralVoltage 1;
BA_ "Confidence" SG_ 1533 UMC_a005_lineVoltage 1;
BA_ "Confidence" SG_ 1533 UMC_a005_inputVoltage 1;
BA_ "Confidence" SG_ 1533 UMC_a005_inputNeutralVoltage 1;
BA_ "Confidence" SG_ 1533 UMC_a006_outputVoltage 1;
BA_ "Confidence" SG_ 1533 UMC_a006_faultType 1;
BA_ "Confidence" SG_ 1533 UMC_a006_umcReceptacleVoltage 1;
BA_ "Confidence" SG_ 1533 UMC_a006_handleVoltage 1;
BA_ "Confidence" SG_ 1533 UMC_a007_pcbaTemp 1;
BA_ "Confidence" SG_ 1533 UMC_a008_wallPlugTemp 1;
BA_ "Confidence" SG_ 1533 UMC_a008_SA_current 1;
BA_ "Confidence" SG_ 1533 UMC_a009_vehConnTemp 1;
BA_ "Confidence" SG_ 1533 UMC_a010_inputTerminalsTemp 1;
BA_ "Confidence" SG_ 1533 UMC_a012_pilotHigh 1;
BA_ "Confidence" SG_ 1533 UMC_a012_pilotLow 1;
BA_ "Confidence" SG_ 1533 UMC_a013_SA_current 1;
BA_ "Confidence" SG_ 1533 UMC_a015_SA_current 1;
BA_ "Confidence" SG_ 1533 UMC_a016_pcbaTemp 1;
BA_ "Confidence" SG_ 1533 UMC_a017_wallPlugTemp 1;
BA_ "Confidence" SG_ 1533 UMC_a017_SA_current 1;
BA_ "Confidence" SG_ 1533 UMC_a018_vehConnTemp 1;
BA_ "Confidence" SG_ 1533 UMC_a019_inputTerminalsTemp 1;
BA_ "Confidence" SG_ 1533 UMC_a024_groundImpedance 1;
BA_ "Confidence" SG_ 1533 UMC_a040_groundImpedance 1;
BA_ "Confidence" SG_ 1285 SA_infoIndex 1;
BA_ "Confidence" SG_ 1285 SA_genealogyVersion 0;
BA_ "Confidence" SG_ 1285 SA_genealogyCrc 0;
BA_ "Confidence" SG_ 1285 SA_region 0;
BA_ "Confidence" SG_ 1285 SA_OverTempThreshold 0;
BA_ "Confidence" SG_ 1285 SA_partNumInt 0;
BA_ "Confidence" SG_ 1285 SA_partNumRev 0;
BA_ "Confidence" SG_ 1285 SA_currentLimit 0;
BA_ "Confidence" SG_ 1285 SA_l1Voltage 0;
BA_ "Confidence" SG_ 609 VCFRONT_12VBatteryStatusIndex 1;
BA_ "Confidence" SG_ 609 VCFRONT_good12VforUpdate 0;
BA_ "Confidence" SG_ 609 VCFRONT_LVLoadRequest 0;
BA_ "Confidence" SG_ 609 VCFRONT_12VBatteryStatusCounter 0;
BA_ "Confidence" SG_ 609 VCFRONT_12VBatteryStatusChecksum 0;
BA_ "Confidence" SG_ 609 VCFRONT_batterySupportRequest 0;
BA_ "Confidence" SG_ 609 VCFRONT_batterySMState 0;
BA_ "Confidence" SG_ 609 VCFRONT_eFuseRecoveryStateDBG 0;
BA_ "Confidence" SG_ 609 VCFRONT_batteryLINScheduleDBG 0;
BA_ "GenSigSNA" SG_ 609 VCFRONT_batteryLINScheduleDBG "7";
BA_ "Confidence" SG_ 609 VCFRONT_resistanceEstimationTest 0;
BA_ "SystemSignalLongSymbol" SG_ 609 VCFRONT_resistanceEstimationTest "VCFRONT_resistanceEstimationTestCounter";
BA_ "Confidence" SG_ 609 VCFRONT_IBSCurrent 0;
BA_ "Confidence" SG_ 609 VCFRONT_IBSVoltage 0;
BA_ "GenSigSNA" SG_ 609 VCFRONT_IBSVoltage "4095";
BA_ "Confidence" SG_ 609 VCFRONT_reverseBatteryFault 0;
BA_ "Confidence" SG_ 609 VCFRONT_LVBatterySupported 0;
BA_ "Confidence" SG_ 609 VCFRONT_LVBatteryCannotSupportVe 0;
BA_ "SystemSignalLongSymbol" SG_ 609 VCFRONT_LVBatteryCannotSupportVe "VCFRONT_LVBatteryCannotSupportVehicle";
BA_ "Confidence" SG_ 609 VCFRONT_goodTemp12VforUpdate 0;
BA_ "Confidence" SG_ 609 VCFRONT_12VBatteryTargetVoltage 0;
BA_ "Confidence" SG_ 609 VCFRONT_IBSTemperature 0;
BA_ "GenSigSNA" SG_ 609 VCFRONT_IBSTemperature "2047";
BA_ "Confidence" SG_ 609 VCFRONT_currentSensorMismatchLea 0;
BA_ "SystemSignalLongSymbol" SG_ 609 VCFRONT_currentSensorMismatchLea "VCFRONT_currentSensorMismatchLeakyBktPctDBG";
BA_ "Confidence" SG_ 609 VCFRONT_LVBatteryEnergyRemaining 0;
BA_ "SystemSignalLongSymbol" SG_ 609 VCFRONT_LVBatteryEnergyRemaining "VCFRONT_LVBatteryEnergyRemainingPCT";
BA_ "Confidence" SG_ 609 VCFRONT_LVBatteryStatusForDrive 0;
BA_ "Confidence" SG_ 609 VCFRONT_LVBatteryType 0;
BA_ "Confidence" SG_ 609 VCFRONT_resistanceEstimationNeed 0;
BA_ "SystemSignalLongSymbol" SG_ 609 VCFRONT_resistanceEstimationNeed "VCFRONT_resistanceEstimationNeeded";
BA_ "Confidence" SG_ 609 VCFRONT_IBSVoltageFiltered 0;
BA_ "GenSigSNA" SG_ 609 VCFRONT_IBSVoltageFiltered "16383";
BA_ "Confidence" SG_ 609 VCFRONT_LVBMS_LVBusVoltageSource 0;
BA_ "SystemSignalLongSymbol" SG_ 609 VCFRONT_LVBMS_LVBusVoltageSource "VCFRONT_LVBMS_LVBusVoltageSourceDBG";
BA_ "Confidence" SG_ 609 VCFRONT_LVBMS_LVPackCurrentSourc 0;
BA_ "SystemSignalLongSymbol" SG_ 609 VCFRONT_LVBMS_LVPackCurrentSourc "VCFRONT_LVBMS_LVPackCurrentSourceDBG";
BA_ "Confidence" SG_ 609 VCFRONT_LVBatterySupportRqrdTrig 0;
BA_ "SystemSignalLongSymbol" SG_ 609 VCFRONT_LVBatterySupportRqrdTrig "VCFRONT_LVBatterySupportRqrdTrigger";
BA_ "Confidence" SG_ 609 VCFRONT_goodForPCSPowerCycleLeak 0;
BA_ "SystemSignalLongSymbol" SG_ 609 VCFRONT_goodForPCSPowerCycleLeak "VCFRONT_goodForPCSPowerCycleLeakyBktDBG";
BA_ "Confidence" SG_ 609 VCFRONT_LVBusControlsFutile 0;
BA_ "Confidence" SG_ 609 VCFRONT_resistanceEstimatio_0001 0;
BA_ "SystemSignalLongSymbol" SG_ 609 VCFRONT_resistanceEstimatio_0001 "VCFRONT_resistanceEstimationTestValid";
BA_ "Confidence" SG_ 609 VCFRONT_resistanceEstimatio_0002 0;
BA_ "SystemSignalLongSymbol" SG_ 609 VCFRONT_resistanceEstimatio_0002 "VCFRONT_resistanceEstimationTestsExpended";
BA_ "Confidence" SG_ 609 VCFRONT_goodLVChargeForUpdate 0;
BA_ "Confidence" SG_ 609 VCFRONT_opportunisticDCRTestNeed 0;
BA_ "SystemSignalLongSymbol" SG_ 609 VCFRONT_opportunisticDCRTestNeed "VCFRONT_opportunisticDCRTestNeeded";
BA_ "Confidence" SG_ 609 VCFRONT_voltageProfile 0;
BA_ "Confidence" SG_ 609 VCFRONT_IBSAmpHours 0;
BA_ "Confidence" SG_ 609 VCFRONT_IBSVoltageRawDBG 0;
BA_ "GenSigSNA" SG_ 609 VCFRONT_IBSVoltageRawDBG "16383";
BA_ "Confidence" SG_ 609 VCFRONT_LVBatteryLINCommsDetecte 0;
BA_ "SystemSignalLongSymbol" SG_ 609 VCFRONT_LVBatteryLINCommsDetecte "VCFRONT_LVBatteryLINCommsDetectedDBG";
BA_ "Confidence" SG_ 609 VCFRONT_voltageSensorMismatchLea 0;
BA_ "SystemSignalLongSymbol" SG_ 609 VCFRONT_voltageSensorMismatchLea "VCFRONT_voltageSensorMismatchLeakyBktPctDBG";
BA_ "Confidence" SG_ 609 VCFRONT_LVBatteryFctryLimOverrid 0;
BA_ "SystemSignalLongSymbol" SG_ 609 VCFRONT_LVBatteryFctryLimOverrid "VCFRONT_LVBatteryFctryLimOverrideOk";
BA_ "Confidence" SG_ 609 VCFRONT_LVBatterySPICommsDetecte 0;
BA_ "SystemSignalLongSymbol" SG_ 609 VCFRONT_LVBatterySPICommsDetecte "VCFRONT_LVBatterySPICommsDetectedDBG";
BA_ "Confidence" SG_ 609 VCFRONT_targetCurrent 0;
BA_ "Confidence" SG_ 609 VCFRONT_PCSMia 0;
BA_ "Confidence" SG_ 609 VCFRONT_chargeNeeded 0;
BA_ "Confidence" SG_ 609 VCFRONT_voltageControlLoopIntegr 0;
BA_ "SystemSignalLongSymbol" SG_ 609 VCFRONT_voltageControlLoopIntegr "VCFRONT_voltageControlLoopIntegrationVal";
BA_ "Confidence" SG_ 609 VCFRONT_currentControlLoopIntegr 0;
BA_ "SystemSignalLongSymbol" SG_ 609 VCFRONT_currentControlLoopIntegr "VCFRONT_currentControlLoopIntegrationVal";
BA_ "Confidence" SG_ 1847 VCFRONT_LVBMS_InfoIndex 1;
BA_ "Confidence" SG_ 1847 VCFRONT_LVBMS_PcbaId 0;
BA_ "Confidence" SG_ 1847 VCFRONT_LVBMS_AssemblyId 0;
BA_ "Confidence" SG_ 1847 VCFRONT_LVBMS_SubUsageId 0;
BA_ "GenSigSNA" SG_ 1847 VCFRONT_LVBMS_SubUsageId "65535";
BA_ "Confidence" SG_ 1847 VCFRONT_LVBMS_UsageId 0;
BA_ "Confidence" SG_ 1847 VCFRONT_LVBMS_AppCRC 0;
BA_ "Confidence" SG_ 1847 VCFRONT_LVBMS_FWBuildType 0;
BA_ "Confidence" SG_ 1140 VCFRONT_LVHealthStatus 1;
BA_ "Confidence" SG_ 1140 VCFRONT_LVStatusForDrive 1;
BA_ "Confidence" SG_ 1140 VCFRONT_LVPowerSecondsToSafeHarb 1;
BA_ "SystemSignalLongSymbol" SG_ 1140 VCFRONT_LVPowerSecondsToSafeHarb "VCFRONT_LVPowerSecondsToSafeHarbor";
BA_ "Confidence" SG_ 1173 VCFRONT_LVHealthDebugIndex 1;
BA_ "Confidence" SG_ 1173 VCFRONT_LVHEALTH_placeholder 0;
BA_ "Confidence" SG_ 1173 VCFRONT_LVHEALTH_activeDecelEner 0;
BA_ "SystemSignalLongSymbol" SG_ 1173 VCFRONT_LVHEALTH_activeDecelEner "VCFRONT_LVHEALTH_activeDecelEnergyWarning";
BA_ "Confidence" SG_ 1173 VCFRONT_LVHEALTH_criticalPullove 0;
BA_ "SystemSignalLongSymbol" SG_ 1173 VCFRONT_LVHEALTH_criticalPullove "VCFRONT_LVHEALTH_criticalPulloverEnergyWarning";
BA_ "Confidence" SG_ 1173 VCFRONT_LVHEALTH_revBattEFuseOff 0;
BA_ "Confidence" SG_ 1173 VCFRONT_LVHEALTH_LVBMBEFuseOpen 0;
BA_ "Confidence" SG_ 1173 VCFRONT_LVHEALTH_lvBatteryCommsM 0;
BA_ "SystemSignalLongSymbol" SG_ 1173 VCFRONT_LVHEALTH_lvBatteryCommsM "VCFRONT_LVHEALTH_lvBatteryCommsMia";
BA_ "Confidence" SG_ 1173 VCFRONT_LVHEALTH_pcsEFuseOff 0;
BA_ "Confidence" SG_ 1173 VCFRONT_LVHEALTH_pcsNotActive 0;
BA_ "Confidence" SG_ 1173 VCFRONT_LVHEALTH_pcsMIA 0;
BA_ "Confidence" SG_ 1173 VCFRONT_LVHEALTH_IBSMIA 0;
BA_ "Confidence" SG_ 1173 VCFRONT_LVHEALTH_LVBatteryElecDi 0;
BA_ "SystemSignalLongSymbol" SG_ 1173 VCFRONT_LVHEALTH_LVBatteryElecDi "VCFRONT_LVHEALTH_LVBatteryElecDisc";
BA_ "Confidence" SG_ 1173 VCFRONT_LVHEALTH_LVBatteryE_0001 0;
BA_ "SystemSignalLongSymbol" SG_ 1173 VCFRONT_LVHEALTH_LVBatteryE_0001 "VCFRONT_LVHEALTH_LVBatteryElecDiscUnknown";
BA_ "Confidence" SG_ 1173 VCFRONT_LVHEALTH_pcsOpenCircuit 0;
BA_ "Confidence" SG_ 1173 VCFRONT_LVHEALTH_activeDecelPowe 0;
BA_ "SystemSignalLongSymbol" SG_ 1173 VCFRONT_LVHEALTH_activeDecelPowe "VCFRONT_LVHEALTH_activeDecelPowerWarning";
BA_ "Confidence" SG_ 1173 VCFRONT_LVHEALTH_lvBatteryCapabi 0;
BA_ "SystemSignalLongSymbol" SG_ 1173 VCFRONT_LVHEALTH_lvBatteryCapabi "VCFRONT_LVHEALTH_lvBatteryCapabilityLowAccuracy";
BA_ "Confidence" SG_ 1173 VCFRONT_LVHEALTH_lvBatteryConfig 0;
BA_ "SystemSignalLongSymbol" SG_ 1173 VCFRONT_LVHEALTH_lvBatteryConfig "VCFRONT_LVHEALTH_lvBatteryConfiguration";
BA_ "Confidence" SG_ 1173 VCFRONT_LVHEALTH_lvBatteryImpeda 0;
BA_ "SystemSignalLongSymbol" SG_ 1173 VCFRONT_LVHEALTH_lvBatteryImpeda "VCFRONT_LVHEALTH_lvBatteryImpedance";
BA_ "Confidence" SG_ 545 VCFRONT_LVPowerStateIndex 1;
BA_ "Confidence" SG_ 545 VCFRONT_vehiclePowerState 0;
BA_ "Confidence" SG_ 545 VCFRONT_inAccessoryPlus 0;
BA_ "Confidence" SG_ 545 VCFRONT_LVShuttingDown 0;
BA_ "Confidence" SG_ 545 VCFRONT_LVPowerStateCounter 0;
BA_ "Confidence" SG_ 545 VCFRONT_LVPowerStateChecksum 0;
BA_ "Confidence" SG_ 545 VCFRONT_cpLVRequest 0;
BA_ "Confidence" SG_ 545 VCFRONT_epasLVState 0;
BA_ "Confidence" SG_ 545 VCFRONT_hvcLVRequest 0;
BA_ "Confidence" SG_ 545 VCFRONT_tasLVState 0;
BA_ "Confidence" SG_ 545 VCFRONT_pcsLVState 0;
BA_ "Confidence" SG_ 545 VCFRONT_CMPDLVState 0;
BA_ "Confidence" SG_ 545 VCFRONT_hcmlLVState 0;
BA_ "Confidence" SG_ 545 VCFRONT_hcmrLVState 0;
BA_ "Confidence" SG_ 545 VCFRONT_MCUAudioLVState 0;
BA_ "Confidence" SG_ 545 VCFRONT_espValveLVState 0;
BA_ "Confidence" SG_ 545 VCFRONT_MCUGraphicsLVState 0;
BA_ "Confidence" SG_ 545 VC_dcdcSupportRequest 0;
BA_ "Confidence" SG_ 545 VC_hvStateRequest 0;
BA_ "Confidence" SG_ 545 VC_persistAccPowerRequestOverrid 0;
BA_ "SystemSignalLongSymbol" SG_ 545 VC_persistAccPowerRequestOverrid "VC_persistAccPowerRequestOverridden";
BA_ "Confidence" SG_ 545 VC_accPortPowerRequest 0;
BA_ "Confidence" SG_ 545 VC_persistAccPortPowerState 0;
BA_ "Confidence" SG_ 700 VCFRONT_LVThermalMotorsIndex 1;
BA_ "Confidence" SG_ 700 VCFRONT_radiatorFanState 0;
BA_ "Confidence" SG_ 700 VCFRONT_radiatorFanTorque 0;
BA_ "GenSigSNA" SG_ 700 VCFRONT_radiatorFanTorque "1023";
BA_ "Confidence" SG_ 700 VCFRONT_radiatorFanIDc 0;
BA_ "GenSigSNA" SG_ 700 VCFRONT_radiatorFanIDc "127";
BA_ "Confidence" SG_ 700 VCFRONT_mlxLINCurrentSchedule 0;
BA_ "Confidence" SG_ 700 VCFRONT_pumpPowertrainState 0;
BA_ "Confidence" SG_ 700 VCFRONT_pumpPowertrainTorque 0;
BA_ "GenSigSNA" SG_ 700 VCFRONT_pumpPowertrainTorque "1023";
BA_ "Confidence" SG_ 700 VCFRONT_pumpPowertrainIDc 0;
BA_ "GenSigSNA" SG_ 700 VCFRONT_pumpPowertrainIDc "127";
BA_ "Confidence" SG_ 700 VCFRONT_pumpBatteryState 0;
BA_ "Confidence" SG_ 700 VCFRONT_pumpBatteryTorque 0;
BA_ "GenSigSNA" SG_ 700 VCFRONT_pumpBatteryTorque "1023";
BA_ "Confidence" SG_ 700 VCFRONT_pumpBatteryIDc 0;
BA_ "GenSigSNA" SG_ 700 VCFRONT_pumpBatteryIDc "127";
BA_ "Confidence" SG_ 1332 VCFRONT_alertID 1;
BA_ "Confidence" SG_ 1332 VCFRONT_alertState 1;
BA_ "SystemSignalLongSymbol" SG_ 1332 VCFRONT_a004_APPWatchdogFaultOrM "VCFRONT_a004_APPWatchdogFaultOrMIA";
BA_ "SystemSignalLongSymbol" SG_ 1332 VCFRONT_a004_DASHighLowBeamDecis "VCFRONT_a004_DASHighLowBeamDecisionSNA";
BA_ "SystemSignalLongSymbol" SG_ 1332 VCFRONT_a004_DASAdaptiveHighBeam "VCFRONT_a004_DASAdaptiveHighBeamFault";
BA_ "SystemSignalLongSymbol" SG_ 1332 VCFRONT_a004_DASMatrixColumnMsgM "VCFRONT_a004_DASMatrixColumnMsgMIA";
BA_ "SystemSignalLongSymbol" SG_ 1332 VCFRONT_a004_EPAS3PNotInSpecOrMI "VCFRONT_a004_EPAS3PNotInSpecOrMIA";
BA_ "SystemSignalLongSymbol" SG_ 1332 VCFRONT_a008_APPWatchdogFaultOrM "VCFRONT_a008_APPWatchdogFaultOrMIA";
BA_ "SystemSignalLongSymbol" SG_ 1332 VCFRONT_a008_DASHighLowBeamDecis "VCFRONT_a008_DASHighLowBeamDecisionSNA";
BA_ "SystemSignalLongSymbol" SG_ 1332 VCFRONT_a008_DASAdaptiveHighBeam "VCFRONT_a008_DASAdaptiveHighBeamFault";
BA_ "SystemSignalLongSymbol" SG_ 1332 VCFRONT_a008_DASMatrixColumnMsgM "VCFRONT_a008_DASMatrixColumnMsgMIA";
BA_ "SystemSignalLongSymbol" SG_ 1332 VCFRONT_a008_EPAS3PNotInSpecOrMI "VCFRONT_a008_EPAS3PNotInSpecOrMIA";
BA_ "SystemSignalLongSymbol" SG_ 1332 VCFRONT_a010_UnderVoltageDetecte "VCFRONT_a010_UnderVoltageDetected";
BA_ "Confidence" SG_ 1332 VCFRONT_a059_voltageDrop 1;
BA_ "Confidence" SG_ 1332 VCFRONT_a059_resistanceEstimate 1;
BA_ "Confidence" SG_ 1332 VCFRONT_a059_current 1;
BA_ "Confidence" SG_ 1332 VCFRONT_a063_ADCVoltage 1;
BA_ "SystemSignalLongSymbol" SG_ 1332 VCFRONT_a082_RIPC_epbPrivateStat "VCFRONT_a082_RIPC_epbPrivateState";
BA_ "SystemSignalLongSymbol" SG_ 1332 VCFRONT_a083_LIPC_epbPrivateStat "VCFRONT_a083_LIPC_epbPrivateState";
BA_ "SystemSignalLongSymbol" SG_ 1332 VCFRONT_a086_VEH_LVBMS_statusHig "VCFRONT_a086_VEH_LVBMS_statusHigh";
BA_ "SystemSignalLongSymbol" SG_ 1332 VCFRONT_a086_VEH_12VBatteryStatu "VCFRONT_a086_VEH_12VBatteryStatus";
BA_ "SystemSignalLongSymbol" SG_ 1332 VCFRONT_a087_PARTY_thermalContro "VCFRONT_a087_PARTY_thermalControl";
BA_ "SystemSignalLongSymbol" SG_ 1332 VCFRONT_a088_PARTY_thermalContro "VCFRONT_a088_PARTY_thermalControl";
VAL_ 1523 UI_odometer 16777215 "SNA" ;
VAL_ 948 UI_usbFrontHubPowerStateRequest 2 "POWER_ON" 1 "POWER_NO_PREFERENCE" 0 "POWER_REQUEST_SNA" ;
VAL_ 827 UI_chargeTimeUntilTerminationPct 2047 "SNA" 1440 "MAXVAL" ;
VAL_ 827 UI_chargeTimeUntilReadyToDepart 2047 "SNA" 1440 "MAXVAL" ;
VAL_ 661 UI_powerRationalityConfigIndex 255 "INVALID" 11 "VCRIGHT_DYNAMIC_CURVE_CUTOFF_CONFIG" 10 "VCRIGHT_STATIC_CURVE_CUTOFF_CONFIG" 9 "VCRIGHT_FAST_BLOW_CUTOFF_CONFIG" 8 "VCLEFT_DYNAMIC_CURVE_CUTOFF_CONFIG" 7 "VCLEFT_STATIC_CURVE_CUTOFF_CONFIG" 6 "VCLEFT_FAST_BLOW_CUTOFF_CONFIG" 5 "VCRIGHT_DYNAMIC_CURVE_CONFIG" 4 "VCRIGHT_STATIC_CURVE_CONFIG" 3 "VCRIGHT_FAST_BLOW_CONFIG" 2 "VCLEFT_DYNAMIC_CURVE_CONFIG" 1 "VCLEFT_STATIC_CURVE_CONFIG" 0 "VCLEFT_FAST_BLOW_CONFIG" ;
VAL_ 661 UI_vcleftCfgRationalityThreshold 15 "VC_THRESHOLD_CONFIG_15" 14 "VC_THRESHOLD_CONFIG_14" 13 "VC_THRESHOLD_CONFIG_13" 12 "VC_THRESHOLD_CONFIG_12" 11 "VC_THRESHOLD_CONFIG_11" 10 "VC_THRESHOLD_CONFIG_10" 9 "VC_THRESHOLD_CONFIG_9" 8 "VC_THRESHOLD_CONFIG_8" 7 "VC_THRESHOLD_CONFIG_7" 6 "VC_THRESHOLD_CONFIG_6" 5 "VC_THRESHOLD_CONFIG_5" 4 "VC_THRESHOLD_CONFIG_4" 3 "VC_THRESHOLD_CONFIG_3" 2 "VC_THRESHOLD_CONFIG_2" 1 "VC_THRESHOLD_CONFIG_1" 0 "SNA" ;
VAL_ 661 UI_vcleftCfgRationalityTime0 15 "VC_THRESHOLD_CONFIG_15" 14 "VC_THRESHOLD_CONFIG_14" 13 "VC_THRESHOLD_CONFIG_13" 12 "VC_THRESHOLD_CONFIG_12" 11 "VC_THRESHOLD_CONFIG_11" 10 "VC_THRESHOLD_CONFIG_10" 9 "VC_THRESHOLD_CONFIG_9" 8 "VC_THRESHOLD_CONFIG_8" 7 "VC_THRESHOLD_CONFIG_7" 6 "VC_THRESHOLD_CONFIG_6" 5 "VC_THRESHOLD_CONFIG_5" 4 "VC_THRESHOLD_CONFIG_4" 3 "VC_THRESHOLD_CONFIG_3" 2 "VC_THRESHOLD_CONFIG_2" 1 "VC_THRESHOLD_CONFIG_1" 0 "SNA" ;
VAL_ 661 UI_vcleftCfgRationalityThre_0001 15 "VC_THRESHOLD_CONFIG_15" 14 "VC_THRESHOLD_CONFIG_14" 13 "VC_THRESHOLD_CONFIG_13" 12 "VC_THRESHOLD_CONFIG_12" 11 "VC_THRESHOLD_CONFIG_11" 10 "VC_THRESHOLD_CONFIG_10" 9 "VC_THRESHOLD_CONFIG_9" 8 "VC_THRESHOLD_CONFIG_8" 7 "VC_THRESHOLD_CONFIG_7" 6 "VC_THRESHOLD_CONFIG_6" 5 "VC_THRESHOLD_CONFIG_5" 4 "VC_THRESHOLD_CONFIG_4" 3 "VC_THRESHOLD_CONFIG_3" 2 "VC_THRESHOLD_CONFIG_2" 1 "VC_THRESHOLD_CONFIG_1" 0 "SNA" ;
VAL_ 661 UI_vcleftCfgRationalityTime1 15 "VC_THRESHOLD_CONFIG_15" 14 "VC_THRESHOLD_CONFIG_14" 13 "VC_THRESHOLD_CONFIG_13" 12 "VC_THRESHOLD_CONFIG_12" 11 "VC_THRESHOLD_CONFIG_11" 10 "VC_THRESHOLD_CONFIG_10" 9 "VC_THRESHOLD_CONFIG_9" 8 "VC_THRESHOLD_CONFIG_8" 7 "VC_THRESHOLD_CONFIG_7" 6 "VC_THRESHOLD_CONFIG_6" 5 "VC_THRESHOLD_CONFIG_5" 4 "VC_THRESHOLD_CONFIG_4" 3 "VC_THRESHOLD_CONFIG_3" 2 "VC_THRESHOLD_CONFIG_2" 1 "VC_THRESHOLD_CONFIG_1" 0 "SNA" ;
VAL_ 661 UI_vcleftCfgRationalityStaticA 65535 "SNA" ;
VAL_ 661 UI_vcleftCfgRationalityStaticB -32768 "SNA" ;
VAL_ 661 UI_vcleftCfgRationalityStaticC -32768 "SNA" ;
VAL_ 661 UI_vcleftCfgRationalityDynamicA 65535 "SNA" ;
VAL_ 661 UI_vcleftCfgRationalityDynamicB -32768 "SNA" ;
VAL_ 661 UI_vcleftCfgRationalityDynamicC -32768 "SNA" ;
VAL_ 661 UI_vcrightCfgRationalityThreshol 15 "VC_THRESHOLD_CONFIG_15" 14 "VC_THRESHOLD_CONFIG_14" 13 "VC_THRESHOLD_CONFIG_13" 12 "VC_THRESHOLD_CONFIG_12" 11 "VC_THRESHOLD_CONFIG_11" 10 "VC_THRESHOLD_CONFIG_10" 9 "VC_THRESHOLD_CONFIG_9" 8 "VC_THRESHOLD_CONFIG_8" 7 "VC_THRESHOLD_CONFIG_7" 6 "VC_THRESHOLD_CONFIG_6" 5 "VC_THRESHOLD_CONFIG_5" 4 "VC_THRESHOLD_CONFIG_4" 3 "VC_THRESHOLD_CONFIG_3" 2 "VC_THRESHOLD_CONFIG_2" 1 "VC_THRESHOLD_CONFIG_1" 0 "SNA" ;
VAL_ 661 UI_vcrightCfgRationalityTime0 15 "VC_THRESHOLD_CONFIG_15" 14 "VC_THRESHOLD_CONFIG_14" 13 "VC_THRESHOLD_CONFIG_13" 12 "VC_THRESHOLD_CONFIG_12" 11 "VC_THRESHOLD_CONFIG_11" 10 "VC_THRESHOLD_CONFIG_10" 9 "VC_THRESHOLD_CONFIG_9" 8 "VC_THRESHOLD_CONFIG_8" 7 "VC_THRESHOLD_CONFIG_7" 6 "VC_THRESHOLD_CONFIG_6" 5 "VC_THRESHOLD_CONFIG_5" 4 "VC_THRESHOLD_CONFIG_4" 3 "VC_THRESHOLD_CONFIG_3" 2 "VC_THRESHOLD_CONFIG_2" 1 "VC_THRESHOLD_CONFIG_1" 0 "SNA" ;
VAL_ 661 UI_vcrightCfgRationalityThr_0001 15 "VC_THRESHOLD_CONFIG_15" 14 "VC_THRESHOLD_CONFIG_14" 13 "VC_THRESHOLD_CONFIG_13" 12 "VC_THRESHOLD_CONFIG_12" 11 "VC_THRESHOLD_CONFIG_11" 10 "VC_THRESHOLD_CONFIG_10" 9 "VC_THRESHOLD_CONFIG_9" 8 "VC_THRESHOLD_CONFIG_8" 7 "VC_THRESHOLD_CONFIG_7" 6 "VC_THRESHOLD_CONFIG_6" 5 "VC_THRESHOLD_CONFIG_5" 4 "VC_THRESHOLD_CONFIG_4" 3 "VC_THRESHOLD_CONFIG_3" 2 "VC_THRESHOLD_CONFIG_2" 1 "VC_THRESHOLD_CONFIG_1" 0 "SNA" ;
VAL_ 661 UI_vcrightCfgRationalityTime1 15 "VC_THRESHOLD_CONFIG_15" 14 "VC_THRESHOLD_CONFIG_14" 13 "VC_THRESHOLD_CONFIG_13" 12 "VC_THRESHOLD_CONFIG_12" 11 "VC_THRESHOLD_CONFIG_11" 10 "VC_THRESHOLD_CONFIG_10" 9 "VC_THRESHOLD_CONFIG_9" 8 "VC_THRESHOLD_CONFIG_8" 7 "VC_THRESHOLD_CONFIG_7" 6 "VC_THRESHOLD_CONFIG_6" 5 "VC_THRESHOLD_CONFIG_5" 4 "VC_THRESHOLD_CONFIG_4" 3 "VC_THRESHOLD_CONFIG_3" 2 "VC_THRESHOLD_CONFIG_2" 1 "VC_THRESHOLD_CONFIG_1" 0 "SNA" ;
VAL_ 661 UI_vcrightCfgRationalityStaticA 65535 "SNA" ;
VAL_ 661 UI_vcrightCfgRationalityStaticB -32768 "SNA" ;
VAL_ 661 UI_vcrightCfgRationalityStaticC -32768 "SNA" ;
VAL_ 661 UI_vcrightCfgRationalityDynamicA 65535 "SNA" ;
VAL_ 661 UI_vcrightCfgRationalityDynamicB -32768 "SNA" ;
VAL_ 661 UI_vcrightCfgRationalityDynamicC -32768 "SNA" ;
VAL_ 661 UI_vcleftCfgCutoffThreshold0 15 "VC_THRESHOLD_CONFIG_15" 14 "VC_THRESHOLD_CONFIG_14" 13 "VC_THRESHOLD_CONFIG_13" 12 "VC_THRESHOLD_CONFIG_12" 11 "VC_THRESHOLD_CONFIG_11" 10 "VC_THRESHOLD_CONFIG_10" 9 "VC_THRESHOLD_CONFIG_9" 8 "VC_THRESHOLD_CONFIG_8" 7 "VC_THRESHOLD_CONFIG_7" 6 "VC_THRESHOLD_CONFIG_6" 5 "VC_THRESHOLD_CONFIG_5" 4 "VC_THRESHOLD_CONFIG_4" 3 "VC_THRESHOLD_CONFIG_3" 2 "VC_THRESHOLD_CONFIG_2" 1 "VC_THRESHOLD_CONFIG_1" 0 "SNA" ;
VAL_ 661 UI_vcleftCfgCutoffTime0 15 "VC_THRESHOLD_CONFIG_15" 14 "VC_THRESHOLD_CONFIG_14" 13 "VC_THRESHOLD_CONFIG_13" 12 "VC_THRESHOLD_CONFIG_12" 11 "VC_THRESHOLD_CONFIG_11" 10 "VC_THRESHOLD_CONFIG_10" 9 "VC_THRESHOLD_CONFIG_9" 8 "VC_THRESHOLD_CONFIG_8" 7 "VC_THRESHOLD_CONFIG_7" 6 "VC_THRESHOLD_CONFIG_6" 5 "VC_THRESHOLD_CONFIG_5" 4 "VC_THRESHOLD_CONFIG_4" 3 "VC_THRESHOLD_CONFIG_3" 2 "VC_THRESHOLD_CONFIG_2" 1 "VC_THRESHOLD_CONFIG_1" 0 "SNA" ;
VAL_ 661 UI_vcleftCfgCutoffThreshold1 15 "VC_THRESHOLD_CONFIG_15" 14 "VC_THRESHOLD_CONFIG_14" 13 "VC_THRESHOLD_CONFIG_13" 12 "VC_THRESHOLD_CONFIG_12" 11 "VC_THRESHOLD_CONFIG_11" 10 "VC_THRESHOLD_CONFIG_10" 9 "VC_THRESHOLD_CONFIG_9" 8 "VC_THRESHOLD_CONFIG_8" 7 "VC_THRESHOLD_CONFIG_7" 6 "VC_THRESHOLD_CONFIG_6" 5 "VC_THRESHOLD_CONFIG_5" 4 "VC_THRESHOLD_CONFIG_4" 3 "VC_THRESHOLD_CONFIG_3" 2 "VC_THRESHOLD_CONFIG_2" 1 "VC_THRESHOLD_CONFIG_1" 0 "SNA" ;
VAL_ 661 UI_vcleftCfgCutoffTime1 15 "VC_THRESHOLD_CONFIG_15" 14 "VC_THRESHOLD_CONFIG_14" 13 "VC_THRESHOLD_CONFIG_13" 12 "VC_THRESHOLD_CONFIG_12" 11 "VC_THRESHOLD_CONFIG_11" 10 "VC_THRESHOLD_CONFIG_10" 9 "VC_THRESHOLD_CONFIG_9" 8 "VC_THRESHOLD_CONFIG_8" 7 "VC_THRESHOLD_CONFIG_7" 6 "VC_THRESHOLD_CONFIG_6" 5 "VC_THRESHOLD_CONFIG_5" 4 "VC_THRESHOLD_CONFIG_4" 3 "VC_THRESHOLD_CONFIG_3" 2 "VC_THRESHOLD_CONFIG_2" 1 "VC_THRESHOLD_CONFIG_1" 0 "SNA" ;
VAL_ 661 UI_vcleftCfgCutoffStaticA 65535 "SNA" ;
VAL_ 661 UI_vcleftCfgCutoffStaticB -32768 "SNA" ;
VAL_ 661 UI_vcleftCfgCutoffStaticC -32768 "SNA" ;
VAL_ 661 UI_vcleftCfgCutoffDynamicA 65535 "SNA" ;
VAL_ 661 UI_vcleftCfgCutoffDynamicB -32768 "SNA" ;
VAL_ 661 UI_vcleftCfgCutoffDynamicC -32768 "SNA" ;
VAL_ 661 UI_vcrightCfgCutoffThreshold0 15 "VC_THRESHOLD_CONFIG_15" 14 "VC_THRESHOLD_CONFIG_14" 13 "VC_THRESHOLD_CONFIG_13" 12 "VC_THRESHOLD_CONFIG_12" 11 "VC_THRESHOLD_CONFIG_11" 10 "VC_THRESHOLD_CONFIG_10" 9 "VC_THRESHOLD_CONFIG_9" 8 "VC_THRESHOLD_CONFIG_8" 7 "VC_THRESHOLD_CONFIG_7" 6 "VC_THRESHOLD_CONFIG_6" 5 "VC_THRESHOLD_CONFIG_5" 4 "VC_THRESHOLD_CONFIG_4" 3 "VC_THRESHOLD_CONFIG_3" 2 "VC_THRESHOLD_CONFIG_2" 1 "VC_THRESHOLD_CONFIG_1" 0 "SNA" ;
VAL_ 661 UI_vcrightCfgCutoffTime0 15 "VC_THRESHOLD_CONFIG_15" 14 "VC_THRESHOLD_CONFIG_14" 13 "VC_THRESHOLD_CONFIG_13" 12 "VC_THRESHOLD_CONFIG_12" 11 "VC_THRESHOLD_CONFIG_11" 10 "VC_THRESHOLD_CONFIG_10" 9 "VC_THRESHOLD_CONFIG_9" 8 "VC_THRESHOLD_CONFIG_8" 7 "VC_THRESHOLD_CONFIG_7" 6 "VC_THRESHOLD_CONFIG_6" 5 "VC_THRESHOLD_CONFIG_5" 4 "VC_THRESHOLD_CONFIG_4" 3 "VC_THRESHOLD_CONFIG_3" 2 "VC_THRESHOLD_CONFIG_2" 1 "VC_THRESHOLD_CONFIG_1" 0 "SNA" ;
VAL_ 661 UI_vcrightCfgCutoffThreshold1 15 "VC_THRESHOLD_CONFIG_15" 14 "VC_THRESHOLD_CONFIG_14" 13 "VC_THRESHOLD_CONFIG_13" 12 "VC_THRESHOLD_CONFIG_12" 11 "VC_THRESHOLD_CONFIG_11" 10 "VC_THRESHOLD_CONFIG_10" 9 "VC_THRESHOLD_CONFIG_9" 8 "VC_THRESHOLD_CONFIG_8" 7 "VC_THRESHOLD_CONFIG_7" 6 "VC_THRESHOLD_CONFIG_6" 5 "VC_THRESHOLD_CONFIG_5" 4 "VC_THRESHOLD_CONFIG_4" 3 "VC_THRESHOLD_CONFIG_3" 2 "VC_THRESHOLD_CONFIG_2" 1 "VC_THRESHOLD_CONFIG_1" 0 "SNA" ;
VAL_ 661 UI_vcrightCfgCutoffTime1 15 "VC_THRESHOLD_CONFIG_15" 14 "VC_THRESHOLD_CONFIG_14" 13 "VC_THRESHOLD_CONFIG_13" 12 "VC_THRESHOLD_CONFIG_12" 11 "VC_THRESHOLD_CONFIG_11" 10 "VC_THRESHOLD_CONFIG_10" 9 "VC_THRESHOLD_CONFIG_9" 8 "VC_THRESHOLD_CONFIG_8" 7 "VC_THRESHOLD_CONFIG_7" 6 "VC_THRESHOLD_CONFIG_6" 5 "VC_THRESHOLD_CONFIG_5" 4 "VC_THRESHOLD_CONFIG_4" 3 "VC_THRESHOLD_CONFIG_3" 2 "VC_THRESHOLD_CONFIG_2" 1 "VC_THRESHOLD_CONFIG_1" 0 "SNA" ;
VAL_ 661 UI_vcrightCfgCutoffStaticA 65535 "SNA" ;
VAL_ 661 UI_vcrightCfgCutoffStaticB -32768 "SNA" ;
VAL_ 661 UI_vcrightCfgCutoffStaticC -32768 "SNA" ;
VAL_ 661 UI_vcrightCfgCutoffDynamicA 65535 "SNA" ;
VAL_ 661 UI_vcrightCfgCutoffDynamicB -32768 "SNA" ;
VAL_ 661 UI_vcrightCfgCutoffDynamicC -32768 "SNA" ;
VAL_ 820 UI_systemPowerLimit 31 "SNA" ;
VAL_ 820 UI_pedalMap 2 "PERFORMANCE" 1 "SPORT" 0 "CHILL" ;
VAL_ 820 UI_systemTorqueLimit 63 "SNA" ;
VAL_ 820 UI_closureConfirmed 3 "TRUNK" 2 "PROX" 1 "FRUNK" 0 "NONE" ;
VAL_ 820 UI_limitMode 3 "LIMIT_SERVICE" 2 "LIMIT_FACTORY" 1 "LIMIT_VALET" 0 "LIMIT_NORMAL" ;
VAL_ 820 UI_motorOnMode 2 "MOTORONMODE_REAR_ONLY" 1 "MOTORONMODE_FRONT_ONLY" 0 "MOTORONMODE_NORMAL" ;
VAL_ 820 UI_wasteMode 3 "BURN_IN" 2 "FULL" 1 "PARTIAL" 0 "NONE" ;
VAL_ 820 UI_wasteModeRegenLimit 3 "0A" 2 "10A" 1 "30A" 0 "MAX" ;
VAL_ 820 UI_stoppingMode 2 "HOLD" 1 "CREEP" 0 "STANDARD" ;
VAL_ 820 UI_speedLimit 511 "SNA" ;
VAL_ 820 UI_enableSmartShift 2 "ENABLED_P_R_D" 1 "ENABLED_P" 0 "OFF" ;
VAL_ 820 UI_navVehParallelToRdCanContinue 2 "TRUE" 1 "FALSE" 0 "SNA" ;
VAL_ 723 UI_solarAzimuthAngle -32768 "SNA" ;
VAL_ 723 UI_solarAzimuthAngleCarRef 255 "SNA" ;
VAL_ 723 UI_isSunUp 3 "SUN_SNA" 1 "SUN_UP" 0 "SUN_DOWN" ;
VAL_ 723 UI_solarElevationAngle 127 "SNA" ;
VAL_ 851 UI_autopilotTrial 3 "ACTIVE" 2 "STOP" 1 "START" 0 "NONE" ;
VAL_ 851 UI_factoryReset 3 "CUSTOMER" 2 "DIAGNOSTIC" 1 "DEVELOPER" 0 "NONE_SNA" ;
VAL_ 851 UI_cellNetworkTechnology 15 "CELL_NETWORK_SNA" 14 "CELL_NETWORK_NGRAN" 13 "CELL_NETWORK_5GSA" 12 "CELL_NETWORK_5GNSA" 11 "CELL_NETWORK_LTE5GCN" 10 "CELL_NETWORK_WCDMA" 9 "CELL_NETWORK_CDMA" 8 "CELL_NETWORK_GSM" 7 "CELL_NETWORK_LTE" 6 "CELL_NETWORK_HSPA" 5 "CELL_NETWORK_HSUPA" 4 "CELL_NETWORK_HSDPA" 3 "CELL_NETWORK_UMTS" 2 "CELL_NETWORK_EDGE" 1 "CELL_NETWORK_GPRS" 0 "CELL_NETWORK_NONE" ;
VAL_ 851 UI_cellSignalBars 7 "SNA" 5 "FIVE" 4 "FOUR" 3 "THREE" 2 "TWO" 1 "ONE" 0 "ZERO" ;
VAL_ 851 UI_trailerModeTelltale 3 "TRAILER_MODE_TELLTALE_RED" 2 "TRAILER_MODE_TELLTALE_YELLOW" 1 "TRAILER_MODE_TELLTALE_BLUE" 0 "TRAILER_MODE_TELLTALE_OFF" ;
VAL_ 991 UI_userActivity 1 "USER_ACTIVE" 0 "USER_IDLE" ;
VAL_ 991 UI_linkState 2 "LINK_STATE_WIFI" 1 "LINK_STATE_CELL" 0 "LINK_STATE_NONE" ;
VAL_ 991 UI_sentryModeState 6 "SNA" 5 "QUIET" 4 "PANIC" 3 "AWARE" 2 "ARMED" 1 "IDLE" 0 "OFF" ;
VAL_ 991 UI_mobileAppConnected 1 "CONNECTED" 0 "NOT_CONNECTED" ;
VAL_ 991 UI_autoshiftDRState 6 "AUTOSHIFT_DR_STATE_BRAKE_GEAR_SHIFT_CONFIRMED_D" 5 "AUTOSHIFT_DR_STATE_BRAKE_GEAR_SHIFT_CONFIRMED_R" 4 "AUTOSHIFT_DR_STATE_BRAKE_STEERING_AND_BRAKE_CONFIRMED" 3 "AUTOSHIFT_DR_STATE_ONLY_STEERING_CONFIRMED" 2 "AUTOSHIFT_DR_STATE_ONLY_BRAKE_CONFIRMED" 1 "AUTOSHIFT_DR_STATE_PROMPT_SHOWING_UNCONFIRMED" 0 "AUTOSHIFT_DR_STATE_INACTIVE" ;
VAL_ 991 UI_wifiBtModuleType 4 "ELEKTRA" 3 "TCU4G" 2 "BCM4359" 1 "QCA6595" 0 "UNKNOWN" ;
VAL_ 991 UI_sohHealthStatus 3 "OK" 2 "REDUCED" 1 "NO_INTERNET" 0 "UNKNOWN" ;
VAL_ 991 UI_selfParkState 255 "SNA" 52 "SELF_PARK_USER_PAUSED" 51 "SELF_PARK_REMOTE_PRE_ABORT" 50 "SELF_PARK_RESUME" 49 "SELF_PARK_PAUSE" 48 "SELF_PARK_DV_MISMATCH" 47 "SELF_PARK_DI_PANIC" 46 "SELF_PARK_POST_ACTIVE_FAILURE" 45 "SELF_PARK_POST_ACTIVE_SUCCESS" 44 "SELF_PARK_CANCEL_AUTO_SUMMON" 43 "SELF_PARK_REMOTE_ABORT" 42 "SELF_PARK_OBSTACLE_NOT_CLEARED" 41 "SELF_PARK_OBSTACLE_CLEARED" 40 "SELF_PARK_OPEN_GATE" 39 "SELF_PARK_ACTIVE" 38 "SELF_PARK_STARTED_REVERSE" 37 "SELF_PARK_STARTED_FORWARD" 36 "SELF_PARK_NOT_STARTED_TIMEOUT" 35 "SELF_PARK_PRIMED" 34 "SELF_PARK_PREPRIMED" 33 "SELF_PARK_TURN_ON_DRIVE_RAIL" 32 "SELF_PARK_DETECT_KEY_FOB" 31 "SELF_PARK_WAKE_UP_BUSES" 30 "SELF_PARK_CONNECTING_BLUETOOTH" 29 "SELF_PARK_UNAVAILABLE_CAR_WASH_MODE" 28 "SELF_PARK_UNAVAILABLE_CAR_ALARM" 27 "SELF_PARK_UNAVAILABLE_CRASH_STATE" 26 "SELF_PARK_UNAVAILABLE_DRAG_STRIP_MODE" 25 "SELF_PARK_UNAVAILABLE_TRACK_MODE" 24 "SELF_PARK_UNAVAILABLE_SERVICE_MODE" 23 "SELF_PARK_UNAVAILABLE_DOG_MODE" 22 "SELF_PARK_UNAVAILABLE_GAME_MODE" 21 "SELF_PARK_UNAVAILABLE_BLUETOOTH_CONNECT_TIMEOUT" 20 "SELF_PARK_UNAVAILABLE_WAKEUP_TIMEOUT" 19 "SELF_PARK_UNAVAILABLE_NO_BLUETOOTH_DEVICES_PAIRED" 18 "SELF_PARK_UNAVAILABLE_BRAKE_PRESSED" 17 "SELF_PARK_UNAVAILABLE_ROAD_GRADE" 16 "SELF_PARK_UNAVAILABLE_TRAILER_MODE" 15 "SELF_PARK_UNAVAILABLE_KEY_FOB_BATTERY_LOW" 14 "SELF_PARK_UNAVAILABLE_KEY_FOB_NOT_DETECTED" 13 "SELF_PARK_UNAVAILABLE_PARK_SENSOR_ISSUE" 12 "SELF_PARK_UNAVAILABLE_AUTOSTEER_NOT_ENABLED" 11 "SELF_PARK_UNAVAILABLE_LV_BUS_SUPPORT_ISSUE" 10 "SELF_PARK_UNAVAILABLE_ON_PUBLIC_ROAD" 9 "SELF_PARK_UNAVAILABLE_PARKED_TOO_LONG" 8 "SELF_PARK_UNAVAILABLE_DOOR_OPEN" 7 "SELF_PARK_UNAVAILABLE_TRUNK_OPEN" 6 "SELF_PARK_UNAVAILABLE_FRUNK_OPEN" 5 "SELF_PARK_UNAVAILABLE_PLUGGED_IN" 4 "SELF_PARK_UNAVAILABLE_NOT_PARKED" 3 "SELF_PARK_UNAVAILABLE" 2 "SELF_PARK_IDLE" 1 "SELF_PARK_DRIVING" 0 "SELF_PARK_DISABLED" ;
VAL_ 991 UI_summonDeviceIndex 3 "UNKNOWN" 2 "DEVICE_2" 1 "DEVICE_1" 0 "DEVICE_0" ;
VAL_ 663 UI_adaptiveRideRequest 3 "ADAPTIVE_RIDE_REQUEST_ADVANCED" 2 "ADAPTIVE_RIDE_REQUEST_SPORT" 1 "ADAPTIVE_RIDE_REQUEST_AUTO" 0 "ADAPTIVE_RIDE_REQUEST_COMFORT" ;
VAL_ 663 UI_suspensionLoweringRequest 3 "SNA" 2 "AUTO" 1 "ALWAYS" 0 "NEVER" ;
VAL_ 663 UI_geofenceLevelingRequest 5 "GEOFENCE_LEVELING_REQUEST_SNA" 4 "GEOFENCE_LEVELING_REQUEST_VERY_HIGH_PERSIST" 3 "GEOFENCE_LEVELING_REQUEST_HIGH_PERSIST" 2 "GEOFENCE_LEVELING_REQUEST_VERY_HIGH_TEMPORARY" 1 "GEOFENCE_LEVELING_REQUEST_HIGH_TEMPORARY" 0 "GEOFENCE_LEVELING_REQUEST_NONE" ;
VAL_ 663 UI_jackModeToggleRequest 1 "ACTIVE" 0 "NONE" ;
VAL_ 663 UI_roadRoughnessLookahead 127 "SNA" ;
VAL_ 663 UI_roadRoughnessStart 31 "SNA" ;
VAL_ 663 UI_mapVersionUsed 255 "SNA" ;
VAL_ 663 UI_suspensionLevelRequest 7 "VERY_HIGH_LEVEL_PERSIST" 6 "HIGH_LEVEL_PERSIST" 5 "VERY_HIGH_LEVEL_TEMPORARY" 4 "HIGH_LEVEL_TEMPORARY" 3 "STANDARD_LEVEL" 2 "LOW_LEVEL" 1 "VERY_LOW_LEVEL" 0 "NONE" ;
VAL_ 787 UI_trackModeRequest 2 "TRACK_MODE_REQUEST_OFF" 1 "TRACK_MODE_REQUEST_ON" 0 "TRACK_MODE_REQUEST_IDLE" ;
VAL_ 787 UI_trackPostCooling 1 "ON" 0 "OFF" ;
VAL_ 787 UI_trackCmpOverclock 1 "ON" 0 "OFF" ;
VAL_ 787 UI_trackModeBrakeTemps 1 "ON" 0 "OFF" ;
VAL_ 787 UI_trackDrivePowerAvailability 2 "TRACK_MODE_POWER_MAX" 1 "TRACK_MODE_POWER_MIDDLE" 0 "TRACK_MODE_POWER_ENDURANCE" ;
VAL_ 839 UI_navFastchargerType 4 "V4" 3 "V3" 2 "V2" 1 "LOW_POWER" 0 "NONE" ;
VAL_ 839 UI_battPreconditionOnNavState 3 "ACTIVE_COOL" 2 "PASSIVE_COOL" 1 "ACTIVE_HEAT" 0 "PASSIVE_HEAT" ;
VAL_ 839 UI_battPreconditionOnNavPowerReq 127 "SNA" 126 "MAX" -126 "MIN" ;
VAL_ 839 UI_battPreconditionOnNavTargetT 255 "SNA" 254 "MAX" 0 "MIN" ;
VAL_ 839 UI_ambientTempAtDestination -128 "SNA" ;
VAL_ 839 UI_energyAtDestination -32767 "TRIP_TOO_LONG" -32768 "SNA" ;
VAL_ 627 UI_powerStateRequest 3 "DRIVE_SUMMON" 2 "ACCESSORY_PLUS" 1 "ACCESSORY" 0 "IDLE" ;
VAL_ 627 UI_wiperMode 3 "WIPER_MODE_PARK" 2 "WIPER_MODE_NORMAL" 1 "WIPER_MODE_SERVICE" 0 "WIPER_MODE_SNA" ;
VAL_ 627 UI_steeringBacklightEnabled 1 "ENABLED" 0 "DISABLED" ;
VAL_ 627 UI_steeringButtonMode 7 "STEERING_BUTTON_MODE_SEATS" 6 "STEERING_BUTTON_MODE_WIPERS" 5 "STEERING_BUTTON_MODE_HEADLIGHT_RIGHT" 4 "STEERING_BUTTON_MODE_HEADLIGHT_LEFT" 3 "STEERING_BUTTON_MODE_MIRROR_RIGHT" 2 "STEERING_BUTTON_MODE_MIRROR_LEFT" 1 "STEERING_BUTTON_MODE_STEERING_COLUMN_ADJ" 0 "STEERING_BUTTON_MODE_OFF" ;
VAL_ 627 UI_lockRequest 7 "UI_LOCK_REQUEST_SNA" 4 "UI_LOCK_REQUEST_REMOTE_LOCK" 3 "UI_LOCK_REQUEST_REMOTE_UNLOCK" 2 "UI_LOCK_REQUEST_UNLOCK" 1 "UI_LOCK_REQUEST_LOCK" 0 "UI_LOCK_REQUEST_IDLE" ;
VAL_ 627 UI_mirrorFoldRequest 3 "MIRROR_FOLD_REQUEST_SNA" 2 "MIRROR_FOLD_REQUEST_PRESENT" 1 "MIRROR_FOLD_REQUEST_RETRACT" 0 "MIRROR_FOLD_REQUEST_IDLE" ;
VAL_ 627 UI_remoteStartRequest 4 "UI_REMOTE_START_REQUEST_SNA" 1 "UI_REMOTE_START_REQUEST_START" 0 "UI_REMOTE_START_REQUEST_IDLE" ;
VAL_ 627 UI_displayBrightnessLevel 255 "SNA" ;
VAL_ 627 UI_frontLeftSeatHeatReq 3 "HEATER_REQUEST_LEVEL3" 2 "HEATER_REQUEST_LEVEL2" 1 "HEATER_REQUEST_LEVEL1" 0 "HEATER_REQUEST_OFF" ;
VAL_ 627 UI_frontRightSeatHeatReq 3 "HEATER_REQUEST_LEVEL3" 2 "HEATER_REQUEST_LEVEL2" 1 "HEATER_REQUEST_LEVEL1" 0 "HEATER_REQUEST_OFF" ;
VAL_ 627 UI_rearLeftSeatHeatReq 3 "HEATER_REQUEST_LEVEL3" 2 "HEATER_REQUEST_LEVEL2" 1 "HEATER_REQUEST_LEVEL1" 0 "HEATER_REQUEST_OFF" ;
VAL_ 627 UI_rearCenterSeatHeatReq 3 "HEATER_REQUEST_LEVEL3" 2 "HEATER_REQUEST_LEVEL2" 1 "HEATER_REQUEST_LEVEL1" 0 "HEATER_REQUEST_OFF" ;
VAL_ 627 UI_rearRightSeatHeatReq 3 "HEATER_REQUEST_LEVEL3" 2 "HEATER_REQUEST_LEVEL2" 1 "HEATER_REQUEST_LEVEL1" 0 "HEATER_REQUEST_OFF" ;
VAL_ 627 UI_remoteClosureRequest 3 "UI_REMOTE_CLOSURE_REQUEST_SNA" 2 "UI_REMOTE_CLOSURE_REQUEST_FRONT_TRUNK_MOVE" 1 "UI_REMOTE_CLOSURE_REQUEST_REAR_TRUNK_MOVE" 0 "UI_REMOTE_CLOSURE_REQUEST_IDLE" ;
VAL_ 627 UI_wiperRequest 6 "WIPER_REQUEST_FAST_CONTINUOUS" 5 "WIPER_REQUEST_SLOW_CONTINUOUS" 4 "WIPER_REQUEST_FAST_INTERMITTENT" 3 "WIPER_REQUEST_SLOW_INTERMITTENT" 2 "WIPER_REQUEST_AUTO" 1 "WIPER_REQUEST_OFF" 0 "WIPER_REQUEST_SNA" ;
VAL_ 627 UI_domeLightSwitch 2 "DOME_LIGHT_SWITCH_AUTO" 1 "DOME_LIGHT_SWITCH_ON" 0 "DOME_LIGHT_SWITCH_OFF" ;
VAL_ 627 UI_driveStateRequest 1 "START" 0 "IDLE" ;
VAL_ 947 UI_lightSwitch 4 "LIGHT_SWITCH_SNA" 3 "LIGHT_SWITCH_OFF" 2 "LIGHT_SWITCH_PARKING" 1 "LIGHT_SWITCH_ON" 0 "LIGHT_SWITCH_AUTO" ;
VAL_ 947 UI_summonState 3 "ACTIVE" 2 "PRE_PRIMED" 1 "IDLE" 0 "SNA" ;
VAL_ 947 UI_autopilotPowerStateRequest 2 "AUTOPILOT_SUSPEND" 1 "AUTOPILOT_SENTRY" 0 "AUTOPILOT_NOMINAL" ;
VAL_ 947 UI_shorted12VCellTestMode 2 "ACTIVE" 1 "SHADOW" 0 "DISABLED" ;
VAL_ 947 UI_frontLeftSeatFanReq 3 "FAN_REQUEST_LEVEL3" 2 "FAN_REQUEST_LEVEL2" 1 "FAN_REQUEST_LEVEL1" 0 "FAN_REQUEST_OFF" ;
VAL_ 947 UI_frontRightSeatFanReq 3 "FAN_REQUEST_LEVEL3" 2 "FAN_REQUEST_LEVEL2" 1 "FAN_REQUEST_LEVEL1" 0 "FAN_REQUEST_OFF" ;
VAL_ 947 UI_dcr12VThreshold 12 "15_MILLIOHMS" 11 "16_MILLIOHMS" 10 "17_MILLIOHMS" 9 "18_MILLIOHMS" 8 "19_MILLIOHMS" 7 "20_MILLIOHMS" 6 "22_MILLIOHMS" 5 "24_MILLIOHMS" 4 "27_MILLIOHMS" 3 "30_MILLIOHMS" 2 "35_MILLIOHMS" 1 "40_MILLIOHMS" 0 "OFF" ;
VAL_ 947 UI_tireSeason 1 "WINTER" 0 "NON_WINTER" ;
VAL_ 947 UI_saveTireConfigReq 1 "TRUE" 0 "FALSE" ;
VAL_ 660 UI_lightFlashRequest 3 "LIGHT_FLASH_SENTRY" 2 "LIGHT_FLASH_MOBILE_APP" 1 "LIGHT_FLASH_HOMELINK" 0 "LIGHT_FLASH_INACTIVE" ;
VAL_ 660 UI_drivingSideVEH 2 "UNKNOWN" 1 "RIGHT" 0 "LEFT" ;
VAL_ 660 UI_keyPairResponse 2 "DENIED" 1 "CONFIRMED" 0 "NONE" ;
VAL_ 660 UI_steeringWheelHeatLevelReq 3 "STEERING_WHEEL_HEAT_LEVEL3" 2 "STEERING_WHEEL_HEAT_LEVEL2" 1 "STEERING_WHEEL_HEAT_LEVEL1" 0 "STEERING_WHEEL_HEAT_OFF" ;
VAL_ 660 UI_packTempLoggingRequest 1 "TRUE" 0 "FALSE" ;
VAL_ 660 UI_leftRearSeatAdjustmentRequest 6 "UI_ADJUSTABLE_FOLD_FLAT_REQUEST_STOP" 5 "UI_ADJUSTABLE_FOLD_FLAT_REQUEST_TOGGLE_FOLD" 4 "UI_ADJUSTABLE_FOLD_FLAT_REQUEST_REARWARD_FAST" 3 "UI_ADJUSTABLE_FOLD_FLAT_REQUEST_REARWARD_COMFORT" 2 "UI_ADJUSTABLE_FOLD_FLAT_REQUEST_FORWARD_FAST" 1 "UI_ADJUSTABLE_FOLD_FLAT_REQUEST_FORWARD_COMFORT" 0 "UI_ADJUSTABLE_FOLD_FLAT_REQUEST_NONE" ;
VAL_ 660 UI_rightRearSeatAdjustmentReques 6 "UI_ADJUSTABLE_FOLD_FLAT_REQUEST_STOP" 5 "UI_ADJUSTABLE_FOLD_FLAT_REQUEST_TOGGLE_FOLD" 4 "UI_ADJUSTABLE_FOLD_FLAT_REQUEST_REARWARD_FAST" 3 "UI_ADJUSTABLE_FOLD_FLAT_REQUEST_REARWARD_COMFORT" 2 "UI_ADJUSTABLE_FOLD_FLAT_REQUEST_FORWARD_FAST" 1 "UI_ADJUSTABLE_FOLD_FLAT_REQUEST_FORWARD_COMFORT" 0 "UI_ADJUSTABLE_FOLD_FLAT_REQUEST_NONE" ;
VAL_ 660 UI_etcBluetoothControl 3 "RESERVED" 2 "ON" 1 "OFF" 0 "INACTIVE" ;
VAL_ 660 UI_rearSeatChildLock 3 "UI_ADJUSTABLE_FOLD_FLAT_CHILD_LOCK_BOTH" 2 "UI_ADJUSTABLE_FOLD_FLAT_CHILD_LOCK_RIGHT" 1 "UI_ADJUSTABLE_FOLD_FLAT_CHILD_LOCK_LEFT" 0 "UI_ADJUSTABLE_FOLD_FLAT_CHILD_LOCK_NONE" ;
VAL_ 660 UI_windowRequest 6 "WINDOW_REQUEST_GOTO_RELATIVE_PERCENT" 5 "WINDOW_REQUEST_GOTO_CLOSED_CARWASH" 4 "WINDOW_REQUEST_GOTO_OPEN" 3 "WINDOW_REQUEST_GOTO_CLOSED" 2 "WINDOW_REQUEST_GOTO_VENT" 1 "WINDOW_REQUEST_GOTO_PERCENT" 0 "WINDOW_REQUEST_IDLE" ;
VAL_ 853 UI_geofencedLiftgateHeight 255 "INVALID_SNA" 1 "USE_DEFAULT" 0 "PENDING_SAVE" ;
VAL_ 644 UI_factoryMode 1 "ENABLED" 0 "DISABLED" ;
VAL_ 644 UI_transportMode 1 "TRANSPORT_MODE_ENABLED" 0 "TRANSPORT_MODE_DISABLED" ;
VAL_ 644 UI_showroomMode 1 "SHOWROOM_MODE_ENABLED" 0 "SHOWROOM_MODE_DISABLED" ;
VAL_ 644 UI_serviceMode 1 "SERVICE_MODE_ENABLED" 0 "SERVICE_MODE_DISABLED" ;
VAL_ 644 UI_diagnosticsAllowed 1 "ALLOWED" 0 "NOT_ALLOWED" ;
VAL_ 644 UI_serviceModePlus 1 "SERVICE_MODE_PLUS_ENABLED" 0 "SERVICE_MODE_PLUS_DISABLED" ;
VAL_ 644 UI_signedCmdHardLocked 1 "ENABLED" 0 "DISABLED" ;
VAL_ 644 UI_signedCmdServiceMode 1 "ENABLED" 0 "DISABLED" ;
VAL_ 644 UI_closureEasterEggStatus 3 "PLAYING" 2 "PRIMED" 1 "PRIMED_REMOTE" 0 "IDLE" ;
VAL_ 644 UI_lightShowType 5 "LIGHT_SHOW_TYPE_STANDARD_CNY24" 4 "LIGHT_SHOW_TYPE_STANDARD_THE_ARRIVAL" 3 "LIGHT_SHOW_TYPE_STANDARD_CNY23" 2 "LIGHT_SHOW_TYPE_STANDARD_AULD_LANG_SYNE" 1 "LIGHT_SHOW_TYPE_STANDARD_CAROL_OF_THE_BELLS" 0 "LIGHT_SHOW_TYPE_CUSTOM_USB" ;
VAL_ 595 UI_ventPanelControlRequestIndex 1 "1" 0 "0" ;
VAL_ 595 UI_ventPanelLeftLateralMode 2 "SWING" 1 "SPLIT" 0 "SINGLE" ;
VAL_ 595 UI_ventPanelRightLateralMode 2 "SWING" 1 "SPLIT" 0 "SINGLE" ;
VAL_ 595 UI_hvacReqActiveVents 3 "OFF" 2 "RIGHT" 1 "LEFT" 0 "BOTH" ;
VAL_ 1565 UI_weatherSvcTimeSinceLast 2047 "SNA" ;
VAL_ 1565 UI_weatherSvcTemperature 127 "SNA" 120 "MAX" -120 "MIN" ;
VAL_ 1565 UI_weatherSvcHumidity 255 "SNA" ;
VAL_ 1565 UI_weatherSvcDewPoint 255 "SNA" ;
VAL_ 1565 UI_weatherSvcCloudCover 255 "SNA" ;
VAL_ 1533 UMC_alertID 40 "a040_gndDisconnected" 39 "a039_inputOverCurrent" 38 "a038_chcVitalsFault" 37 "a037_GFCICalibration" 35 "a035_v2lHVACDetected" 34 "a034_v2lSAUnsupported" 33 "a033_chcUpdateFault" 32 "a032_chcVitalsRequestFailure" 31 "a031_relayCoilVIrrational" 30 "a030_acLostPllLock" 29 "a029_acPowerLoss" 28 "a028_processorBooted" 27 "a027_watchdogExpired" 26 "a026_vRefOutOfRange" 25 "a025_cntrOpenExpectedClose" 24 "a024_gndResistanceHigh" 23 "a023_adcSelfTest" 22 "a022_criticalRAM" 21 "a021_dataBus" 20 "a020_applicationCRC" 19 "a019_inputOTFoldback" 18 "a018_vehConnOTFoldback" 17 "a017_wallPlugOTFoldback" 16 "a016_pcbaOTFoldback" 15 "a015_SA_Connection" 14 "a014_SA_Genealogy" 13 "a013_SA_Temperature" 12 "a012_pilotFault" 11 "a011_proxDisconnected" 10 "a010_inputOT" 9 "a009_vehConnOT" 8 "a008_wallPlugOT" 7 "a007_pcbaOT" 6 "a006_contactorWelded" 5 "a005_inputUnderVoltage" 4 "a004_inputOverVoltage" 3 "a003_GFCISelfTestFault" 2 "a002_GFCITripped" 1 "a001_gndMonIntrptLineSide" 0 "ALERT_DO_NOT_USE_ZERO" ;
VAL_ 1533 UMC_alertType 1 "SET" 0 "CLEARED" ;
VAL_ 1533 UMC_a002_ccidFaultReason 4 "DC_PEAK" 3 "DC_LPF" 2 "AC_PEAK" 1 "AC_LPF" 0 "SNA" ;
VAL_ 1533 UMC_a003_faultType 1 "SELFTEST" 0 "POWERON" ;
VAL_ 1533 UMC_a006_faultType 1 "OPENED" 0 "WELDED" ;
VAL_ 1533 UMC_a018_vehConnTemp 215 "SHORTED" 214 "OPENED" ;
VAL_ 1533 UMC_a019_inputTerminalsTemp 215 "SHORTED" 214 "OPENED" ;
VAL_ 1285 SA_infoIndex 32 "Mux32" 31 "Mux31" 30 "Mux30" 29 "Mux29" 27 "Mux27" 26 "Mux26" 25 "Mux25" 11 "Mux11" 0 "Mux0" ;
VAL_ 1285 SA_region 6 "SA_REGION_INDIA" 5 "SA_REGION_SOUTH_KOREA" 4 "SA_REGION_AUSTRALIA" 3 "SA_REGION_JAPAN" 2 "SA_REGION_CHINA" 1 "SA_REGION_EU" 0 "SA_REGION_NA" ;
VAL_ 609 VCFRONT_12VBatteryStatusIndex 5 "Mux5" 4 "Mux4" 3 "Mux3" 2 "Mux2" 1 "Mux1" 0 "Mux0" ;
VAL_ 609 VCFRONT_batterySMState 10 "BATTERY_SM_STATE_EXTERNAL_LV_BUS_CONTROL" 9 "BATTERY_SM_STATE_RECOVERY" 8 "BATTERY_SM_STATE_FAULT" 7 "BATTERY_SM_STATE_SHORTED_CELL_TEST" 6 "BATTERY_SM_STATE_DISCONNECTED_BATTERY_TEST" 5 "BATTERY_SM_STATE_OTA_STANDBY" 4 "BATTERY_SM_STATE_RESISTANCE_ESTIMATION" 3 "BATTERY_SM_STATE_STANDBY" 2 "BATTERY_SM_STATE_DISCHARGE" 1 "BATTERY_SM_STATE_CHARGE" 0 "BATTERY_SM_STATE_INIT" ;
VAL_ 609 VCFRONT_eFuseRecoveryStateDBG 4 "VC_LVBMB_EFUSE_RECOVERY_STATE_BLOCKED" 3 "VC_LVBMB_EFUSE_RECOVERY_STATE_FINISH" 2 "VC_LVBMB_EFUSE_RECOVERY_STATE_CONNECT" 1 "VC_LVBMB_EFUSE_RECOVERY_STATE_SETUP" 0 "VC_LVBMB_EFUSE_RECOVERY_STATE_INACTIVE" ;
VAL_ 609 VCFRONT_batteryLINScheduleDBG 7 "VC_LVBMS_LIN_SCHEDULE_SNA" 6 "VC_LVBMS_LIN_SCHEDULE_OTHER" 4 "VC_LVBMS_LIN_SCHEDULE_DEFAULT_2" 3 "VC_LVBMS_LIN_SCHEDULE_DEFAULT_1" 2 "VC_LVBMS_LIN_SCHEDULE_DIAGNOSTIC" 1 "VC_LVBMS_LIN_SCHEDULE_RESET" 0 "VC_LVBMS_LIN_SCHEDULE_OFF" ;
VAL_ 609 VCFRONT_IBSVoltage 4095 "SNA" ;
VAL_ 609 VCFRONT_IBSTemperature 2047 "IBS_TEMPERATURE_SNA" ;
VAL_ 609 VCFRONT_LVBatteryStatusForDrive 2 "LV_BATTERY_EXIT_DRIVE_REQUESTED" 1 "LV_BATTERY_READY_FOR_DRIVE" 0 "LV_BATTERY_NOT_READY_FOR_DRIVE" ;
VAL_ 609 VCFRONT_LVBatteryType 5 "LV_BATTERY_TYPE_TESLA_48V_LI_ION" 4 "LV_BATTERY_TYPE_TESLA_16V_LI_ION" 3 "LV_BATTERY_TYPE_CATL_LI_ION" 2 "LV_BATTERY_TYPE_CLARIOS_B24_FLOODED" 1 "LV_BATTERY_TYPE_ATLASBX_B24_FLOODED" 0 "LV_BATTERY_TYPE_UNKNOWN" ;
VAL_ 609 VCFRONT_IBSVoltageFiltered 16383 "SNA" 16382 "MAX" 16381 "MIN" ;
VAL_ 609 VCFRONT_LVBMS_LVBusVoltageSource 3 "VC_LVBMS_VOLTAGE_SOURCE_LVBMS" 2 "VC_LVBMS_VOLTAGE_SOURCE_VBAT_MONITOR" 1 "VC_LVBMS_VOLTAGE_SOURCE_IBS" 0 "VC_LVBMS_VOLTAGE_SOURCE_NONE" ;
VAL_ 609 VCFRONT_LVBMS_LVPackCurrentSourc 2 "VC_LV_PACK_CURRENT_SOURCE_LVBMS" 1 "VC_LV_PACK_CURRENT_SOURCE_IBS" 0 "VC_LV_PACK_CURRENT_SOURCE_NONE" ;
VAL_ 609 VCFRONT_LVBatterySupportRqrdTrig 14336 "LV_BATTERY_SUPPORT_REQUIRED_TRIGGER_SOC_IMBALANCE_AND_CORRECTION" 12288 "LV_BATTERY_SUPPORT_REQUIRED_TRIGGER_IMBALANCE_AND_CORRECTION" 10240 "LV_BATTERY_SUPPORT_REQUIRED_TRIGGER_SOC_AND_CORRECTION" 8192 "LV_BATTERY_SUPPORT_REQUIRED_TRIGGER_CORRECTION" 6144 "LV_BATTERY_SUPPORT_REQUIRED_TRIGGER_SOC_AND_IMBALANCE" 4096 "LV_BATTERY_SUPPORT_REQUIRED_TRIGGER_IMBALANCE" 2048 "LV_BATTERY_SUPPORT_REQUIRED_TRIGGER_SOC" 1024 "LV_BATTERY_SUPPORT_REQUIRED_TRIGGER_POST_OTA" 512 "LV_BATTERY_SUPPORT_REQUIRED_TRIGGER_EXIT_TRANSPORT_MODE" 256 "LV_BATTERY_SUPPORT_REQUIRED_TRIGGER_POWER_ON_RESET" 128 "LV_BATTERY_SUPPORT_REQUIRED_TRIGGER_PERIODIC_CHARGE" 64 "LV_BATTERY_SUPPORT_REQUIRED_TRIGGER_AH_COUNT" 32 "LV_BATTERY_SUPPORT_REQUIRED_TRIGGER_UNKNOWN_VOLTAGE" 20 "LV_BATTERY_SUPPORT_REQUIRED_TRIGGER_RAW_VC_VOLTAGES" 16 "LV_BATTERY_SUPPORT_REQUIRED_TRIGGER_VBAT_RAW_VOLTAGE" 12 "LV_BATTERY_SUPPORT_REQUIRED_TRIGGER_RAW_BATTERY_VOLTAGES" 10 "LV_BATTERY_SUPPORT_REQUIRED_TRIGGER_PACK_VOLTAGES" 8 "LV_BATTERY_SUPPORT_REQUIRED_TRIGGER_PACK_RAW_VOLTAGE" 5 "LV_BATTERY_SUPPORT_REQUIRED_TRIGGER_IBS_VOLTAGES" 4 "LV_BATTERY_SUPPORT_REQUIRED_TRIGGER_IBS_RAW_VOLTAGE" 3 "LV_BATTERY_SUPPORT_REQUIRED_TRIGGER_FILTERED_VOLTAGES" 2 "LV_BATTERY_SUPPORT_REQUIRED_TRIGGER_PACK_FILTERED_VOLTAGE" 1 "LV_BATTERY_SUPPORT_REQUIRED_TRIGGER_IBS_FILTERED_VOLTAGE" 0 "LV_BATTERY_SUPPORT_REQUIRED_TRIGGER_NONE" ;
VAL_ 609 VCFRONT_voltageProfile 3 "VOLTAGE_PROFILE_ALWAYS_CLOSED_CONTACTORS" 2 "VOLTAGE_PROFILE_REDUCED_FLOAT" 1 "VOLTAGE_PROFILE_FLOAT" 0 "VOLTAGE_PROFILE_CHARGE" ;
VAL_ 609 VCFRONT_IBSVoltageRawDBG 16383 "SNA" 16382 "MAX" 16381 "MIN" ;
VAL_ 1847 VCFRONT_LVBMS_InfoIndex 5 "INVALID" 4 "SERIAL_NUMBER" 3 "BUILDTYPE" 2 "GITHASH" 1 "APP_USAGEID_CRC" 0 "PCBAID_ASSYID" ;
VAL_ 1847 VCFRONT_LVBMS_SubUsageId 65535 "SNA" ;
VAL_ 1847 VCFRONT_LVBMS_FWBuildType 4 "INFO_MFG_BUILD" 3 "INFO_TRACEABLE_CI_BUILD" 2 "INFO_LOCAL_BUILD" 1 "INFO_PLATFORM_BUILD" 0 "INFO_UNKNOWN_BUILD" ;
VAL_ 1140 VCFRONT_LVHealthStatus 3 "BACKUP_COMPROMISED" 2 "LATENT_FAULT" 1 "HEALTHY_LIMITED" 0 "DOMAIN_HEALTHY" ;
VAL_ 1140 VCFRONT_LVStatusForDrive 6 "STATUS_FOR_DRIVE_ACTIVE_DECEL" 5 "STATUS_FOR_DRIVE_PULL_TO_SHOULDER" 4 "STATUS_FOR_DRIVE_LIMP" 3 "STATUS_FOR_DRIVE_RETURN_TO_SERVICE" 2 "STATUS_FOR_DRIVE_READY_LIMITED" 1 "STATUS_FOR_DRIVE_READY" 0 "STATUS_FOR_DRIVE_NOT_READY" ;
VAL_ 1140 VCFRONT_LVPowerSecondsToSafeHarb 65535 "INDEFINITE" ;
VAL_ 1173 VCFRONT_LVHealthDebugIndex 1 "FRONT_CHECK_RESULTS_1" 0 "UNHEALTHY_REASONS" ;
VAL_ 545 VCFRONT_LVPowerStateIndex 1 "Mux1" 0 "Mux0" ;
VAL_ 545 VCFRONT_vehiclePowerState 3 "VEHICLE_POWER_STATE_DRIVE" 2 "VEHICLE_POWER_STATE_ACCESSORY" 1 "VEHICLE_POWER_STATE_CONDITIONING" 0 "VEHICLE_POWER_STATE_OFF" ;
VAL_ 545 VCFRONT_cpLVRequest 3 "LV_FAULT" 2 "LV_GOING_DOWN" 1 "LV_ON" 0 "LV_OFF" ;
VAL_ 545 VCFRONT_epasLVState 3 "LV_FAULT" 2 "LV_GOING_DOWN" 1 "LV_ON" 0 "LV_OFF" ;
VAL_ 545 VCFRONT_hvcLVRequest 3 "LV_FAULT" 2 "LV_GOING_DOWN" 1 "LV_ON" 0 "LV_OFF" ;
VAL_ 545 VCFRONT_tasLVState 3 "LV_FAULT" 2 "LV_GOING_DOWN" 1 "LV_ON" 0 "LV_OFF" ;
VAL_ 545 VCFRONT_pcsLVState 3 "LV_FAULT" 2 "LV_GOING_DOWN" 1 "LV_ON" 0 "LV_OFF" ;
VAL_ 545 VCFRONT_CMPDLVState 3 "LV_FAULT" 2 "LV_GOING_DOWN" 1 "LV_ON" 0 "LV_OFF" ;
VAL_ 545 VCFRONT_hcmlLVState 3 "LV_FAULT" 2 "LV_GOING_DOWN" 1 "LV_ON" 0 "LV_OFF" ;
VAL_ 545 VCFRONT_hcmrLVState 3 "LV_FAULT" 2 "LV_GOING_DOWN" 1 "LV_ON" 0 "LV_OFF" ;
VAL_ 545 VCFRONT_MCUAudioLVState 3 "LV_FAULT" 2 "LV_GOING_DOWN" 1 "LV_ON" 0 "LV_OFF" ;
VAL_ 545 VCFRONT_espValveLVState 3 "LV_FAULT" 2 "LV_GOING_DOWN" 1 "LV_ON" 0 "LV_OFF" ;
VAL_ 545 VCFRONT_MCUGraphicsLVState 3 "LV_FAULT" 2 "LV_GOING_DOWN" 1 "LV_ON" 0 "LV_OFF" ;
VAL_ 545 VC_hvStateRequest 7 "VC_HV_REQUEST_STATE_RESERVED" 2 "VC_HV_REQUEST_STATE_HV_UP" 1 "VC_HV_REQUEST_STATE_LV_SUPPORT_ONLY" 0 "VC_HV_REQUEST_STATE_NONE" ;
VAL_ 545 VC_persistAccPortPowerState 4 "STATE_KEEP_AWAKE_OVERRIDDEN_NOTIFY_USER" 3 "STATE_KEEP_AWAKE_ALLOW_SLEEP" 2 "STATE_KEEP_AWAKE_ACTIVE" 1 "STATE_KEEP_AWAKE_ARMED" 0 "STATE_KEEP_AWAKE_DISARMED" ;
VAL_ 700 VCFRONT_LVThermalMotorsIndex 12 "END" 11 "COOLANT_FLOW_DIAGNOSTICS" 10 "WINDMILL_1" 9 "WINDMILL_0" 8 "PUMP_BATT_2" 7 "PUMP_BATT_1" 6 "PUMP_BATT_0" 5 "PUMP_PT_2" 4 "PUMP_PT_1" 3 "PUMP_PT_0" 2 "RAD_FAN_2" 1 "RAD_FAN_1" 0 "RAD_FAN_0" ;
VAL_ 700 VCFRONT_radiatorFanState 7 "VC_mlxControllerState_MIA" 6 "VC_mlxControllerState_FAULTED" 5 "VC_mlxControllerState_UV_TEST" 4 "VC_mlxControllerState_SELF_TEST" 3 "VC_mlxControllerState_STANDBY" 2 "VC_mlxControllerState_COLD_STARTUP" 1 "VC_mlxControllerState_ENABLE" 0 "VC_mlxControllerState_IDLE" ;
VAL_ 700 VCFRONT_radiatorFanTorque 1023 "SNA" ;
VAL_ 700 VCFRONT_radiatorFanIDc 127 "SNA" ;
VAL_ 700 VCFRONT_mlxLINCurrentSchedule 2 "DIAGNOSTIC" 1 "NORMAL" 0 "OFF" ;
VAL_ 700 VCFRONT_pumpPowertrainState 7 "VC_mlxControllerState_MIA" 6 "VC_mlxControllerState_FAULTED" 5 "VC_mlxControllerState_UV_TEST" 4 "VC_mlxControllerState_SELF_TEST" 3 "VC_mlxControllerState_STANDBY" 2 "VC_mlxControllerState_COLD_STARTUP" 1 "VC_mlxControllerState_ENABLE" 0 "VC_mlxControllerState_IDLE" ;
VAL_ 700 VCFRONT_pumpPowertrainTorque 1023 "SNA" ;
VAL_ 700 VCFRONT_pumpPowertrainIDc 127 "SNA" ;
VAL_ 700 VCFRONT_pumpBatteryState 7 "VC_mlxControllerState_MIA" 6 "VC_mlxControllerState_FAULTED" 5 "VC_mlxControllerState_UV_TEST" 4 "VC_mlxControllerState_SELF_TEST" 3 "VC_mlxControllerState_STANDBY" 2 "VC_mlxControllerState_COLD_STARTUP" 1 "VC_mlxControllerState_ENABLE" 0 "VC_mlxControllerState_IDLE" ;
VAL_ 700 VCFRONT_pumpBatteryTorque 1023 "SNA" ;
VAL_ 700 VCFRONT_pumpBatteryIDc 127 "SNA" ;
VAL_ 1332 VCFRONT_alertID 649 "a649_persistAccPortPowerReqOverridden" 631 "a631_rightHeadlampFactoryFault" 630 "a630_leftHeadlampFactoryFault" 627 "a627_LVBatteryUnrecoverableByAnyDevice" 626 "a626_LVBatteryResistanceIncrease" 625 "a625_leftHeadlampInternalErrorV4" 624 "a624_rightHeadlampInternalErrorV4" 623 "a623_LVUnhealthy" 622 "a622_pumpDetectsLowCoolantFlow" 621 "a621_coolantAirPurgeIncomplete" 620 "a620_pumpAirLock" 619 "a619_frunkSwitchReleaseTimeDBG" 618 "a618_cabinCoolingCapacityLimited" 615 "a615_TLVBMS_BatteryHeaterFault" 613 "a613_selfTestsBlockingDrive" 612 "a612_LVUnhealthyLoadShed" 611 "a611_poorRadiatorHeatRejection" 610 "a610_frunkOpenFailureMetricSet" 609 "a609_autopilotDriveNotAuthed" 608 "a608_TLVBMS_BleedFetTest" 607 "a607_sleepPowerDebug" 606 "a606_chillerBattHeatingExit" 605 "a605_sleepBypassPowerOff" 601 "a601_headlampRetryInfo" 600 "a600_currentSensorMismatch" 599 "a599_LVBatteryTypeUnsupported" 598 "a598_eFuseSelfTestFailureService" 597 "a597_vcrightFastBlowPowerCutoff" 596 "a596_vcrightCurvePowerCutoff" 595 "a595_voltageSensorMismatch" 594 "a594_virtualPitchConversionDebug" 593 "a593_vcleftFastBlowPowerCutoff" 592 "a592_vcleftCurvePowerCutoff" 591 "a591_vcrightFastBlowDetection" 590 "a590_vcrightPwrRationalityCurve" 589 "a589_vcleftFastBlowDetection" 588 "a588_vcleftPwrRationalityCurve" 587 "a587_externalLVPowerSupply" 586 "a586_rightLowOrHighBeamLightCondition" 585 "a585_bothHeadlampsInternalError" 584 "a584_frunkSwitchGroupDebug" 583 "a583_frunkSwitchGroupDisagreementDebug" 582 "a582_goodForPCSPowerCycle" 581 "a581_windshieldWiperEFuseTrip" 580 "a580_rightHeadlightEFuseTrip" 579 "a579_leftHeadlightEFuseTrip" 578 "a578_vbatFusedLowCurrentFeedEFuseTrip" 577 "a577_tasEFuseTrip" 576 "a576_mcuLogicEFuseTrip" 575 "a575_frontOilPumpEFuseTrip" 574 "a574_frontDriveInverterEFuseTrip" 573 "a573_radarEFuseTrip" 572 "a572_hvacCompressorEFuseTrip" 571 "a571_headlampsAdaptedToRightHandTraffic" 570 "a570_headlampsAdaptedToLeftHandTraffic" 569 "a569_rightDaytimeRunningLightFault" 568 "a568_leftDaytimeRunningLightFault" 567 "a567_rightFrontTurnLightFault" 566 "a566_leftFrontTurnLightFault" 565 "a565_userPresenceDisplayStateMismatch" 564 "a564_leftHeadlampAimingDebug" 563 "a563_chargePortDoorOpenBlockedByBrake" 562 "a562_LVBMSModuleOvertemperature" 561 "a561_LVBMSEFuseOvertemperature" 560 "a560_compressorHighSuperheat" 559 "a559_LVBatteryLowSOC" 558 "a558_rightHeadlampAimingDebug" 557 "a557_rightHeadlampInternalErrorV3" 556 "a556_falseTriggerOfDiscnctdBatteryTest" 555 "a555_LVBatteryCellRebalancing" 553 "a553_rightHeadlampSoftShort" 552 "a552_eFuseSelfTestFailure" 551 "a551_leftHeadlampSoftShort" 550 "a550_ambientTempDelta" 549 "a549_leftHeadlampInternalErrorV3" 548 "a548_HVFaultLoadShed" 547 "a547_postCrashLoadShed" 546 "a546_leftLowOrHighBeamLightCondition" 545 "a545_LVBatteryTypeUnknown" 544 "a544_LVBatteryCommsBusTurnedOff" 543 "a543_compressorLowFlowDeliveryDetected" 542 "a542_refrigerantReclaim" 541 "a541_LVBatteryChargeOCLevel1" 540 "a540_radiatorSteamDetected" 539 "a539_ccrExvCalibInitDebug" 538 "a538_cclExvCalibInitDebug" 537 "a537_lccExvCalibInitDebug" 536 "a536_recircExvCalibInitDebug" 535 "a535_evapExvCalibInitDebug" 534 "a534_chillerExvCalibInitDebug" 533 "a533_TLVBMS_MosfetOverTemperatureFault" 532 "a532_gtwMIAInDrive" 531 "a531_lowPowerIndexFlaggedUserFacing" 530 "a530_sharpCurrentRise" 529 "a529_discnctdBatteryStateUnknown" 528 "a528_LVBatteryCommsDiscnctd" 527 "a527_LVBatteryCellImbalance" 526 "a526_pcbaOverTemperature" 525 "a525_LVBatterySWMisconfiguration" 524 "a524_rightHeadlampAimingFault" 523 "a523_eFuseThresholdsIncorrect" 522 "a522_hibernationActiveLogCapture" 521 "a521_vcleftEFuseLoadShed" 520 "a520_rightHeadlampInternalErrorV2" 519 "a519_leftHeadlampInternalErrorV2" 518 "a518_LVBMSFault_MOS_Open_packOV" 517 "a517_hibernationRecovery" 516 "a516_hibernationActive" 515 "a515_LVBMSFault_MOS_Open_cellOV" 514 "a514_LVBMSFault_MOS_Open_cellUV" 513 "a513_LVBMSFault_MOS_Open_chgOC" 512 "a512_LVBMSFault_MOS_Open_hardwareOC" 511 "a511_DCDCSaturationLoadShed" 510 "a510_LVBatteryRecoveryTimeout" 509 "a509_vcrightEFuseLoadShed" 508 "a508_TLVBMS_ImpedanceGrowth" 507 "a507_leftHeadlampAimingFault" 506 "a506_invalidRefrigerantSystemConfig" 505 "a505_BLEFrontUnderVoltage" 504 "a504_airInRefrigerantDetected" 503 "a503_TLVBMS_BrickExtendedOvFault" 502 "a502_TLVBMS_WeakShortImpedance" 501 "a501_vnf1048ConfigurationMismatch" 500 "a500_eFuseASICStateMismatch" 499 "a499_loadShedPumpFlowRequest" 498 "a498_TLVBMS_ImpedanceTestResults" 497 "a497_LVBatteryWarnDisconnect" 496 "a496_LVBatteryExitDriveWarning" 495 "a495_LVBatteryRecoveryBlocked" 494 "a494_LVBatteryTempBlockingOTA" 493 "a493_TLVBMS_SocImbalanceWarning" 492 "a492_TLVBMS_SocImbalance" 491 "a491_rightHeadlampLastPositionUpdate" 490 "a490_coolantPumpsNotIdentified" 489 "a489_ValveStuckFlagged" 488 "a488_rightHeadlampStepperMotorFault" 487 "a487_leftHeadlampLastPositionUpdate" 486 "a486_mcuGraphicsEFuseFault" 485 "a485_leftHeadlampMigrationDebug" 484 "a484_headlampLevelingRideHeightDebug" 483 "a483_leftHeadlampStepperMotorFault" 482 "a482_rightHeadlampMigrationDebug" 481 "a481_vnf1048SelfTestFailure" 480 "a480_vnf1048Fault" 479 "a479_LVBMS_ECPA_NotClosed" 478 "a478_LVBMS_MOSFET_Open" 477 "a477_LVBatteryUnrecoverableByVehicle" 476 "a476_LVBMSMIA" 475 "a475_rightHeadlampInternalError" 474 "a474_leftHeadlampInternalError" 473 "a473_rightHeadlampRangeUpdate" 472 "a472_leftHeadlampRangeUpdate" 471 "a471_hcm5Debug" 470 "a470_implausiblePdPlDetected" 469 "a469_prvPopDetected" 468 "a468_highPowerIndexFlagged" 467 "a467_lowPowerIndexFlagged" 466 "a466_highFlowIndexLowSubcoolFlagged" 465 "a465_lowFlowIndexHighSubcoolFlagged" 464 "a464_highFlowIndexHighSubcoolFlagged" 463 "a463_frunkSensorService" 462 "a462_LVBMSFault" 461 "a461_TLVBMS_SocHighAhError" 460 "a460_hardIsentropicTdFailed" 459 "a459_thermalFillAndDrive" 458 "a458_grosslyLowRefrigerant" 457 "a457_liquidTempSensIntermittent" 456 "a456_liquidPresSensIntermittent" 455 "a455_suctionTempSensIntermittent" 454 "a454_suctionPresSensIntermittent" 453 "a453_dischargeTempSensIntermittent" 452 "a452_dischargePresSensIntermittent" 451 "a451_refrigerantNotCommissioned" 450 "a450_hornSwitchNotPressedFactory" 449 "a449_hornSwitchStuckOn" 448 "a448_gtwSteeringBtnReset" 447 "a447_cabinHVACUnavailable" 446 "a446_cabinHVACUnavailableContext" 445 "a445_drv8703SpiFaultDBG" 444 "a444_drv8703Fault" 443 "a443_TLVBMS_BmbDieOverTemperature" 442 "a442_TLVBMS_SocChange" 441 "a441_TLVBMS_ResetNeededForNvmPackSwap" 440 "a440_TLVBMS_PackSNInvalidForNvm" 439 "a439_TLVBMS_PackOverTemperatureWarning" 438 "a438_TLVBMS_PackOverTemperatureFault" 437 "a437_TLVBMS_NvmRegistrationError" 436 "a436_TLVBMS_DischargeOverCurrent" 435 "a435_TLVBMS_DchgCurrentLimitExceeded" 434 "a434_TLVBMS_ConfigInitFailed" 433 "a433_TLVBMS_ConfigFromBmbModIdFailed" 432 "a432_TLVBMS_ChargeRegulationFault" 431 "a431_TLVBMS_ChargeOverCurrent" 430 "a430_TLVBMS_ChargeCurrentLimitExceeded" 429 "a429_TLVBMS_CapacityTestResults" 428 "a428_TLVBMS_CacImbalance" 427 "a427_TLVBMS_CacChange" 426 "a426_TLVBMS_BusVoltageTooLow" 425 "a425_TLVBMS_BusVoltageTooHigh" 424 "a424_TLVBMS_BrickUnderVoltageOcv" 423 "a423_TLVBMS_BrickUnderVoltageFault" 422 "a422_waitForSyncTimedOut" 421 "a421_holidayPartyUserGenerated" 420 "a420_holidayParty" 419 "a419_TLVBMS_BrickSocLow" 418 "a418_TLVBMS_BrickOverVoltageWarning" 417 "a417_TLVBMS_BrickOverVoltageFault" 416 "a416_TLVBMS_BrickOverDischarged" 415 "a415_prechargeLVLoadReduction2" 414 "a414_prechargeLVLoadReduction" 413 "a413_TLVBMS_BmbVrefWarning" 412 "a412_dcrData3" 411 "a411_LVBatteryDataCollection2" 410 "a410_LVBatteryDataCollection1" 409 "a409_invalidConfiguration" 408 "a408_standbyChargeProfileHardExit" 407 "a407_dcrMilliOhmsAboveThreshold" 406 "a406_dcrData2" 405 "a405_dcrData1" 404 "a404_resistanceEstimationHardFailure" 403 "a403_chargeExitHardCurrentLimit" 402 "a402_LVBatteryCannotSupportVehicle" 401 "a401_deadLVMinimalAhDischarged" 400 "a400_TLVBMS_BmbVrefBad" 399 "a399_frunkNeverReportedOpen" 398 "a398_tempSensorCheckInconclusive" 397 "a397_temperatureSensorCheckFault" 396 "a396_coolantLevelLowUserFacing" 395 "a395_pressureSensorCheckInconclusive" 394 "a394_pressureSensorCheckFault" 393 "a393_ambientTempNetworkSna" 392 "a392_TLVBMS_BmbHwUnderVoltageFault" 391 "a391_frunkLatchSwitchFault" 390 "a390_heatPumpModeConvergence" 389 "a389_frunkInhibitingReleaseAtSpeed" 388 "a388_shortedCell" 387 "a387_shortedCellInstc" 386 "a386_exvMotorWarning" 385 "a385_ccRightExvWarning" 384 "a384_ccLeftExvWarning" 383 "a383_lccExvWarning" 382 "a382_recircExvWarning" 381 "a381_evaporatorExvWarning" 380 "a380_chillerExvWarning" 379 "a379_shortedCellTestRunDebug" 378 "a378_wiperECUDebug" 377 "a377_wiperParkFault" 376 "a376_controllerWakeupDebug" 375 "a375_refVoltageOutOfSpec" 374 "a374_lccInletSolenoidFault" 373 "a373_chillerControlFlooding" 372 "a372_TLVBMS_BmbHwOverVoltageFault" 371 "a371_failureToPrechargeRisk" 370 "a370_noLVSupportSocTooLow" 369 "a369_reducedPowerDischarge" 368 "a368_dischargeRoutineExited" 367 "a367_dischargeRoutineEntered" 366 "a366_burnInRoutineExited" 365 "a365_burnInRoutineEntered" 364 "a364_heaterTypeEstimationChanged" 363 "a363_TLVBMS_BleedBasedWeakShort" 362 "a362_TLVBMS_AllSocCorrectionTimeout" 361 "a361_washerFluidLowMomentary" 360 "a360_ungracefulAccPlusExit" 359 "a359_postPORExcessiveAh" 358 "a358_hornOvercurrent" 357 "a357_hornUndercurrent" 356 "a356_refrigSysLockout" 355 "a355_coolantSysLockout" 354 "a354_windshieldCameraHeaterUndercurrent" 353 "a353_wiperHeaterUndercurrent" 352 "a352_audioCurrentSpikeData" 351 "a351_emergencyFrunkButtonPressIgnored" 350 "a350_espValveCurrentSenseSaturated" 349 "a349_vbatFusedFastTripSlope" 348 "a348_espFastTripSlope" 347 "a347_iboosterFastTripSlope" 346 "a346_epas3sFastTripSlope" 345 "a345_epas3pFastTripSlope" 344 "a344_pcsFastTripSlope" 343 "a343_vcrightFastTripSlope" 342 "a342_vcleftFastTripSlope" 341 "a341_vbatFusedFastTripOCMax" 340 "a340_espFastTripOCMax" 339 "a339_iboosterFastTripOCMax" 338 "a338_epas3sFastTripOCMax" 337 "a337_epas3pFastTripOCMax" 336 "a336_pcsFastTripOCMax" 335 "a335_vcrightFastTripOCMax" 334 "a334_vcleftFastTripOCMax" 333 "a333_vbatFusedSlowTripOC" 332 "a332_espSlowTripOC" 331 "a331_iboosterSlowTripOC" 330 "a330_epas3sSlowTripOC" 329 "a329_epas3pSlowTripOC" 328 "a328_pcsSlowTripOC" 327 "a327_vcrightSlowTripOC" 326 "a326_vcleftSlowTripOC" 325 "a325_vbatFusedOvertempMax" 324 "a324_espOvertempMax" 323 "a323_iboosterOvertempMax" 322 "a322_epas3sOvertempMax" 321 "a321_epas3pOvertempMax" 320 "a320_pcsOvertempMax" 319 "a319_vcrightOvertempMax" 318 "a318_vcleftOvertempMax" 317 "a317_vbatFusedOvertempSlope" 316 "a316_espOvertempSlope" 315 "a315_iboosterOvertempSlope" 314 "a314_epas3sOvertempSlope" 313 "a313_epas3pOvertempSlope" 312 "a312_pcsOvertempSlope" 311 "a311_vcrightOvertempSlope" 310 "a310_vcleftOvertempSlope" 309 "a309_frunkEmergencyReleasePressed" 308 "a308_frunkSecUnderCurrent" 307 "a307_frunkSecOverCurrent" 306 "a306_frunkPriUnderCurrent" 305 "a305_frunkPriOverCurrent" 304 "a304_frunkReleaseFailed" 303 "a303_frunkAccessPostActive" 302 "a302_wiperCommError" 301 "a301_wipersFactoryDisabled" 300 "a300_louverActuatorSwapDetected" 299 "a299_homelinkConfigurationFailed" 298 "a298_radiatorLowAirFlowDetected" 297 "a297_TLVBMS_BmbHwOverTemperatureFault" 296 "a296_turnSignalIssue" 295 "a295_rightSideRepeaterLightFault" 294 "a294_leftSideRepeaterLightFault" 293 "a293_interiorFrunkLightFault" 292 "a292_sideMarkerLightPipeFault" 291 "a291_rightFogLightFault" 290 "a290_leftFogLightFault" 289 "a289_ccRightExvFault" 288 "a288_ccLeftExvFault" 287 "a287_lccExvFault" 286 "a286_recircExvFault" 285 "a285_evaporatorExvFault" 284 "a284_chillerExvFault" 283 "a283_thmlFanLimitedByCurrent" 282 "a282_coolantLevelSensorFault" 281 "a281_alcoholInterlockBlockingDrive" 280 "a280_refrigLiquidPresSns" 279 "a279_refrigLiquidTempSns" 278 "a278_TLVBMS_BmbHwOverCurrentFault" 277 "a277_TLVBMS_BmbStatusRegError" 276 "a276_TLVBMS_BmbDataIntegrityLoss" 275 "a275_TLVBMS_BmbCommunication" 274 "a274_failureToPrechargeRisk2" 273 "a273_wiperFrictionModelFault" 271 "a271_LVBatteryPermSupported" 270 "a270_prechargeFailed" 269 "a269_drveBlckdVltgeTooLow2" 268 "a268_vbatFusedVoltageMismatch" 267 "a267_EPAS3sVoltageMismatch" 266 "a266_EPAS3pVoltageMismatch" 265 "a265_ESPVoltageMismatch" 264 "a264_iBoosterVoltageMismatch" 263 "a263_pcsVoltageMismatch" 262 "a262_vcrightVoltageMismatch" 261 "a261_vcleftVoltageMismatch" 260 "a260_deadLVBattery" 259 "a259_LVVoltageDropOnHighLoadCurrent" 258 "a258_resistanceEstimationRun" 257 "a257_portExpanderVOR" 256 "a256_compTornShaftSeal" 255 "a255_pumpPtStopped" 254 "a254_pumpBatStopped" 253 "a253_maxChrgeSssionTmeout" 252 "a252_controllerWakeup" 251 "a251_UIWakeupTrigger" 250 "a250_headlampsNotAimed" 249 "a249_coolantValveBadMode" 248 "a248_voltageOutOfSpec" 247 "a247_evapSolenoidFault" 246 "a246_pump2EFuseFault" 245 "a245_pump1EFuseFault" 244 "a244_sleepBypassFault" 243 "a243_LVOverchargeInstc" 242 "a242_drveBlckdVltgeTooLow" 241 "a241_radFanMIA" 240 "a240_lowSideCompromised" 239 "a239_thmlFanChipComms" 238 "a238_pumpPtChipComms" 237 "a237_pumpBatChipComms" 236 "a236_batTempSnsIrrational" 235 "a235_ptTempSnsIrrational" 234 "a234_autopilot2EFuseFault" 233 "a233_autopilot1EFuseFault" 232 "a232_lowSideControllerHighFdbk" 231 "a231_12VTempSensShort" 230 "a230_thmlFanFbkSanity" 229 "a229_pumpPtFbkSanity" 228 "a228_pumpBatFbkSanity" 227 "a227_radFanCompromised" 226 "a226_battPumpMIA" 225 "a225_driveBlckdByShowroom" 224 "a224_revBatChrgPmpFault" 223 "a223_12VTempSensDiscnect" 222 "a222_rightTurnLightFault" 221 "a221_leftTurnLightFault" 220 "a220_reverseBatteryFault" 219 "a219_LVVoltFloorRchd" 218 "a218_socMonitorDetectedThresholdSoc" 217 "a217_battPumpCompromised" 216 "a216_powerCutoffImminent" 215 "a215_ptPumpMIA" 214 "a214_ptPumpCompromised" 213 "a213_LVOvercharge" 212 "a212_IBSOverTemp" 211 "a211_I2CFault" 210 "a210_coolantValveCalib" 209 "a209_brakeFluidSNA" 208 "a208_brakeFluidLow" 207 "a207_vbatFusdSelfTestFail" 206 "a206_espSelfTestFail" 205 "a205_iBoosterSelfTestFail" 204 "a204_epas3sSelfTestFail" 203 "a203_epas3pSelfTestFail" 202 "a202_pcsSelfTestFail" 201 "a201_vcrightSelfTestFail" 200 "a200_vcleftSelfTestFail" 199 "a199_PRVCANUndertrminate" 198 "a198_PRVCANOverterminate" 197 "a197_prechargeDCRData3" 196 "a196_discnctdLVBattery" 195 "a195_drveBlckdVltgeTooHgh" 194 "a194_iBoosterRetry" 193 "a193_mcuAudioRetry" 192 "a192_vehicleLoadShed" 191 "a191_exitDriveLowLVBusVoltage" 190 "a190_linSchedulingInfo" 189 "a189_IBSMIA" 188 "a188_sleepFailed" 187 "a187_busesNotSleeping" 186 "a186_noDriveChgCableCon" 185 "a185_washerFluidLow" 184 "a184_cabinCoolingPerformanceAbnormal" 183 "a183_replaceLVBattery2" 182 "a182_replaceLVBattery" 181 "a181_homelinkMIA" 180 "a180_DCDCNotSupportingLVBus" 179 "a179_highLVAmpsIntoPCS" 178 "a178_compLiquidPumpOut" 177 "a177_mcuAudioEFuseFault" 176 "a176_vehicleInSelfTest" 175 "a175_ambientTempSns" 174 "a174_driveNotAuthed" 173 "a173_HVBlckdByMsmtch" 172 "a172_wsteHtBlckdByMsmtch" 171 "a171_driveBlckdByMsmtch" 170 "a170_hcmUnderVoltage" 169 "a169_hcmPhaseEnableFail" 168 "a168_hcmShortToVBAT" 167 "a167_leftHCMMIA" 166 "a166_rightHCMMIA" 165 "a165_unxpctdEFuseLckout" 164 "a164_eFuseLckoutMissing" 163 "a163_compressorDisabledFSR" 162 "a162_compressorInhibitedContext" 161 "a161_compressorSelfFault" 160 "a160_compressorInhibited" 159 "a159_coolantValveFault" 158 "a158_louverDisconnected" 157 "a157_louverBreakage" 156 "a156_louverBlockage" 155 "a155_prechargeDCRData2" 154 "a154_prechargeDCRData1" 153 "a153_userPresenceDisplayMismatchClrd" 152 "a152_thmlFanLowRPMCBang" 151 "a151_pumpPtLowRPMCBang" 150 "a150_pumpBatLowRPMCBang" 149 "a149_BLEFrontPowerCycled" 148 "a148_thmlFanSoftStall" 147 "a147_pumpPtSoftStall" 146 "a146_pumpBatSoftStall" 145 "a145_thmlFanICTransFault" 144 "a144_pumpPtICTransFault" 143 "a143_pumpBatICTransFault" 142 "a142_exvMotorFault" 141 "a141_coolantTempBatSns" 140 "a140_coolantTempPtSns" 139 "a139_refrigSuctPresSns" 138 "a138_refrigSuctTempSns" 137 "a137_refrigDischPresSns" 136 "a136_refrigDischTempSns" 135 "a135_coolantLevelLow" 134 "a134_fusedHighEFuseTrip" 133 "a133_espEFuseTrip" 132 "a132_iBoosterEFuseTrip" 131 "a131_epas3sEFuseTrip" 130 "a130_epas3pEFuseTrip" 129 "a129_pcsEFuseTrip" 128 "a128_vcrightEFuseTrip" 127 "a127_vcleftEFuseTrip" 126 "a126_thmlFanICWarning" 125 "a125_thmlFanICLatchFault" 124 "a124_pumpPtICWarning" 123 "a123_pumpPtICLatchFault" 122 "a122_pumpBatICWarning" 121 "a121_pumpBatICLatchFault" 120 "a120_DI_DRIVE_MIA" 119 "a119_SCCM_MIA" 118 "a118_VCFRONT_MIA" 117 "a117_VCLEFT_MIA" 116 "a116_VCRIGHT_MIA" 115 "a115_VCSEC_MIA" 114 "a114_ESP_MIA" 113 "a113_UI_MIA" 112 "a112_EPBL_MIA" 111 "a111_EPBR_MIA" 110 "a110_GTW_MIA" 109 "a109_RCM_MIA" 108 "a108_DIF_MIA" 107 "a107_BMS_MIA" 106 "a106_PCS_MIA" 105 "a105_TAS_MIA" 104 "a104_DAS_MIA" 103 "a103_CP_MIA" 102 "a102_PTC_MIA" 101 "a101_PM_MIA" 100 "a100_CANbus_MIA" 99 "a099_PARK_MIA" 98 "a098_DIR_MIA" 97 "a097_CMP_MIA" 96 "a096_OCS1P_MIA" 95 "a095_CHG_MIA" 94 "a094_EPAS3P_MIA" 93 "a093_VCSEATP_MIA" 92 "a092_VCSEATD_MIA" 91 "a091_CMPD_MIA" 90 "a090_APS_MIA" 89 "a089_IBST_MIA" 88 "a088_DIRER_MIA" 87 "a087_DIREL_MIA" 86 "a086_VCBATT_MIA" 85 "a085_CCCM_MIA" 84 "a084_TPMS_MIA" 83 "a083_VCLEFT_IPC_MIA" 82 "a082_VCRIGHT_IPC_MIA" 64 "a064_busSleepReqTimeout" 63 "a063_SwitchFault" 62 "a062_XCPWasConnected" 61 "a061_XCPConnected" 60 "a060_engineeringBuild" 59 "a059_inputResistanceHigh" 58 "a058_inputRHighSyncDebug" 57 "a057_HVP_MIA" 54 "a054_compressorLowFlowUserFacing" 46 "a046_Task1000msError" 45 "a045_Task100msError" 44 "a044_Task10msError" 43 "a043_Task1msError" 42 "a042_HighStackUsage" 41 "a041_HighCPULoad" 31 "a031_UDSActive" 30 "a030_ECULogUploadRequest" 29 "a029_CoreDump" 22 "a022_TaskInitError" 21 "a021_TaskSchedulerError" 17 "a017_NVMMStatusDbg" 16 "a016_NVMMRecordError" 15 "a015_NVMMError" 13 "a013_AlertManagerFault" 12 "a012_CPUReset" 10 "a010_ExtSupplyVoltError" 9 "a009_LCCPurgeAttempted" 8 "a008_adaptiveHeadlightsUnavailableStalk" 7 "a007_coolantLevelLowDTC" 6 "a006_CANTX_cyclicError" 5 "a005_CANTXError" 4 "a004_adaptiveHeadlightsUnavailable" 3 "a003_SWAssertion" 2 "a002_PowerLossReset" 1 "a001_WatchdogReset" 0 "ALERT_DO_NOT_USE_ZERO" ;
VAL_ 1332 VCFRONT_alertState 1 "SET" 0 "CLEARED" ;
